VERSION ""

NS_ :

BS_:

BU_: ETH

BO_ 1009 RCM2_alertMatrix: 8 Vector__XXX
 SG_ RCM2_matrixIndex M : 0|4@1+ (1,0) [0|0] "" Vector__XXX
 SG_ RCM2_a000_crashDetected m0 : 4|1@1+ (1,0) [0|0] "" Vector__XXX
 SG_ RCM2_a089_pretenShldRightShort m1 : 4|1@1+ (1,0) [0|0] "" Vector__XXX
 SG_ RCM2_a149_curABLeftShort m2 : 4|1@1+ (1,0) [0|0] "" Vector__XXX
 SG_ RCM2_a209_sideAB2ndRowLShort m3 : 4|1@1+ (1,0) [0|0] "" Vector__XXX
 SG_ RCM2_a303_imuAccYHgMonChlTemp m4 : 4|1@1+ (1,0) [0|0] "" Vector__XXX
 SG_ RCM2_a393_sideAccelBPilLCLosCoup m5 : 4|1@1+ (1,0) [0|0] "" Vector__XXX
 SG_ RCM2_a457_presPedProLDefect m6 : 4|1@1+ (1,0) [0|0] "" Vector__XXX
 SG_ RCM2_a521_sideAccelDPilRCrssCoup m7 : 4|1@1+ (1,0) [0|0] "" Vector__XXX
 SG_ RCM2_a609_comDItorque1ChkSm m8 : 4|1@1+ (1,0) [0|0] "" Vector__XXX
 SG_ RCM2_a669_comEPBLstatusMIA m9 : 4|1@1+ (1,0) [0|0] "" Vector__XXX
 SG_ RCM2_a825_upFrntPedProMRSht2Bat m10 : 4|1@1+ (1,0) [0|0] "" Vector__XXX
 SG_ RCM2_a001_nearDeploy m0 : 5|1@1+ (1,0) [0|0] "" Vector__XXX
 SG_ RCM2_a090_pretenShldRightCrssCou m1 : 5|1@1+ (1,0) [0|0] "" Vector__XXX
 SG_ RCM2_a150_curABLeftCrssCoup m2 : 5|1@1+ (1,0) [0|0] "" Vector__XXX
 SG_ RCM2_a210_sideAB2ndRowLCrssCoup m3 : 5|1@1+ (1,0) [0|0] "" Vector__XXX
 SG_ RCM2_a304_imuYawR8SnsrPermBG m4 : 5|1@1+ (1,0) [0|0] "" Vector__XXX
 SG_ RCM2_a394_sideAccelBPilLCommErr m5 : 5|1@1+ (1,0) [0|0] "" Vector__XXX
 SG_ RCM2_a458_presPedProLSigMon m6 : 5|1@1+ (1,0) [0|0] "" Vector__XXX
 SG_ RCM2_a522_sideAccelDPilRCommErr m7 : 5|1@1+ (1,0) [0|0] "" Vector__XXX
 SG_ RCM2_a610_comDItorque1Cntr m8 : 5|1@1+ (1,0) [0|0] "" Vector__XXX
 SG_ RCM2_a670_comEPBLstatusChkSm m9 : 5|1@1+ (1,0) [0|0] "" Vector__XXX
 SG_ RCM2_a826_upFrntPedProMROpen m10 : 5|1@1+ (1,0) [0|0] "" Vector__XXX
 SG_ RCM2_a002_airbagsUnArmed m0 : 6|1@1+ (1,0) [0|0] "" Vector__XXX
 SG_ RCM2_a091_pretenShldRightConfig m1 : 6|1@1+ (1,0) [0|0] "" Vector__XXX
 SG_ RCM2_a151_curABLeftConfig m2 : 6|1@1+ (1,0) [0|0] "" Vector__XXX
 SG_ RCM2_a211_sideAB2ndRowLConfig m3 : 6|1@1+ (1,0) [0|0] "" Vector__XXX
 SG_ RCM2_a305_imuYawR8SnsrPermInit m4 : 6|1@1+ (1,0) [0|0] "" Vector__XXX
 SG_ RCM2_a395_sideAccelBPilLInitTyp m5 : 6|1@1+ (1,0) [0|0] "" Vector__XXX
 SG_ RCM2_a460_presPedProRSht2Gnd m6 : 6|1@1+ (1,0) [0|0] "" Vector__XXX
 SG_ RCM2_a523_sideAccelDPilRInitTyp m7 : 6|1@1+ (1,0) [0|0] "" Vector__XXX
 SG_ RCM2_a611_comDItorque2MIA m8 : 6|1@1+ (1,0) [0|0] "" Vector__XXX
 SG_ RCM2_a671_comEPBLstatusCntr m9 : 6|1@1+ (1,0) [0|0] "" Vector__XXX
 SG_ RCM2_a827_upFrntPedProMRCrssCoup m10 : 6|1@1+ (1,0) [0|0] "" Vector__XXX
 SG_ RCM2_a003_warningIndicator m0 : 7|1@1+ (1,0) [0|0] "" Vector__XXX
 SG_ RCM2_a092_pretenLapLeftSht2Gnd m1 : 7|1@1+ (1,0) [0|0] "" Vector__XXX
 SG_ RCM2_a152_curABRightSht2Gnd m2 : 7|1@1+ (1,0) [0|0] "" Vector__XXX
 SG_ RCM2_a212_sideAB2ndRowRSht2Gnd m3 : 7|1@1+ (1,0) [0|0] "" Vector__XXX
 SG_ RCM2_a306_imuYawR8SnsrPermLF m4 : 7|1@1+ (1,0) [0|0] "" Vector__XXX
 SG_ RCM2_a396_sideAccelBPilLConfig m5 : 7|1@1+ (1,0) [0|0] "" Vector__XXX
 SG_ RCM2_a461_presPedProRSht2Bat m6 : 7|1@1+ (1,0) [0|0] "" Vector__XXX
 SG_ RCM2_a524_sideAccelDPilRConfig m7 : 7|1@1+ (1,0) [0|0] "" Vector__XXX
 SG_ RCM2_a612_comDItorque2ChkSm m8 : 7|1@1+ (1,0) [0|0] "" Vector__XXX
 SG_ RCM2_a672_comEPBRstatusMIA m9 : 7|1@1+ (1,0) [0|0] "" Vector__XXX
 SG_ RCM2_a828_upFrntPedProMRCommErr m10 : 7|1@1+ (1,0) [0|0] "" Vector__XXX
 SG_ RCM2_a004_crashAlgoWakeup m0 : 8|1@1+ (1,0) [0|0] "" Vector__XXX
 SG_ RCM2_a093_pretenLapLeftSht2Bat m1 : 8|1@1+ (1,0) [0|0] "" Vector__XXX
 SG_ RCM2_a153_curABRightSht2Bat m2 : 8|1@1+ (1,0) [0|0] "" Vector__XXX
 SG_ RCM2_a213_sideAB2ndRowRSht2Bat m3 : 8|1@1+ (1,0) [0|0] "" Vector__XXX
 SG_ RCM2_a307_imuYawR8ChnlMonTmpLF m4 : 8|1@1+ (1,0) [0|0] "" Vector__XXX
 SG_ RCM2_a397_sideAccelBPilLDefect m5 : 8|1@1+ (1,0) [0|0] "" Vector__XXX
 SG_ RCM2_a462_presPedProROpen m6 : 8|1@1+ (1,0) [0|0] "" Vector__XXX
 SG_ RCM2_a525_sideAccelDPilRDefect m7 : 8|1@1+ (1,0) [0|0] "" Vector__XXX
 SG_ RCM2_a613_comDItorque2Cntr m8 : 8|1@1+ (1,0) [0|0] "" Vector__XXX
 SG_ RCM2_a673_comEPBRstatusChkSm m9 : 8|1@1+ (1,0) [0|0] "" Vector__XXX
 SG_ RCM2_a829_upFrntPedProMRIntTyp m10 : 8|1@1+ (1,0) [0|0] "" Vector__XXX
 SG_ RCM2_a005_abuseImmunityThrshold m0 : 9|1@1+ (1,0) [0|0] "" Vector__XXX
 SG_ RCM2_a094_pretenLapLeftOpen m1 : 9|1@1+ (1,0) [0|0] "" Vector__XXX
 SG_ RCM2_a154_curABRightOpen m2 : 9|1@1+ (1,0) [0|0] "" Vector__XXX
 SG_ RCM2_a214_sideAB2ndRowROpen m3 : 9|1@1+ (1,0) [0|0] "" Vector__XXX
 SG_ RCM2_a308_imuPitchR8SnsrPermBG m4 : 9|1@1+ (1,0) [0|0] "" Vector__XXX
 SG_ RCM2_a398_sideAccelBPilLSigMon m5 : 9|1@1+ (1,0) [0|0] "" Vector__XXX
 SG_ RCM2_a463_presPedProRCrssCoup m6 : 9|1@1+ (1,0) [0|0] "" Vector__XXX
 SG_ RCM2_a526_sideAccelDPilRSigMon m7 : 9|1@1+ (1,0) [0|0] "" Vector__XXX
 SG_ RCM2_a614_comESP135MIA m8 : 9|1@1+ (1,0) [0|0] "" Vector__XXX
 SG_ RCM2_a674_comEPBRstatusCntr m9 : 9|1@1+ (1,0) [0|0] "" Vector__XXX
 SG_ RCM2_a830_upFrntPedProMRConfig m10 : 9|1@1+ (1,0) [0|0] "" Vector__XXX
 SG_ RCM2_a006_supplierDiagEnabled m0 : 10|1@1+ (1,0) [0|0] "" Vector__XXX
 SG_ RCM2_a095_pretenLapLeftShort m1 : 10|1@1+ (1,0) [0|0] "" Vector__XXX
 SG_ RCM2_a155_curABRightShort m2 : 10|1@1+ (1,0) [0|0] "" Vector__XXX
 SG_ RCM2_a215_sideAB2ndRowRShort m3 : 10|1@1+ (1,0) [0|0] "" Vector__XXX
 SG_ RCM2_a309_imuPitchR8SnsrPermInit m4 : 10|1@1+ (1,0) [0|0] "" Vector__XXX
 SG_ RCM2_a400_sideAccelBPilRSht2Gnd m5 : 10|1@1+ (1,0) [0|0] "" Vector__XXX
 SG_ RCM2_a464_presPedProRCommErr m6 : 10|1@1+ (1,0) [0|0] "" Vector__XXX
 SG_ RCM2_a527_upFrntSnsrCSht2Gnd m7 : 10|1@1+ (1,0) [0|0] "" Vector__XXX
 SG_ RCM2_a615_comESP135ChkSm m8 : 10|1@1+ (1,0) [0|0] "" Vector__XXX
 SG_ RCM2_a675_comUIodoMIA m9 : 10|1@1+ (1,0) [0|0] "" Vector__XXX
 SG_ RCM2_a831_upFrntPedProMRDefect m10 : 10|1@1+ (1,0) [0|0] "" Vector__XXX
 SG_ RCM2_a007_pedProCrashDetected m0 : 11|1@1+ (1,0) [0|0] "" Vector__XXX
 SG_ RCM2_a096_pretenLapLeftCrssCoup m1 : 11|1@1+ (1,0) [0|0] "" Vector__XXX
 SG_ RCM2_a156_curABRightCrssCoup m2 : 11|1@1+ (1,0) [0|0] "" Vector__XXX
 SG_ RCM2_a216_sideAB2ndRowRCrssCoup m3 : 11|1@1+ (1,0) [0|0] "" Vector__XXX
 SG_ RCM2_a310_imuPitchR8SnsrPermLF m4 : 11|1@1+ (1,0) [0|0] "" Vector__XXX
 SG_ RCM2_a401_sideAccelBPilRSht2Bat m5 : 11|1@1+ (1,0) [0|0] "" Vector__XXX
 SG_ RCM2_a465_presPedProRInitTyp m6 : 11|1@1+ (1,0) [0|0] "" Vector__XXX
 SG_ RCM2_a528_upFrntSnsrCSht2Bat m7 : 11|1@1+ (1,0) [0|0] "" Vector__XXX
 SG_ RCM2_a616_comESP135Cntr m8 : 11|1@1+ (1,0) [0|0] "" Vector__XXX
 SG_ RCM2_a676_comEPAS3PsysMIA m9 : 11|1@1+ (1,0) [0|0] "" Vector__XXX
 SG_ RCM2_a832_upFrntPedProMRSigMon m10 : 11|1@1+ (1,0) [0|0] "" Vector__XXX
 SG_ RCM2_a008_factoryMode m0 : 12|1@1+ (1,0) [0|0] "" Vector__XXX
 SG_ RCM2_a097_pretenLapLeftConfig m1 : 12|1@1+ (1,0) [0|0] "" Vector__XXX
 SG_ RCM2_a157_curABRightConfig m2 : 12|1@1+ (1,0) [0|0] "" Vector__XXX
 SG_ RCM2_a217_sideAB2ndRowRConfig m3 : 12|1@1+ (1,0) [0|0] "" Vector__XXX
 SG_ RCM2_a311_imuPitchR8ChnlMonTmpLF m4 : 12|1@1+ (1,0) [0|0] "" Vector__XXX
 SG_ RCM2_a402_sideAccelBPilROpen m5 : 12|1@1+ (1,0) [0|0] "" Vector__XXX
 SG_ RCM2_a466_presPedProRConfig m6 : 12|1@1+ (1,0) [0|0] "" Vector__XXX
 SG_ RCM2_a529_upFrntSnsrCOpen m7 : 12|1@1+ (1,0) [0|0] "" Vector__XXX
 SG_ RCM2_a617_comESP145MIA m8 : 12|1@1+ (1,0) [0|0] "" Vector__XXX
 SG_ RCM2_a677_comEPAS3PsysChkSm m9 : 12|1@1+ (1,0) [0|0] "" Vector__XXX
 SG_ RCM2_a833_pretenShldCSht2Gnd m10 : 12|1@1+ (1,0) [0|0] "" Vector__XXX
 SG_ RCM2_a009_edrDataAreaLocked m0 : 13|1@1+ (1,0) [0|0] "" Vector__XXX
 SG_ RCM2_a098_pretenLapRightSht2Gnd m1 : 13|1@1+ (1,0) [0|0] "" Vector__XXX
 SG_ RCM2_a158_preten2ndRowLSht2Gnd m2 : 13|1@1+ (1,0) [0|0] "" Vector__XXX
 SG_ RCM2_a250_ens1Sht2Bat m3 : 13|1@1+ (1,0) [0|0] "" Vector__XXX
 SG_ RCM2_a312_imuRollR8SnsrPermBG m4 : 13|1@1+ (1,0) [0|0] "" Vector__XXX
 SG_ RCM2_a403_sideAccelBPilRCrssCoup m5 : 13|1@1+ (1,0) [0|0] "" Vector__XXX
 SG_ RCM2_a467_presPedProRDefect m6 : 13|1@1+ (1,0) [0|0] "" Vector__XXX
 SG_ RCM2_a530_upFrntSnsrCCrssCoup m7 : 13|1@1+ (1,0) [0|0] "" Vector__XXX
 SG_ RCM2_a618_comESP145ChkSm m8 : 13|1@1+ (1,0) [0|0] "" Vector__XXX
 SG_ RCM2_a678_comEPAS3PsysCntr m9 : 13|1@1+ (1,0) [0|0] "" Vector__XXX
 SG_ RCM2_a834_pretenShldCSht2Bat m10 : 13|1@1+ (1,0) [0|0] "" Vector__XXX
 SG_ RCM2_a010_pedProEDRDataLocked m0 : 14|1@1+ (1,0) [0|0] "" Vector__XXX
 SG_ RCM2_a099_pretenLapRightSht2Bat m1 : 14|1@1+ (1,0) [0|0] "" Vector__XXX
 SG_ RCM2_a159_preten2ndRowLSht2Bat m2 : 14|1@1+ (1,0) [0|0] "" Vector__XXX
 SG_ RCM2_a251_ens1Sht2Gnd m3 : 14|1@1+ (1,0) [0|0] "" Vector__XXX
 SG_ RCM2_a313_imuRollR8SnsrPermInit m4 : 14|1@1+ (1,0) [0|0] "" Vector__XXX
 SG_ RCM2_a404_sideAccelBPilRCommErr m5 : 14|1@1+ (1,0) [0|0] "" Vector__XXX
 SG_ RCM2_a468_presPedProRSigMon m6 : 14|1@1+ (1,0) [0|0] "" Vector__XXX
 SG_ RCM2_a531_upFrntSnsrCCommErr m7 : 14|1@1+ (1,0) [0|0] "" Vector__XXX
 SG_ RCM2_a619_comESP145Cntr m8 : 14|1@1+ (1,0) [0|0] "" Vector__XXX
 SG_ RCM2_a679_comESPwheelSpeedsMIA m9 : 14|1@1+ (1,0) [0|0] "" Vector__XXX
 SG_ RCM2_a835_pretenShldCOpen m10 : 14|1@1+ (1,0) [0|0] "" Vector__XXX
 SG_ RCM2_a011_placeholder0 m0 : 15|1@1+ (1,0) [0|0] "" Vector__XXX
 SG_ RCM2_a100_pretenLapRightOpen m1 : 15|1@1+ (1,0) [0|0] "" Vector__XXX
 SG_ RCM2_a160_preten2ndRowLOpen m2 : 15|1@1+ (1,0) [0|0] "" Vector__XXX
 SG_ RCM2_a252_ens1Config m3 : 15|1@1+ (1,0) [0|0] "" Vector__XXX
 SG_ RCM2_a314_imuRollR8SnsrPermLF m4 : 15|1@1+ (1,0) [0|0] "" Vector__XXX
 SG_ RCM2_a405_sideAccelBPilRInitTyp m5 : 15|1@1+ (1,0) [0|0] "" Vector__XXX
 SG_ RCM2_a469_presPedProAbsolute m6 : 15|1@1+ (1,0) [0|0] "" Vector__XXX
 SG_ RCM2_a532_upFrntSnsrCInitTyp m7 : 15|1@1+ (1,0) [0|0] "" Vector__XXX
 SG_ RCM2_a620_comInvalidVehicleSpeed m8 : 15|1@1+ (1,0) [0|0] "" Vector__XXX
 SG_ RCM2_a680_comESPwheelSpeedsChkSm m9 : 15|1@1+ (1,0) [0|0] "" Vector__XXX
 SG_ RCM2_a836_pretenShldCShort m10 : 15|1@1+ (1,0) [0|0] "" Vector__XXX
 SG_ RCM2_a012_placeholder1 m0 : 16|1@1+ (1,0) [0|0] "" Vector__XXX
 SG_ RCM2_a101_pretenLapRightShort m1 : 16|1@1+ (1,0) [0|0] "" Vector__XXX
 SG_ RCM2_a161_preten2ndRowLShort m2 : 16|1@1+ (1,0) [0|0] "" Vector__XXX
 SG_ RCM2_a253_ens2Sht2Bat m3 : 16|1@1+ (1,0) [0|0] "" Vector__XXX
 SG_ RCM2_a315_imuRollR8ChnlMonTmpLF m4 : 16|1@1+ (1,0) [0|0] "" Vector__XXX
 SG_ RCM2_a406_sideAccelBPilRConfig m5 : 16|1@1+ (1,0) [0|0] "" Vector__XXX
 SG_ RCM2_a470_upFrntPedProLSht2Gnd m6 : 16|1@1+ (1,0) [0|0] "" Vector__XXX
 SG_ RCM2_a533_upFrntSnsrCConfig m7 : 16|1@1+ (1,0) [0|0] "" Vector__XXX
 SG_ RCM2_a621_comESPBMIA m8 : 16|1@1+ (1,0) [0|0] "" Vector__XXX
 SG_ RCM2_a681_comESPwheelSpeedsCntr m9 : 16|1@1+ (1,0) [0|0] "" Vector__XXX
 SG_ RCM2_a837_pretenShldCCrossC m10 : 16|1@1+ (1,0) [0|0] "" Vector__XXX
 SG_ RCM2_a013_placeholder2 m0 : 17|1@1+ (1,0) [0|0] "" Vector__XXX
 SG_ RCM2_a102_pretenLapRightCrssCoup m1 : 17|1@1+ (1,0) [0|0] "" Vector__XXX
 SG_ RCM2_a162_preten2ndRowLCrssCoup m2 : 17|1@1+ (1,0) [0|0] "" Vector__XXX
 SG_ RCM2_a254_ens2Sht2Gnd m3 : 17|1@1+ (1,0) [0|0] "" Vector__XXX
 SG_ RCM2_a316_imuAccXLgMonChlPerm m4 : 17|1@1+ (1,0) [0|0] "" Vector__XXX
 SG_ RCM2_a407_sideAccelBPilRDefect m5 : 17|1@1+ (1,0) [0|0] "" Vector__XXX
 SG_ RCM2_a471_upFrntPedProLSht2Bat m6 : 17|1@1+ (1,0) [0|0] "" Vector__XXX
 SG_ RCM2_a534_upFrntSnsrCDefect m7 : 17|1@1+ (1,0) [0|0] "" Vector__XXX
 SG_ RCM2_a622_comESPBChkSm m8 : 17|1@1+ (1,0) [0|0] "" Vector__XXX
 SG_ RCM2_a682_comDIspeedMIA m9 : 17|1@1+ (1,0) [0|0] "" Vector__XXX
 SG_ RCM2_a838_pretenShldCConfig m10 : 17|1@1+ (1,0) [0|0] "" Vector__XXX
 SG_ RCM2_a014_pedProNearDeploy m0 : 18|1@1+ (1,0) [0|0] "" Vector__XXX
 SG_ RCM2_a103_pretenLapRightConfig m1 : 18|1@1+ (1,0) [0|0] "" Vector__XXX
 SG_ RCM2_a163_preten2ndRowLCgf m2 : 18|1@1+ (1,0) [0|0] "" Vector__XXX
 SG_ RCM2_a255_ens2Config m3 : 18|1@1+ (1,0) [0|0] "" Vector__XXX
 SG_ RCM2_a317_imuAccXLgMonChlTemp m4 : 18|1@1+ (1,0) [0|0] "" Vector__XXX
 SG_ RCM2_a408_sideAccelBPilRSigMon m5 : 18|1@1+ (1,0) [0|0] "" Vector__XXX
 SG_ RCM2_a472_upFrntPedProLOpen m6 : 18|1@1+ (1,0) [0|0] "" Vector__XXX
 SG_ RCM2_a535_upFrntSnsrCSigMon m7 : 18|1@1+ (1,0) [0|0] "" Vector__XXX
 SG_ RCM2_a623_comESPBCntr m8 : 18|1@1+ (1,0) [0|0] "" Vector__XXX
 SG_ RCM2_a683_comDIspeedChkSm m9 : 18|1@1+ (1,0) [0|0] "" Vector__XXX
 SG_ RCM2_a839_preten2ndRowCSht2Gnd m10 : 18|1@1+ (1,0) [0|0] "" Vector__XXX
 SG_ RCM2_a015_noDeployCrashCal m0 : 19|1@1+ (1,0) [0|0] "" Vector__XXX
 SG_ RCM2_a104_loadLimLeftSht2Gnd m1 : 19|1@1+ (1,0) [0|0] "" Vector__XXX
 SG_ RCM2_a164_preten2ndRowRSht2Gnd m2 : 19|1@1+ (1,0) [0|0] "" Vector__XXX
 SG_ RCM2_a256_ens3Sht2Bat m3 : 19|1@1+ (1,0) [0|0] "" Vector__XXX
 SG_ RCM2_a318_imuAccYLgMonChlPerm m4 : 19|1@1+ (1,0) [0|0] "" Vector__XXX
 SG_ RCM2_a410_sideAccelCPilLSht2Gnd m5 : 19|1@1+ (1,0) [0|0] "" Vector__XXX
 SG_ RCM2_a473_upFrntPedProLCrssCoup m6 : 19|1@1+ (1,0) [0|0] "" Vector__XXX
 SG_ RCM2_a550_bucklHallLeftSht2Gnd m7 : 19|1@1+ (1,0) [0|0] "" Vector__XXX
 SG_ RCM2_a624_comESPCMIA m8 : 19|1@1+ (1,0) [0|0] "" Vector__XXX
 SG_ RCM2_a684_comDIspeedCntr m9 : 19|1@1+ (1,0) [0|0] "" Vector__XXX
 SG_ RCM2_a840_preten2ndRowCSht2Bat m10 : 19|1@1+ (1,0) [0|0] "" Vector__XXX
 SG_ RCM2_a016_noDeployPedProCal m0 : 20|1@1+ (1,0) [0|0] "" Vector__XXX
 SG_ RCM2_a105_loadLimLeftSht2Bat m1 : 20|1@1+ (1,0) [0|0] "" Vector__XXX
 SG_ RCM2_a165_preten2ndRowRSht2Bat m2 : 20|1@1+ (1,0) [0|0] "" Vector__XXX
 SG_ RCM2_a257_ens3Sht2Gnd m3 : 20|1@1+ (1,0) [0|0] "" Vector__XXX
 SG_ RCM2_a319_imuAccYLgMonChlTemp m4 : 20|1@1+ (1,0) [0|0] "" Vector__XXX
 SG_ RCM2_a411_sideAccelCPilLSht2Bat m5 : 20|1@1+ (1,0) [0|0] "" Vector__XXX
 SG_ RCM2_a474_upFrntPedProLCommErr m6 : 20|1@1+ (1,0) [0|0] "" Vector__XXX
 SG_ RCM2_a551_bucklHallLeftSht2Bat m7 : 20|1@1+ (1,0) [0|0] "" Vector__XXX
 SG_ RCM2_a625_comESPCChkSm m8 : 20|1@1+ (1,0) [0|0] "" Vector__XXX
 SG_ RCM2_a685_comDIchassControlMIA m9 : 20|1@1+ (1,0) [0|0] "" Vector__XXX
 SG_ RCM2_a841_preten2ndRowCOpen m10 : 20|1@1+ (1,0) [0|0] "" Vector__XXX
 SG_ RCM2_a017_ecuLogAvailable m0 : 21|1@1+ (1,0) [0|0] "" Vector__XXX
 SG_ RCM2_a106_loadLimLeftOpen m1 : 21|1@1+ (1,0) [0|0] "" Vector__XXX
 SG_ RCM2_a166_preten2ndRowROpen m2 : 21|1@1+ (1,0) [0|0] "" Vector__XXX
 SG_ RCM2_a258_ens3Config m3 : 21|1@1+ (1,0) [0|0] "" Vector__XXX
 SG_ RCM2_a320_imuAccZLgMonChlPerm m4 : 21|1@1+ (1,0) [0|0] "" Vector__XXX
 SG_ RCM2_a412_sideAccelCPilLOpen m5 : 21|1@1+ (1,0) [0|0] "" Vector__XXX
 SG_ RCM2_a475_upFrntPedProLIntTyp m6 : 21|1@1+ (1,0) [0|0] "" Vector__XXX
 SG_ RCM2_a552_bucklHallLeftOpen m7 : 21|1@1+ (1,0) [0|0] "" Vector__XXX
 SG_ RCM2_a626_comESPCCntr m8 : 21|1@1+ (1,0) [0|0] "" Vector__XXX
 SG_ RCM2_a686_comDIchassControlChkSm m9 : 21|1@1+ (1,0) [0|0] "" Vector__XXX
 SG_ RCM2_a842_preten2ndRowCShort m10 : 21|1@1+ (1,0) [0|0] "" Vector__XXX
 SG_ RCM2_a047_batteryESRhigh m0 : 22|1@1+ (1,0) [0|0] "" Vector__XXX
 SG_ RCM2_a107_loadLimLeftShort m1 : 22|1@1+ (1,0) [0|0] "" Vector__XXX
 SG_ RCM2_a167_preten2ndRowRShort m2 : 22|1@1+ (1,0) [0|0] "" Vector__XXX
 SG_ RCM2_a259_ens4Sht2Bat m3 : 22|1@1+ (1,0) [0|0] "" Vector__XXX
 SG_ RCM2_a321_imuAccZLgMonChlTemp m4 : 22|1@1+ (1,0) [0|0] "" Vector__XXX
 SG_ RCM2_a413_sideAccelCPilLCrssCoup m5 : 22|1@1+ (1,0) [0|0] "" Vector__XXX
 SG_ RCM2_a476_upFrntPedProLConfig m6 : 22|1@1+ (1,0) [0|0] "" Vector__XXX
 SG_ RCM2_a553_bucklHallLeftUndef m7 : 22|1@1+ (1,0) [0|0] "" Vector__XXX
 SG_ RCM2_a627_comEPBStatusMIA m8 : 22|1@1+ (1,0) [0|0] "" Vector__XXX
 SG_ RCM2_a687_comDIchassControlCntr m9 : 22|1@1+ (1,0) [0|0] "" Vector__XXX
 SG_ RCM2_a843_preten2ndRowCCrssCoup m10 : 22|1@1+ (1,0) [0|0] "" Vector__XXX
 SG_ RCM2_a048_batteryVoltageTooHigh m0 : 23|1@1+ (1,0) [0|0] "" Vector__XXX
 SG_ RCM2_a108_loadLimLeftCrssCoup m1 : 23|1@1+ (1,0) [0|0] "" Vector__XXX
 SG_ RCM2_a168_preten2ndRowRCrssCoup m2 : 23|1@1+ (1,0) [0|0] "" Vector__XXX
 SG_ RCM2_a260_ens4Sht2Gnd m3 : 23|1@1+ (1,0) [0|0] "" Vector__XXX
 SG_ RCM2_a322_imuCalibrationFailed m4 : 23|1@1+ (1,0) [0|0] "" Vector__XXX
 SG_ RCM2_a414_sideAccelCPilLCommErr m5 : 23|1@1+ (1,0) [0|0] "" Vector__XXX
 SG_ RCM2_a477_upFrntPedProLDefect m6 : 23|1@1+ (1,0) [0|0] "" Vector__XXX
 SG_ RCM2_a554_bucklHallLeftCrssCoup m7 : 23|1@1+ (1,0) [0|0] "" Vector__XXX
 SG_ RCM2_a628_comEPBStatusChkSm m8 : 23|1@1+ (1,0) [0|0] "" Vector__XXX
 SG_ RCM2_a688_comVCLEFTrestMIA m9 : 23|1@1+ (1,0) [0|0] "" Vector__XXX
 SG_ RCM2_a844_preten2ndRowCConfig m10 : 23|1@1+ (1,0) [0|0] "" Vector__XXX
 SG_ RCM2_a049_batteryVoltageTooLow m0 : 24|1@1+ (1,0) [0|0] "" Vector__XXX
 SG_ RCM2_a109_loadLimLeftConfig m1 : 24|1@1+ (1,0) [0|0] "" Vector__XXX
 SG_ RCM2_a169_preten2ndRowRCgf m2 : 24|1@1+ (1,0) [0|0] "" Vector__XXX
 SG_ RCM2_a261_ens4Config m3 : 24|1@1+ (1,0) [0|0] "" Vector__XXX
 SG_ RCM2_a323_imuCalibrationNotDone m4 : 24|1@1+ (1,0) [0|0] "" Vector__XXX
 SG_ RCM2_a415_sideAccelCPilLInitTyp m5 : 24|1@1+ (1,0) [0|0] "" Vector__XXX
 SG_ RCM2_a478_upFrntPedProLSigMon m6 : 24|1@1+ (1,0) [0|0] "" Vector__XXX
 SG_ RCM2_a555_bucklHallLeftConfig m7 : 24|1@1+ (1,0) [0|0] "" Vector__XXX
 SG_ RCM2_a629_comEPBStatusCntr m8 : 24|1@1+ (1,0) [0|0] "" Vector__XXX
 SG_ RCM2_a689_comVCLEFTrestChkSm m9 : 24|1@1+ (1,0) [0|0] "" Vector__XXX
 SG_ RCM2_a845_comUIchassisControlMIA m10 : 24|1@1+ (1,0) [0|0] "" Vector__XXX
 SG_ RCM2_a050_driverABStg1Sht2Gnd m0 : 25|1@1+ (1,0) [0|0] "" Vector__XXX
 SG_ RCM2_a110_loadLimRightSht2Gnd m1 : 25|1@1+ (1,0) [0|0] "" Vector__XXX
 SG_ RCM2_a170_curAB2ndRowLSht2Gnd m2 : 25|1@1+ (1,0) [0|0] "" Vector__XXX
 SG_ RCM2_a264_imuYawR8OffCompPosLife m3 : 25|1@1+ (1,0) [0|0] "" Vector__XXX
 SG_ RCM2_a350_upFrntSnsrLSht2Gnd m4 : 25|1@1+ (1,0) [0|0] "" Vector__XXX
 SG_ RCM2_a416_sideAccelCPilLConfig m5 : 25|1@1+ (1,0) [0|0] "" Vector__XXX
 SG_ RCM2_a480_upFrntPedProRSht2Gnd m6 : 25|1@1+ (1,0) [0|0] "" Vector__XXX
 SG_ RCM2_a556_bucklHallRightSht2Gnd m7 : 25|1@1+ (1,0) [0|0] "" Vector__XXX
 SG_ RCM2_a630_comGTWACSMIA m8 : 25|1@1+ (1,0) [0|0] "" Vector__XXX
 SG_ RCM2_a690_comVCLEFTrestCntr m9 : 25|1@1+ (1,0) [0|0] "" Vector__XXX
 SG_ RCM2_a846_comSCCMstrAnglSnsMIA m10 : 25|1@1+ (1,0) [0|0] "" Vector__XXX
 SG_ RCM2_a051_driverABStg1Sht2Bat m0 : 26|1@1+ (1,0) [0|0] "" Vector__XXX
 SG_ RCM2_a111_loadLimRightSht2Bat m1 : 26|1@1+ (1,0) [0|0] "" Vector__XXX
 SG_ RCM2_a171_curAB2ndRowLSht2Bat m2 : 26|1@1+ (1,0) [0|0] "" Vector__XXX
 SG_ RCM2_a265_imuYawR8OffCompNegLife m3 : 26|1@1+ (1,0) [0|0] "" Vector__XXX
 SG_ RCM2_a351_upFrntSnsrLSht2Bat m4 : 26|1@1+ (1,0) [0|0] "" Vector__XXX
 SG_ RCM2_a417_sideAccelCPilLDefect m5 : 26|1@1+ (1,0) [0|0] "" Vector__XXX
 SG_ RCM2_a481_upFrntPedProRSht2Bat m6 : 26|1@1+ (1,0) [0|0] "" Vector__XXX
 SG_ RCM2_a557_bucklHallRightSht2Bat m7 : 26|1@1+ (1,0) [0|0] "" Vector__XXX
 SG_ RCM2_a631_comGTWACSChkSm m8 : 26|1@1+ (1,0) [0|0] "" Vector__XXX
 SG_ RCM2_a691_comVCLEFT1rLBuckle m9 : 26|1@1+ (1,0) [0|0] "" Vector__XXX
 SG_ RCM2_a847_comDASctrlMIA m10 : 26|1@1+ (1,0) [0|0] "" Vector__XXX
 SG_ RCM2_a052_driverABStg1Open m0 : 27|1@1+ (1,0) [0|0] "" Vector__XXX
 SG_ RCM2_a112_loadLimRightOpen m1 : 27|1@1+ (1,0) [0|0] "" Vector__XXX
 SG_ RCM2_a172_curAB2ndRowLOpen m2 : 27|1@1+ (1,0) [0|0] "" Vector__XXX
 SG_ RCM2_a266_imuYawR8OffCompPosFLDC m3 : 27|1@1+ (1,0) [0|0] "" Vector__XXX
 SG_ RCM2_a352_upFrntSnsrLOpen m4 : 27|1@1+ (1,0) [0|0] "" Vector__XXX
 SG_ RCM2_a418_sideAccelCPilLSigMon m5 : 27|1@1+ (1,0) [0|0] "" Vector__XXX
 SG_ RCM2_a482_upFrntPedProROpen m6 : 27|1@1+ (1,0) [0|0] "" Vector__XXX
 SG_ RCM2_a558_bucklHallRightOpen m7 : 27|1@1+ (1,0) [0|0] "" Vector__XXX
 SG_ RCM2_a632_comGTWACSCntr m8 : 27|1@1+ (1,0) [0|0] "" Vector__XXX
 SG_ RCM2_a692_comVCLEFT2rLBuckle m9 : 27|1@1+ (1,0) [0|0] "" Vector__XXX
 SG_ RCM2_a848_comDIlocStatMIA m10 : 27|1@1+ (1,0) [0|0] "" Vector__XXX
 SG_ RCM2_a053_driverABStg1Short m0 : 28|1@1+ (1,0) [0|0] "" Vector__XXX
 SG_ RCM2_a113_loadLimRightShort m1 : 28|1@1+ (1,0) [0|0] "" Vector__XXX
 SG_ RCM2_a173_curAB2ndRowLShort m2 : 28|1@1+ (1,0) [0|0] "" Vector__XXX
 SG_ RCM2_a267_imuYawR8OffCompNegFLDC m3 : 28|1@1+ (1,0) [0|0] "" Vector__XXX
 SG_ RCM2_a353_upFrntSnsrLCrssCoup m4 : 28|1@1+ (1,0) [0|0] "" Vector__XXX
 SG_ RCM2_a420_sideAccelCPilRSht2Gnd m5 : 28|1@1+ (1,0) [0|0] "" Vector__XXX
 SG_ RCM2_a483_upFrntPedProRCrssCoup m6 : 28|1@1+ (1,0) [0|0] "" Vector__XXX
 SG_ RCM2_a559_bucklHallRightUndef m7 : 28|1@1+ (1,0) [0|0] "" Vector__XXX
 SG_ RCM2_a633_comOCS1PMIA m8 : 28|1@1+ (1,0) [0|0] "" Vector__XXX
 SG_ RCM2_a693_comVCLEFT1rLSTPS m9 : 28|1@1+ (1,0) [0|0] "" Vector__XXX
 SG_ RCM2_a849_comIBSTparty1MIA m10 : 28|1@1+ (1,0) [0|0] "" Vector__XXX
 SG_ RCM2_a054_driverABStg1CrssCoup m0 : 29|1@1+ (1,0) [0|0] "" Vector__XXX
 SG_ RCM2_a114_loadLimRightCrssCoup m1 : 29|1@1+ (1,0) [0|0] "" Vector__XXX
 SG_ RCM2_a174_curAB2ndRowLCrssCoup m2 : 29|1@1+ (1,0) [0|0] "" Vector__XXX
 SG_ RCM2_a268_imuYawR8OffCompPosSLDC m3 : 29|1@1+ (1,0) [0|0] "" Vector__XXX
 SG_ RCM2_a354_upFrntSnsrLCommErr m4 : 29|1@1+ (1,0) [0|0] "" Vector__XXX
 SG_ RCM2_a421_sideAccelCPilRSht2Bat m5 : 29|1@1+ (1,0) [0|0] "" Vector__XXX
 SG_ RCM2_a484_upFrntPedProRCommErr m6 : 29|1@1+ (1,0) [0|0] "" Vector__XXX
 SG_ RCM2_a560_bucklHallRightCrssCoup m7 : 29|1@1+ (1,0) [0|0] "" Vector__XXX
 SG_ RCM2_a634_comOCS1PChkSm m8 : 29|1@1+ (1,0) [0|0] "" Vector__XXX
 SG_ RCM2_a694_comVCRIGHTrestMIA m9 : 29|1@1+ (1,0) [0|0] "" Vector__XXX
 SG_ RCM2_a850_comVCFRONTlightingMIA m10 : 29|1@1+ (1,0) [0|0] "" Vector__XXX
 SG_ RCM2_a055_driverABStg1Config m0 : 30|1@1+ (1,0) [0|0] "" Vector__XXX
 SG_ RCM2_a115_loadLimRightConfig m1 : 30|1@1+ (1,0) [0|0] "" Vector__XXX
 SG_ RCM2_a175_curAB2ndRowLConfig m2 : 30|1@1+ (1,0) [0|0] "" Vector__XXX
 SG_ RCM2_a269_imuYawR8OffCompNegSLDC m3 : 30|1@1+ (1,0) [0|0] "" Vector__XXX
 SG_ RCM2_a355_upFrntSnsrLInitTyp m4 : 30|1@1+ (1,0) [0|0] "" Vector__XXX
 SG_ RCM2_a422_sideAccelCPilROpen m5 : 30|1@1+ (1,0) [0|0] "" Vector__XXX
 SG_ RCM2_a485_upFrntPedProRIntTyp m6 : 30|1@1+ (1,0) [0|0] "" Vector__XXX
 SG_ RCM2_a561_bucklHallRightConfig m7 : 30|1@1+ (1,0) [0|0] "" Vector__XXX
 SG_ RCM2_a635_comOCS1PCntr m8 : 30|1@1+ (1,0) [0|0] "" Vector__XXX
 SG_ RCM2_a695_comVCRIGHTrestChkSm m9 : 30|1@1+ (1,0) [0|0] "" Vector__XXX
 SG_ RCM2_a851_internalFaultTemp m10 : 30|1@1+ (1,0) [0|0] "" Vector__XXX
 SG_ RCM2_a056_driverABStg2Sht2Gnd m0 : 31|1@1+ (1,0) [0|0] "" Vector__XXX
 SG_ RCM2_a116_kneeABDrvrSht2Gnd m1 : 31|1@1+ (1,0) [0|0] "" Vector__XXX
 SG_ RCM2_a176_curAB2ndRowRSht2Gnd m2 : 31|1@1+ (1,0) [0|0] "" Vector__XXX
 SG_ RCM2_a270_imuPtchR8OffCompPosLife m3 : 31|1@1+ (1,0) [0|0] "" Vector__XXX
 SG_ RCM2_a356_upFrntSnsrLConfig m4 : 31|1@1+ (1,0) [0|0] "" Vector__XXX
 SG_ RCM2_a423_sideAccelCPilRCrssCoup m5 : 31|1@1+ (1,0) [0|0] "" Vector__XXX
 SG_ RCM2_a486_upFrntPedProRConfig m6 : 31|1@1+ (1,0) [0|0] "" Vector__XXX
 SG_ RCM2_a562_seaTrkPosLeftSht2Gnd m7 : 31|1@1+ (1,0) [0|0] "" Vector__XXX
 SG_ RCM2_a636_ocsFaulted m8 : 31|1@1+ (1,0) [0|0] "" Vector__XXX
 SG_ RCM2_a696_comVCRIGHTrestCntr m9 : 31|1@1+ (1,0) [0|0] "" Vector__XXX
 SG_ RCM2_a852_autarkyEvent m10 : 31|1@1+ (1,0) [0|0] "" Vector__XXX
 SG_ RCM2_a057_driverABStg2Sht2Bat m0 : 32|1@1+ (1,0) [0|0] "" Vector__XXX
 SG_ RCM2_a117_kneeABDrvrSht2Bat m1 : 32|1@1+ (1,0) [0|0] "" Vector__XXX
 SG_ RCM2_a177_curAB2ndRowRSht2Bat m2 : 32|1@1+ (1,0) [0|0] "" Vector__XXX
 SG_ RCM2_a271_imuPtchR8OffCompNegLife m3 : 32|1@1+ (1,0) [0|0] "" Vector__XXX
 SG_ RCM2_a357_upFrntSnsrLDefect m4 : 32|1@1+ (1,0) [0|0] "" Vector__XXX
 SG_ RCM2_a424_sideAccelCPilRCommErr m5 : 32|1@1+ (1,0) [0|0] "" Vector__XXX
 SG_ RCM2_a487_upFrntPedProRDefect m6 : 32|1@1+ (1,0) [0|0] "" Vector__XXX
 SG_ RCM2_a563_seaTrkPosLeftShtBat m7 : 32|1@1+ (1,0) [0|0] "" Vector__XXX
 SG_ RCM2_a637_ocsUnknown m8 : 32|1@1+ (1,0) [0|0] "" Vector__XXX
 SG_ RCM2_a697_comVCRIGHT1rRBuckle m9 : 32|1@1+ (1,0) [0|0] "" Vector__XXX
 SG_ RCM2_a853_ConfigParametersInconsistent m10 : 32|1@1+ (1,0) [0|0] "" Vector__XXX
 SG_ RCM2_a058_driverABStg2Open m0 : 33|1@1+ (1,0) [0|0] "" Vector__XXX
 SG_ RCM2_a118_kneeABDrvrOpen m1 : 33|1@1+ (1,0) [0|0] "" Vector__XXX
 SG_ RCM2_a178_curAB2ndRowROpen m2 : 33|1@1+ (1,0) [0|0] "" Vector__XXX
 SG_ RCM2_a272_imuPtchR8OffCompPosFLDC m3 : 33|1@1+ (1,0) [0|0] "" Vector__XXX
 SG_ RCM2_a358_upFrntSnsrLSigMon m4 : 33|1@1+ (1,0) [0|0] "" Vector__XXX
 SG_ RCM2_a425_sideAccelCPilRInitTyp m5 : 33|1@1+ (1,0) [0|0] "" Vector__XXX
 SG_ RCM2_a488_upFrntPedProRSigMon m6 : 33|1@1+ (1,0) [0|0] "" Vector__XXX
 SG_ RCM2_a564_seaTrkPosLeftOpen m7 : 33|1@1+ (1,0) [0|0] "" Vector__XXX
 SG_ RCM2_a638_comGTWodoMIA m8 : 33|1@1+ (1,0) [0|0] "" Vector__XXX
 SG_ RCM2_a698_comVCRIGHT2rRBuckle m9 : 33|1@1+ (1,0) [0|0] "" Vector__XXX
 SG_ RCM2_a854_ConfigParametersNotLearned m10 : 33|1@1+ (1,0) [0|0] "" Vector__XXX
 SG_ RCM2_a059_driverABStg2Short m0 : 34|1@1+ (1,0) [0|0] "" Vector__XXX
 SG_ RCM2_a119_kneeABDrvrShort m1 : 34|1@1+ (1,0) [0|0] "" Vector__XXX
 SG_ RCM2_a179_curAB2ndRowRShort m2 : 34|1@1+ (1,0) [0|0] "" Vector__XXX
 SG_ RCM2_a273_imuPtchR8OffCompNegFLDC m3 : 34|1@1+ (1,0) [0|0] "" Vector__XXX
 SG_ RCM2_a360_upFrntSnsrRSht2Gnd m4 : 34|1@1+ (1,0) [0|0] "" Vector__XXX
 SG_ RCM2_a426_sideAccelCPilRConfig m5 : 34|1@1+ (1,0) [0|0] "" Vector__XXX
 SG_ RCM2_a490_presRearLDoorSht2Gnd m6 : 34|1@1+ (1,0) [0|0] "" Vector__XXX
 SG_ RCM2_a565_seaTrkPosLeftUndefined m7 : 34|1@1+ (1,0) [0|0] "" Vector__XXX
 SG_ RCM2_a639_comGTWCarStateMIA m8 : 34|1@1+ (1,0) [0|0] "" Vector__XXX
 SG_ RCM2_a699_comVCRIGHTocs m9 : 34|1@1+ (1,0) [0|0] "" Vector__XXX
 SG_ RCM2_a857_comVCLEFT2rCBuckle m10 : 34|1@1+ (1,0) [0|0] "" Vector__XXX
 SG_ RCM2_a060_driverABStg2CrssCoup m0 : 35|1@1+ (1,0) [0|0] "" Vector__XXX
 SG_ RCM2_a120_kneeABDrvrCrssCoup m1 : 35|1@1+ (1,0) [0|0] "" Vector__XXX
 SG_ RCM2_a180_curAB2ndRowRCrssCoup m2 : 35|1@1+ (1,0) [0|0] "" Vector__XXX
 SG_ RCM2_a274_imuPtchR8OffCompPosSLDC m3 : 35|1@1+ (1,0) [0|0] "" Vector__XXX
 SG_ RCM2_a361_upFrntSnsrRSht2Bat m4 : 35|1@1+ (1,0) [0|0] "" Vector__XXX
 SG_ RCM2_a427_sideAccelCPilRDefect m5 : 35|1@1+ (1,0) [0|0] "" Vector__XXX
 SG_ RCM2_a491_presRearLDoorSht2Bat m6 : 35|1@1+ (1,0) [0|0] "" Vector__XXX
 SG_ RCM2_a566_seaTrkPosLeftCrssCoup m7 : 35|1@1+ (1,0) [0|0] "" Vector__XXX
 SG_ RCM2_a640_comTPMSStatusCMIA m8 : 35|1@1+ (1,0) [0|0] "" Vector__XXX
 SG_ RCM2_a700_comVCRIGHT1rRSTPS m9 : 35|1@1+ (1,0) [0|0] "" Vector__XXX
 SG_ RCM2_a858_comVCxLVPowerStateMIA m10 : 35|1@1+ (1,0) [0|0] "" Vector__XXX
 SG_ RCM2_a061_driverABStg2Config m0 : 36|1@1+ (1,0) [0|0] "" Vector__XXX
 SG_ RCM2_a121_kneeABDrvrConfig m1 : 36|1@1+ (1,0) [0|0] "" Vector__XXX
 SG_ RCM2_a181_curAB2ndRowRConfig m2 : 36|1@1+ (1,0) [0|0] "" Vector__XXX
 SG_ RCM2_a275_imuPtchR8OffCompNegSLDC m3 : 36|1@1+ (1,0) [0|0] "" Vector__XXX
 SG_ RCM2_a362_upFrntSnsrROpen m4 : 36|1@1+ (1,0) [0|0] "" Vector__XXX
 SG_ RCM2_a428_sideAccelCPilRSigMon m5 : 36|1@1+ (1,0) [0|0] "" Vector__XXX
 SG_ RCM2_a492_presRearLDoorOpen m6 : 36|1@1+ (1,0) [0|0] "" Vector__XXX
 SG_ RCM2_a567_seaTrkPosLeftConfig m7 : 36|1@1+ (1,0) [0|0] "" Vector__XXX
 SG_ RCM2_a641_comGTWCarConfigMIA m8 : 36|1@1+ (1,0) [0|0] "" Vector__XXX
 SG_ RCM2_a701_comVCSECtpmsStatusMIA m9 : 36|1@1+ (1,0) [0|0] "" Vector__XXX
 SG_ RCM2_a859_comVCxLVPowerStateChkSm m10 : 36|1@1+ (1,0) [0|0] "" Vector__XXX
 SG_ RCM2_a062_passABStg1Sht2Gnd m0 : 37|1@1+ (1,0) [0|0] "" Vector__XXX
 SG_ RCM2_a122_kneeABPassSht2Gnd m1 : 37|1@1+ (1,0) [0|0] "" Vector__XXX
 SG_ RCM2_a182_hoodActuatorRSht2Gnd m2 : 37|1@1+ (1,0) [0|0] "" Vector__XXX
 SG_ RCM2_a276_imuRollR8OffCompPosLife m3 : 37|1@1+ (1,0) [0|0] "" Vector__XXX
 SG_ RCM2_a363_upFrntSnsrRCrssCoup m4 : 37|1@1+ (1,0) [0|0] "" Vector__XXX
 SG_ RCM2_a430_presFrntLDoorSht2Gnd m5 : 37|1@1+ (1,0) [0|0] "" Vector__XXX
 SG_ RCM2_a493_presRearLDoorCrssCoup m6 : 37|1@1+ (1,0) [0|0] "" Vector__XXX
 SG_ RCM2_a568_occPROSSht2Gnd m7 : 37|1@1+ (1,0) [0|0] "" Vector__XXX
 SG_ RCM2_a642_comVINmessageMIA m8 : 37|1@1+ (1,0) [0|0] "" Vector__XXX
 SG_ RCM2_a750_linInternalTimeout m9 : 37|1@1+ (1,0) [0|0] "" Vector__XXX
 SG_ RCM2_a860_comVCxLVPowerStateCntr m10 : 37|1@1+ (1,0) [0|0] "" Vector__XXX
 SG_ RCM2_a063_passABStg1Sht2Bat m0 : 38|1@1+ (1,0) [0|0] "" Vector__XXX
 SG_ RCM2_a123_kneeABPassSht2Bat m1 : 38|1@1+ (1,0) [0|0] "" Vector__XXX
 SG_ RCM2_a183_hoodActuatorRSht2Bat m2 : 38|1@1+ (1,0) [0|0] "" Vector__XXX
 SG_ RCM2_a277_imuRollR8OffCompNegLife m3 : 38|1@1+ (1,0) [0|0] "" Vector__XXX
 SG_ RCM2_a364_upFrntSnsrRCommErr m4 : 38|1@1+ (1,0) [0|0] "" Vector__XXX
 SG_ RCM2_a431_presFrntLDoorSht2Bat m5 : 38|1@1+ (1,0) [0|0] "" Vector__XXX
 SG_ RCM2_a494_presRearLDoorCommErr m6 : 38|1@1+ (1,0) [0|0] "" Vector__XXX
 SG_ RCM2_a569_occPROSSht2Bat m7 : 38|1@1+ (1,0) [0|0] "" Vector__XXX
 SG_ RCM2_a643_comDASSafetyFrntMIA m8 : 38|1@1+ (1,0) [0|0] "" Vector__XXX
 SG_ RCM2_a799_internalFault m9 : 38|1@1+ (1,0) [0|0] "" Vector__XXX
 SG_ RCM2_a861_typeApprovalStringNotLearned m10 : 38|1@1+ (1,0) [0|0] "" Vector__XXX
 SG_ RCM2_a064_passABStg1Open m0 : 39|1@1+ (1,0) [0|0] "" Vector__XXX
 SG_ RCM2_a124_kneeABPassOpen m1 : 39|1@1+ (1,0) [0|0] "" Vector__XXX
 SG_ RCM2_a184_hoodActuatorROpen m2 : 39|1@1+ (1,0) [0|0] "" Vector__XXX
 SG_ RCM2_a278_imuRollR8OffCompPosFLDC m3 : 39|1@1+ (1,0) [0|0] "" Vector__XXX
 SG_ RCM2_a365_upFrntSnsrRInitTyp m4 : 39|1@1+ (1,0) [0|0] "" Vector__XXX
 SG_ RCM2_a432_presFrntLDoorOpen m5 : 39|1@1+ (1,0) [0|0] "" Vector__XXX
 SG_ RCM2_a495_presRearLDoorInitTyp m6 : 39|1@1+ (1,0) [0|0] "" Vector__XXX
 SG_ RCM2_a570_occPROSOpen m7 : 39|1@1+ (1,0) [0|0] "" Vector__XXX
 SG_ RCM2_a644_comDASSafetyFrntChkSm m8 : 39|1@1+ (1,0) [0|0] "" Vector__XXX
 SG_ RCM2_a800_crcFault m9 : 39|1@1+ (1,0) [0|0] "" Vector__XXX
 SG_ RCM2_a862_comPCSalertMatrixMIA m10 : 39|1@1+ (1,0) [0|0] "" Vector__XXX
 SG_ RCM2_a065_passABStg1Short m0 : 40|1@1+ (1,0) [0|0] "" Vector__XXX
 SG_ RCM2_a125_kneeABPassShort m1 : 40|1@1+ (1,0) [0|0] "" Vector__XXX
 SG_ RCM2_a185_hoodActuatorRShort m2 : 40|1@1+ (1,0) [0|0] "" Vector__XXX
 SG_ RCM2_a279_imuRollR8OffCompNegFLDC m3 : 40|1@1+ (1,0) [0|0] "" Vector__XXX
 SG_ RCM2_a366_upFrntSnsrRConfig m4 : 40|1@1+ (1,0) [0|0] "" Vector__XXX
 SG_ RCM2_a433_presFrntLDoorCrssCoup m5 : 40|1@1+ (1,0) [0|0] "" Vector__XXX
 SG_ RCM2_a496_presRearLDoorConfig m6 : 40|1@1+ (1,0) [0|0] "" Vector__XXX
 SG_ RCM2_a571_occPROSUndef m7 : 40|1@1+ (1,0) [0|0] "" Vector__XXX
 SG_ RCM2_a645_comDASSafetyFrntCntr m8 : 40|1@1+ (1,0) [0|0] "" Vector__XXX
 SG_ RCM2_a801_parameterLayoutID m9 : 40|1@1+ (1,0) [0|0] "" Vector__XXX
 SG_ RCM2_a863_comVCFRONTalertMatrixMIA m10 : 40|1@1+ (1,0) [0|0] "" Vector__XXX
 SG_ RCM2_a066_passABStg1CrssCoup m0 : 41|1@1+ (1,0) [0|0] "" Vector__XXX
 SG_ RCM2_a126_kneeABPassCrssCoup m1 : 41|1@1+ (1,0) [0|0] "" Vector__XXX
 SG_ RCM2_a186_hoodActuatorRCrssCoup m2 : 41|1@1+ (1,0) [0|0] "" Vector__XXX
 SG_ RCM2_a280_imuRollR8OffCompPosSLDC m3 : 41|1@1+ (1,0) [0|0] "" Vector__XXX
 SG_ RCM2_a367_upFrntSnsrRDefect m4 : 41|1@1+ (1,0) [0|0] "" Vector__XXX
 SG_ RCM2_a434_presFrntLDoorCommErr m5 : 41|1@1+ (1,0) [0|0] "" Vector__XXX
 SG_ RCM2_a497_presRearLDoorDefect m6 : 41|1@1+ (1,0) [0|0] "" Vector__XXX
 SG_ RCM2_a572_occPROSCrssCoup m7 : 41|1@1+ (1,0) [0|0] "" Vector__XXX
 SG_ RCM2_a646_comDIstateMIA m8 : 41|1@1+ (1,0) [0|0] "" Vector__XXX
 SG_ RCM2_a802_parameterTransferID m9 : 41|1@1+ (1,0) [0|0] "" Vector__XXX
 SG_ RCM2_a864_comGTWepochTimeMIA m10 : 41|1@1+ (1,0) [0|0] "" Vector__XXX
 SG_ RCM2_a067_passABStg1Config m0 : 42|1@1+ (1,0) [0|0] "" Vector__XXX
 SG_ RCM2_a127_kneeABPassConfig m1 : 42|1@1+ (1,0) [0|0] "" Vector__XXX
 SG_ RCM2_a187_hoodActuatorRConfig m2 : 42|1@1+ (1,0) [0|0] "" Vector__XXX
 SG_ RCM2_a281_imuRollR8OffCompNegSLDC m3 : 42|1@1+ (1,0) [0|0] "" Vector__XXX
 SG_ RCM2_a368_upFrntSnsrRSigMon m4 : 42|1@1+ (1,0) [0|0] "" Vector__XXX
 SG_ RCM2_a435_presFrntLDoorInitTyp m5 : 42|1@1+ (1,0) [0|0] "" Vector__XXX
 SG_ RCM2_a498_presRearLDoorSigMon m6 : 42|1@1+ (1,0) [0|0] "" Vector__XXX
 SG_ RCM2_a573_occPROSConfig m7 : 42|1@1+ (1,0) [0|0] "" Vector__XXX
 SG_ RCM2_a647_comDIstateChkSm m8 : 42|1@1+ (1,0) [0|0] "" Vector__XXX
 SG_ RCM2_a803_algoVerifySensorID m9 : 42|1@1+ (1,0) [0|0] "" Vector__XXX
 SG_ RCM2_a865_comVCLVBMSstatusHighMIA m10 : 42|1@1+ (1,0) [0|0] "" Vector__XXX
 SG_ RCM2_a068_passABStg2Sht2Gnd m0 : 43|1@1+ (1,0) [0|0] "" Vector__XXX
 SG_ RCM2_a128_sideAB1stRowLSht2Gnd m1 : 43|1@1+ (1,0) [0|0] "" Vector__XXX
 SG_ RCM2_a188_hoodActuatorLSht2Gnd m2 : 43|1@1+ (1,0) [0|0] "" Vector__XXX
 SG_ RCM2_a282_imuLongAOffCompPosLife m3 : 43|1@1+ (1,0) [0|0] "" Vector__XXX
 SG_ RCM2_a370_upFrntSnsrMidLSht2Gnd m4 : 43|1@1+ (1,0) [0|0] "" Vector__XXX
 SG_ RCM2_a436_presFrntLDoorConfig m5 : 43|1@1+ (1,0) [0|0] "" Vector__XXX
 SG_ RCM2_a500_presRearRDoorSht2Gnd m6 : 43|1@1+ (1,0) [0|0] "" Vector__XXX
 SG_ RCM2_a587_sbrRearNetworkSht2Gnd m7 : 43|1@1+ (1,0) [0|0] "" Vector__XXX
 SG_ RCM2_a648_comDIstateCntr m8 : 43|1@1+ (1,0) [0|0] "" Vector__XXX
 SG_ RCM2_a804_configDataInconsistent m9 : 43|1@1+ (1,0) [0|0] "" Vector__XXX
 SG_ RCM2_a866_comDASstatusMIA m10 : 43|1@1+ (1,0) [0|0] "" Vector__XXX
 SG_ RCM2_a069_passABStg2Sht2Bat m0 : 44|1@1+ (1,0) [0|0] "" Vector__XXX
 SG_ RCM2_a129_sideAB1stRowLSht2Bat m1 : 44|1@1+ (1,0) [0|0] "" Vector__XXX
 SG_ RCM2_a189_hoodActuatorLSht2Bat m2 : 44|1@1+ (1,0) [0|0] "" Vector__XXX
 SG_ RCM2_a283_imuLongAOffCompNegLife m3 : 44|1@1+ (1,0) [0|0] "" Vector__XXX
 SG_ RCM2_a371_upFrntSnsrMidLSht2Bat m4 : 44|1@1+ (1,0) [0|0] "" Vector__XXX
 SG_ RCM2_a437_presFrntLDoorDefect m5 : 44|1@1+ (1,0) [0|0] "" Vector__XXX
 SG_ RCM2_a501_presRearRDoorSht2Bat m6 : 44|1@1+ (1,0) [0|0] "" Vector__XXX
 SG_ RCM2_a588_sbrRearNetworkSht2Bat m7 : 44|1@1+ (1,0) [0|0] "" Vector__XXX
 SG_ RCM2_a649_comDIstate2MIA m8 : 44|1@1+ (1,0) [0|0] "" Vector__XXX
 SG_ RCM2_a805_swVersionWrong m9 : 44|1@1+ (1,0) [0|0] "" Vector__XXX
 SG_ RCM2_a868_headAB3rdRowRSht2Gnd m10 : 44|1@1+ (1,0) [0|0] "" Vector__XXX
 SG_ RCM2_a070_passABStg2Open m0 : 45|1@1+ (1,0) [0|0] "" Vector__XXX
 SG_ RCM2_a130_sideAB1stRowLOpen m1 : 45|1@1+ (1,0) [0|0] "" Vector__XXX
 SG_ RCM2_a190_hoodActuatorLOpen m2 : 45|1@1+ (1,0) [0|0] "" Vector__XXX
 SG_ RCM2_a284_imuLongAOffCompPosFLDC m3 : 45|1@1+ (1,0) [0|0] "" Vector__XXX
 SG_ RCM2_a372_upFrntSnsrMidLOpen m4 : 45|1@1+ (1,0) [0|0] "" Vector__XXX
 SG_ RCM2_a438_presFrntLDoorSigMon m5 : 45|1@1+ (1,0) [0|0] "" Vector__XXX
 SG_ RCM2_a502_presRearRDoorOpen m6 : 45|1@1+ (1,0) [0|0] "" Vector__XXX
 SG_ RCM2_a589_sbrRearNetworkOpen m7 : 45|1@1+ (1,0) [0|0] "" Vector__XXX
 SG_ RCM2_a650_comDIstate2ChkSm m8 : 45|1@1+ (1,0) [0|0] "" Vector__XXX
 SG_ RCM2_a806_configVINnotLearned m9 : 45|1@1+ (1,0) [0|0] "" Vector__XXX
 SG_ RCM2_a869_headAB3rdRowRSht2Bat m10 : 45|1@1+ (1,0) [0|0] "" Vector__XXX
 SG_ RCM2_a071_passABStg2Short m0 : 46|1@1+ (1,0) [0|0] "" Vector__XXX
 SG_ RCM2_a131_sideAB1stRowLShort m1 : 46|1@1+ (1,0) [0|0] "" Vector__XXX
 SG_ RCM2_a191_hoodActuatorLShort m2 : 46|1@1+ (1,0) [0|0] "" Vector__XXX
 SG_ RCM2_a285_imuLongAOffCompNegFLDC m3 : 46|1@1+ (1,0) [0|0] "" Vector__XXX
 SG_ RCM2_a373_upFrntSnsrMidLCrssCoup m4 : 46|1@1+ (1,0) [0|0] "" Vector__XXX
 SG_ RCM2_a439_presDoorAbsolute1 m5 : 46|1@1+ (1,0) [0|0] "" Vector__XXX
 SG_ RCM2_a503_presRearRDoorCrssCoup m6 : 46|1@1+ (1,0) [0|0] "" Vector__XXX
 SG_ RCM2_a590_sbrRearNetworkUndefined m7 : 46|1@1+ (1,0) [0|0] "" Vector__XXX
 SG_ RCM2_a651_comDIstate2Cntr m8 : 46|1@1+ (1,0) [0|0] "" Vector__XXX
 SG_ RCM2_a807_configVINmismatch m9 : 46|1@1+ (1,0) [0|0] "" Vector__XXX
 SG_ RCM2_a870_headAB3rdRowROpen m10 : 46|1@1+ (1,0) [0|0] "" Vector__XXX
 SG_ RCM2_a072_passABStg2CrssCoup m0 : 47|1@1+ (1,0) [0|0] "" Vector__XXX
 SG_ RCM2_a132_sideAB1stRowLCrssCoup m1 : 47|1@1+ (1,0) [0|0] "" Vector__XXX
 SG_ RCM2_a192_hoodActuatorLCrssCoup m2 : 47|1@1+ (1,0) [0|0] "" Vector__XXX
 SG_ RCM2_a286_imuLongAOffCompPosSLDC m3 : 47|1@1+ (1,0) [0|0] "" Vector__XXX
 SG_ RCM2_a374_upFrntSnsrMidLCommErr m4 : 47|1@1+ (1,0) [0|0] "" Vector__XXX
 SG_ RCM2_a440_presFrntRDoorSht2Gnd m5 : 47|1@1+ (1,0) [0|0] "" Vector__XXX
 SG_ RCM2_a504_presRearRDoorCommErr m6 : 47|1@1+ (1,0) [0|0] "" Vector__XXX
 SG_ RCM2_a591_sbrRearNetworkCrssCoup m7 : 47|1@1+ (1,0) [0|0] "" Vector__XXX
 SG_ RCM2_a652_ambientTempFaulted m8 : 47|1@1+ (1,0) [0|0] "" Vector__XXX
 SG_ RCM2_a808_configDriveNotLearned m9 : 47|1@1+ (1,0) [0|0] "" Vector__XXX
 SG_ RCM2_a871_headAB3rdRowRShort m10 : 47|1@1+ (1,0) [0|0] "" Vector__XXX
 SG_ RCM2_a073_passABStg2Config m0 : 48|1@1+ (1,0) [0|0] "" Vector__XXX
 SG_ RCM2_a133_sideAB1stRowLConfig m1 : 48|1@1+ (1,0) [0|0] "" Vector__XXX
 SG_ RCM2_a193_hoodActuatorLConfig m2 : 48|1@1+ (1,0) [0|0] "" Vector__XXX
 SG_ RCM2_a287_imuLongAOffCompNegSLDC m3 : 48|1@1+ (1,0) [0|0] "" Vector__XXX
 SG_ RCM2_a375_upFrntSnsrMidLInitTyp m4 : 48|1@1+ (1,0) [0|0] "" Vector__XXX
 SG_ RCM2_a441_presFrntRDoorSht2Bat m5 : 48|1@1+ (1,0) [0|0] "" Vector__XXX
 SG_ RCM2_a505_presRearRDoorInitTyp m6 : 48|1@1+ (1,0) [0|0] "" Vector__XXX
 SG_ RCM2_a592_sbrRearNetworkConfig m7 : 48|1@1+ (1,0) [0|0] "" Vector__XXX
 SG_ RCM2_a653_comGTWESP1MIA m8 : 48|1@1+ (1,0) [0|0] "" Vector__XXX
 SG_ RCM2_a809_configDriveMismatch m9 : 48|1@1+ (1,0) [0|0] "" Vector__XXX
 SG_ RCM2_a872_headAB3rdRowRCrossC m10 : 48|1@1+ (1,0) [0|0] "" Vector__XXX
 SG_ RCM2_a074_passActiveVentSht2Gnd m0 : 49|1@1+ (1,0) [0|0] "" Vector__XXX
 SG_ RCM2_a134_sideAB1stRowRSht2Gnd m1 : 49|1@1+ (1,0) [0|0] "" Vector__XXX
 SG_ RCM2_a194_driverABAVSht2Gnd m2 : 49|1@1+ (1,0) [0|0] "" Vector__XXX
 SG_ RCM2_a288_imuLatAcOffCompPosLife m3 : 49|1@1+ (1,0) [0|0] "" Vector__XXX
 SG_ RCM2_a376_upFrntSnsrMidLConfig m4 : 49|1@1+ (1,0) [0|0] "" Vector__XXX
 SG_ RCM2_a442_presFrntRDoorOpen m5 : 49|1@1+ (1,0) [0|0] "" Vector__XXX
 SG_ RCM2_a506_presRearRDoorConfig m6 : 49|1@1+ (1,0) [0|0] "" Vector__XXX
 SG_ RCM2_a593_driveOrientationSht2Gnd m7 : 49|1@1+ (1,0) [0|0] "" Vector__XXX
 SG_ RCM2_a654_comGTWESP1ChkSm m8 : 49|1@1+ (1,0) [0|0] "" Vector__XXX
 SG_ RCM2_a810_bootUpActionFailure m9 : 49|1@1+ (1,0) [0|0] "" Vector__XXX
 SG_ RCM2_a873_headAB3rdRowRConfig m10 : 49|1@1+ (1,0) [0|0] "" Vector__XXX
 SG_ RCM2_a075_passActiveVentSht2Bat m0 : 50|1@1+ (1,0) [0|0] "" Vector__XXX
 SG_ RCM2_a135_sideAB1stRowRSht2Bat m1 : 50|1@1+ (1,0) [0|0] "" Vector__XXX
 SG_ RCM2_a195_driverABAVSht2Bat m2 : 50|1@1+ (1,0) [0|0] "" Vector__XXX
 SG_ RCM2_a289_imuLatAcOffCompNegLife m3 : 50|1@1+ (1,0) [0|0] "" Vector__XXX
 SG_ RCM2_a377_upFrntSnsrMidLDefect m4 : 50|1@1+ (1,0) [0|0] "" Vector__XXX
 SG_ RCM2_a443_presFrntRDoorCrssCoup m5 : 50|1@1+ (1,0) [0|0] "" Vector__XXX
 SG_ RCM2_a507_presRearRDoorDefect m6 : 50|1@1+ (1,0) [0|0] "" Vector__XXX
 SG_ RCM2_a594_driveOrientationSht2Bat m7 : 50|1@1+ (1,0) [0|0] "" Vector__XXX
 SG_ RCM2_a655_comGTWESP1Cntr m8 : 50|1@1+ (1,0) [0|0] "" Vector__XXX
 SG_ RCM2_a811_comAxleSpeed m9 : 50|1@1+ (1,0) [0|0] "" Vector__XXX
 SG_ RCM2_a874_headAB3rdRowLSht2Gnd m10 : 50|1@1+ (1,0) [0|0] "" Vector__XXX
 SG_ RCM2_a076_passActiveVentOpen m0 : 51|1@1+ (1,0) [0|0] "" Vector__XXX
 SG_ RCM2_a136_sideAB1stRowROpen m1 : 51|1@1+ (1,0) [0|0] "" Vector__XXX
 SG_ RCM2_a196_driverABAVOpen m2 : 51|1@1+ (1,0) [0|0] "" Vector__XXX
 SG_ RCM2_a290_imuLatAcOffCompPosFLDC m3 : 51|1@1+ (1,0) [0|0] "" Vector__XXX
 SG_ RCM2_a378_upFrntSnsrMidLSigMon m4 : 51|1@1+ (1,0) [0|0] "" Vector__XXX
 SG_ RCM2_a444_presFrntRDoorCommErr m5 : 51|1@1+ (1,0) [0|0] "" Vector__XXX
 SG_ RCM2_a508_presRearRDoorSigMon m6 : 51|1@1+ (1,0) [0|0] "" Vector__XXX
 SG_ RCM2_a595_driveOrientationOpen m7 : 51|1@1+ (1,0) [0|0] "" Vector__XXX
 SG_ RCM2_a656_comVCSEATPrestMIA m8 : 51|1@1+ (1,0) [0|0] "" Vector__XXX
 SG_ RCM2_a812_idfMisuseMonitoringErr m9 : 51|1@1+ (1,0) [0|0] "" Vector__XXX
 SG_ RCM2_a875_headAB3rdRowLSht2Bat m10 : 51|1@1+ (1,0) [0|0] "" Vector__XXX
 SG_ RCM2_a077_passActiveVentShort m0 : 52|1@1+ (1,0) [0|0] "" Vector__XXX
 SG_ RCM2_a137_sideAB1stRowRShort m1 : 52|1@1+ (1,0) [0|0] "" Vector__XXX
 SG_ RCM2_a197_driverABAVShort m2 : 52|1@1+ (1,0) [0|0] "" Vector__XXX
 SG_ RCM2_a291_imuLatAcOffCompNegFLDC m3 : 52|1@1+ (1,0) [0|0] "" Vector__XXX
 SG_ RCM2_a380_upFrntSnsrMidRSht2Gnd m4 : 52|1@1+ (1,0) [0|0] "" Vector__XXX
 SG_ RCM2_a445_presFrntRDoorInitTyp m5 : 52|1@1+ (1,0) [0|0] "" Vector__XXX
 SG_ RCM2_a509_sideAccelDPilLSht2Gnd m6 : 52|1@1+ (1,0) [0|0] "" Vector__XXX
 SG_ RCM2_a596_driveOrientationUndefined m7 : 52|1@1+ (1,0) [0|0] "" Vector__XXX
 SG_ RCM2_a657_comVCSEATPrestChkSm m8 : 52|1@1+ (1,0) [0|0] "" Vector__XXX
 SG_ RCM2_a813_idfEnviMonitoringError m9 : 52|1@1+ (1,0) [0|0] "" Vector__XXX
 SG_ RCM2_a876_headAB3rdRowLOpen m10 : 52|1@1+ (1,0) [0|0] "" Vector__XXX
 SG_ RCM2_a078_passActiveVentCrssCoup m0 : 53|1@1+ (1,0) [0|0] "" Vector__XXX
 SG_ RCM2_a138_sideAB1stRowRCrssCoup m1 : 53|1@1+ (1,0) [0|0] "" Vector__XXX
 SG_ RCM2_a198_driverABAVCrossCoup m2 : 53|1@1+ (1,0) [0|0] "" Vector__XXX
 SG_ RCM2_a292_imuLatAcOffCompPosSLDC m3 : 53|1@1+ (1,0) [0|0] "" Vector__XXX
 SG_ RCM2_a381_upFrntSnsrMidRSht2Bat m4 : 53|1@1+ (1,0) [0|0] "" Vector__XXX
 SG_ RCM2_a446_presFrntRDoorConfig m5 : 53|1@1+ (1,0) [0|0] "" Vector__XXX
 SG_ RCM2_a510_sideAccelDPilLSht2Bat m6 : 53|1@1+ (1,0) [0|0] "" Vector__XXX
 SG_ RCM2_a597_driveOrientationCrssCoup m7 : 53|1@1+ (1,0) [0|0] "" Vector__XXX
 SG_ RCM2_a658_comVCSEATPrestCntr m8 : 53|1@1+ (1,0) [0|0] "" Vector__XXX
 SG_ RCM2_a814_idfEnviMonitoringEvent m9 : 53|1@1+ (1,0) [0|0] "" Vector__XXX
 SG_ RCM2_a877_headAB3rdRowLShort m10 : 53|1@1+ (1,0) [0|0] "" Vector__XXX
 SG_ RCM2_a079_passActiveVentConfig m0 : 54|1@1+ (1,0) [0|0] "" Vector__XXX
 SG_ RCM2_a139_sideAB1stRowRConfig m1 : 54|1@1+ (1,0) [0|0] "" Vector__XXX
 SG_ RCM2_a199_driverABAVConfig m2 : 54|1@1+ (1,0) [0|0] "" Vector__XXX
 SG_ RCM2_a293_imuLatAcOffCompNegSLDC m3 : 54|1@1+ (1,0) [0|0] "" Vector__XXX
 SG_ RCM2_a382_upFrntSnsrMidROpen m4 : 54|1@1+ (1,0) [0|0] "" Vector__XXX
 SG_ RCM2_a447_presFrntRDoorDefect m5 : 54|1@1+ (1,0) [0|0] "" Vector__XXX
 SG_ RCM2_a511_sideAccelDPilLOpen m6 : 54|1@1+ (1,0) [0|0] "" Vector__XXX
 SG_ RCM2_a598_driveOrientationConfig m7 : 54|1@1+ (1,0) [0|0] "" Vector__XXX
 SG_ RCM2_a659_comVCSEATPbuckle m8 : 54|1@1+ (1,0) [0|0] "" Vector__XXX
 SG_ RCM2_a815_upFrntPedProMLSht2Gnd m9 : 54|1@1+ (1,0) [0|0] "" Vector__XXX
 SG_ RCM2_a878_headAB3rdRowLCrossC m10 : 54|1@1+ (1,0) [0|0] "" Vector__XXX
 SG_ RCM2_a080_pretenShldLeftSht2Gnd m0 : 55|1@1+ (1,0) [0|0] "" Vector__XXX
 SG_ RCM2_a140_hvdPyroSht2Gnd m1 : 55|1@1+ (1,0) [0|0] "" Vector__XXX
 SG_ RCM2_a200_driverFSABSht2Gnd m2 : 55|1@1+ (1,0) [0|0] "" Vector__XXX
 SG_ RCM2_a294_imuVertAOffCompPosLife m3 : 55|1@1+ (1,0) [0|0] "" Vector__XXX
 SG_ RCM2_a383_upFrntSnsrMidRCrssCoup m4 : 55|1@1+ (1,0) [0|0] "" Vector__XXX
 SG_ RCM2_a448_presFrntRDoorSigMon m5 : 55|1@1+ (1,0) [0|0] "" Vector__XXX
 SG_ RCM2_a512_sideAccelDPilLCrssCoup m6 : 55|1@1+ (1,0) [0|0] "" Vector__XXX
 SG_ RCM2_a600_comCANinternalTimeout m7 : 55|1@1+ (1,0) [0|0] "" Vector__XXX
 SG_ RCM2_a660_comVCSEATPOccpy m8 : 55|1@1+ (1,0) [0|0] "" Vector__XXX
 SG_ RCM2_a816_upFrntPedProMLSht2Bat m9 : 55|1@1+ (1,0) [0|0] "" Vector__XXX
 SG_ RCM2_a879_headAB3rdRowLConfig m10 : 55|1@1+ (1,0) [0|0] "" Vector__XXX
 SG_ RCM2_a081_pretenShldLeftSht2Bat m0 : 56|1@1+ (1,0) [0|0] "" Vector__XXX
 SG_ RCM2_a141_hvdPyroSht2Bat m1 : 56|1@1+ (1,0) [0|0] "" Vector__XXX
 SG_ RCM2_a201_driverFSABSht2Bat m2 : 56|1@1+ (1,0) [0|0] "" Vector__XXX
 SG_ RCM2_a295_imuVertAOffCompNegLife m3 : 56|1@1+ (1,0) [0|0] "" Vector__XXX
 SG_ RCM2_a384_upFrntSnsrMidRCommErr m4 : 56|1@1+ (1,0) [0|0] "" Vector__XXX
 SG_ RCM2_a449_presDoorAbsolute2 m5 : 56|1@1+ (1,0) [0|0] "" Vector__XXX
 SG_ RCM2_a513_sideAccelDPilLCommErr m6 : 56|1@1+ (1,0) [0|0] "" Vector__XXX
 SG_ RCM2_a601_comChassisCANSilent m7 : 56|1@1+ (1,0) [0|0] "" Vector__XXX
 SG_ RCM2_a661_comVCSEATPocs m8 : 56|1@1+ (1,0) [0|0] "" Vector__XXX
 SG_ RCM2_a817_upFrntPedProMLOpen m9 : 56|1@1+ (1,0) [0|0] "" Vector__XXX
 SG_ RCM2_a880_comVCLEFT3rLBuckle m10 : 56|1@1+ (1,0) [0|0] "" Vector__XXX
 SG_ RCM2_a082_pretenShldLeftOpen m0 : 57|1@1+ (1,0) [0|0] "" Vector__XXX
 SG_ RCM2_a142_hvdPyroOpen m1 : 57|1@1+ (1,0) [0|0] "" Vector__XXX
 SG_ RCM2_a202_driverFSABOpen m2 : 57|1@1+ (1,0) [0|0] "" Vector__XXX
 SG_ RCM2_a296_imuVertAOffCompPosFLDC m3 : 57|1@1+ (1,0) [0|0] "" Vector__XXX
 SG_ RCM2_a385_upFrntSnsrMidRInitTyp m4 : 57|1@1+ (1,0) [0|0] "" Vector__XXX
 SG_ RCM2_a450_presPedProLSht2Gnd m5 : 57|1@1+ (1,0) [0|0] "" Vector__XXX
 SG_ RCM2_a514_sideAccelDPilLInitTyp m6 : 57|1@1+ (1,0) [0|0] "" Vector__XXX
 SG_ RCM2_a602_comChassisCANBusOff m7 : 57|1@1+ (1,0) [0|0] "" Vector__XXX
 SG_ RCM2_a662_comVCSEATPstps m8 : 57|1@1+ (1,0) [0|0] "" Vector__XXX
 SG_ RCM2_a818_upFrntPedProMLCrssCoup m9 : 57|1@1+ (1,0) [0|0] "" Vector__XXX
 SG_ RCM2_a881_comVCRIGHT3rRBuckle m10 : 57|1@1+ (1,0) [0|0] "" Vector__XXX
 SG_ RCM2_a083_pretenShldLeftShort m0 : 58|1@1+ (1,0) [0|0] "" Vector__XXX
 SG_ RCM2_a143_hvdPyroShort m1 : 58|1@1+ (1,0) [0|0] "" Vector__XXX
 SG_ RCM2_a203_driverFSABShort m2 : 58|1@1+ (1,0) [0|0] "" Vector__XXX
 SG_ RCM2_a297_imuVertAOffCompNegFLDC m3 : 58|1@1+ (1,0) [0|0] "" Vector__XXX
 SG_ RCM2_a386_upFrntSnsrMidRConfig m4 : 58|1@1+ (1,0) [0|0] "" Vector__XXX
 SG_ RCM2_a451_presPedProLSht2Bat m5 : 58|1@1+ (1,0) [0|0] "" Vector__XXX
 SG_ RCM2_a515_sideAccelDPilLConfig m6 : 58|1@1+ (1,0) [0|0] "" Vector__XXX
 SG_ RCM2_a603_comPARTYCANSilent m7 : 58|1@1+ (1,0) [0|0] "" Vector__XXX
 SG_ RCM2_a663_comVCSEATDrestMIA m8 : 58|1@1+ (1,0) [0|0] "" Vector__XXX
 SG_ RCM2_a819_upFrntPedProMLCommErr m9 : 58|1@1+ (1,0) [0|0] "" Vector__XXX
 SG_ RCM2_a084_pretenShldLeftCrossC m0 : 59|1@1+ (1,0) [0|0] "" Vector__XXX
 SG_ RCM2_a144_hvdPyroCrssCoup m1 : 59|1@1+ (1,0) [0|0] "" Vector__XXX
 SG_ RCM2_a204_driverFSABCrossCoup m2 : 59|1@1+ (1,0) [0|0] "" Vector__XXX
 SG_ RCM2_a298_imuVertAOffCompPosSLDC m3 : 59|1@1+ (1,0) [0|0] "" Vector__XXX
 SG_ RCM2_a387_upFrntSnsrMidRDefect m4 : 59|1@1+ (1,0) [0|0] "" Vector__XXX
 SG_ RCM2_a452_presPedProLOpen m5 : 59|1@1+ (1,0) [0|0] "" Vector__XXX
 SG_ RCM2_a516_sideAccelDPilLDefect m6 : 59|1@1+ (1,0) [0|0] "" Vector__XXX
 SG_ RCM2_a604_comPARTYCANBusOff m7 : 59|1@1+ (1,0) [0|0] "" Vector__XXX
 SG_ RCM2_a664_comVCSEATDrestChkSm m8 : 59|1@1+ (1,0) [0|0] "" Vector__XXX
 SG_ RCM2_a820_upFrntPedProMLIntTyp m9 : 59|1@1+ (1,0) [0|0] "" Vector__XXX
 SG_ RCM2_a085_pretenShldLeftConfig m0 : 60|1@1+ (1,0) [0|0] "" Vector__XXX
 SG_ RCM2_a145_hvdPyroConfig m1 : 60|1@1+ (1,0) [0|0] "" Vector__XXX
 SG_ RCM2_a205_driverFSABConfig m2 : 60|1@1+ (1,0) [0|0] "" Vector__XXX
 SG_ RCM2_a299_imuVertAOffCompNegSLDC m3 : 60|1@1+ (1,0) [0|0] "" Vector__XXX
 SG_ RCM2_a388_upFrntSnsrMidRSigMon m4 : 60|1@1+ (1,0) [0|0] "" Vector__XXX
 SG_ RCM2_a453_presPedProLCrssCoup m5 : 60|1@1+ (1,0) [0|0] "" Vector__XXX
 SG_ RCM2_a517_sideAccelDPilLSigMon m6 : 60|1@1+ (1,0) [0|0] "" Vector__XXX
 SG_ RCM2_a605_comStwAngStatMIA m7 : 60|1@1+ (1,0) [0|0] "" Vector__XXX
 SG_ RCM2_a665_comVCSEATDrestCntr m8 : 60|1@1+ (1,0) [0|0] "" Vector__XXX
 SG_ RCM2_a821_upFrntPedProMLConfig m9 : 60|1@1+ (1,0) [0|0] "" Vector__XXX
 SG_ RCM2_a086_pretenShldRightSht2Gnd m0 : 61|1@1+ (1,0) [0|0] "" Vector__XXX
 SG_ RCM2_a146_curABLeftSht2Gnd m1 : 61|1@1+ (1,0) [0|0] "" Vector__XXX
 SG_ RCM2_a206_sideAB2ndRowLSht2Gnd m2 : 61|1@1+ (1,0) [0|0] "" Vector__XXX
 SG_ RCM2_a300_imuAccXHgMonChlPerm m3 : 61|1@1+ (1,0) [0|0] "" Vector__XXX
 SG_ RCM2_a390_sideAccelBPilLSht2Gnd m4 : 61|1@1+ (1,0) [0|0] "" Vector__XXX
 SG_ RCM2_a454_presPedProLCommErr m5 : 61|1@1+ (1,0) [0|0] "" Vector__XXX
 SG_ RCM2_a518_sideAccelDPilRSht2Gnd m6 : 61|1@1+ (1,0) [0|0] "" Vector__XXX
 SG_ RCM2_a606_comStwAngStatChkSm m7 : 61|1@1+ (1,0) [0|0] "" Vector__XXX
 SG_ RCM2_a666_comVCSEATDbuckle m8 : 61|1@1+ (1,0) [0|0] "" Vector__XXX
 SG_ RCM2_a822_upFrntPedProMLDefect m9 : 61|1@1+ (1,0) [0|0] "" Vector__XXX
 SG_ RCM2_a087_pretenShldRightSht2Bat m0 : 62|1@1+ (1,0) [0|0] "" Vector__XXX
 SG_ RCM2_a147_curABLeftSht2Bat m1 : 62|1@1+ (1,0) [0|0] "" Vector__XXX
 SG_ RCM2_a207_sideAB2ndRowLSht2Bat m2 : 62|1@1+ (1,0) [0|0] "" Vector__XXX
 SG_ RCM2_a301_imuAccXHgMonChlTemp m3 : 62|1@1+ (1,0) [0|0] "" Vector__XXX
 SG_ RCM2_a391_sideAccelBPilLSht2Bat m4 : 62|1@1+ (1,0) [0|0] "" Vector__XXX
 SG_ RCM2_a455_presPedProLInitTyp m5 : 62|1@1+ (1,0) [0|0] "" Vector__XXX
 SG_ RCM2_a519_sideAccelDPilRSht2Bat m6 : 62|1@1+ (1,0) [0|0] "" Vector__XXX
 SG_ RCM2_a607_comStwAngStatCntr m7 : 62|1@1+ (1,0) [0|0] "" Vector__XXX
 SG_ RCM2_a667_comVCSEATDOccpy m8 : 62|1@1+ (1,0) [0|0] "" Vector__XXX
 SG_ RCM2_a823_upFrntPedProMLSigMon m9 : 62|1@1+ (1,0) [0|0] "" Vector__XXX
 SG_ RCM2_a088_pretenShldRightOpen m0 : 63|1@1+ (1,0) [0|0] "" Vector__XXX
 SG_ RCM2_a148_curABLeftOpen m1 : 63|1@1+ (1,0) [0|0] "" Vector__XXX
 SG_ RCM2_a208_sideAB2ndRowLOpen m2 : 63|1@1+ (1,0) [0|0] "" Vector__XXX
 SG_ RCM2_a302_imuAccYHgMonChlPerm m3 : 63|1@1+ (1,0) [0|0] "" Vector__XXX
 SG_ RCM2_a392_sideAccelBPilLOpen m4 : 63|1@1+ (1,0) [0|0] "" Vector__XXX
 SG_ RCM2_a456_presPedProLConfig m5 : 63|1@1+ (1,0) [0|0] "" Vector__XXX
 SG_ RCM2_a520_sideAccelDPilROpen m6 : 63|1@1+ (1,0) [0|0] "" Vector__XXX
 SG_ RCM2_a608_comDItorque1MIA m7 : 63|1@1+ (1,0) [0|0] "" Vector__XXX
 SG_ RCM2_a668_comVCSEATDstps m8 : 63|1@1+ (1,0) [0|0] "" Vector__XXX
 SG_ RCM2_a824_upFrntPedProMRSht2Gnd m9 : 63|1@1+ (1,0) [0|0] "" Vector__XXX

BO_ 1010 RCM3_alertMatrix: 8 Vector__XXX
 SG_ RCM3_matrixIndex M : 0|4@1+ (1,0) [0|0] "" Vector__XXX
 SG_ RCM3_a001_LVPowerLossDetected m0 : 4|1@1+ (1,0) [0|0] "" Vector__XXX

BO_ 1011 UI_odo: 8 Vector__XXX
 SG_ UI_odometer : 0|24@1+ (0.1,0) [0|0] "" Vector__XXX

BO_ 1012 APP_camCalibrationStatus: 8 Vector__XXX
 SG_ APP_cameraPosition M : 0|4@1+ (1,0) [0|0] "" Vector__XXX
 SG_ APP_backupCamExtPitchCal m8 : 8|9@1+ (0.05,-12.5) [0|0] "" Vector__XXX
 SG_ APP_fisheyeCamExtPitchCal m3 : 8|9@1+ (0.05,-12.5) [0|0] "" Vector__XXX
 SG_ APP_lPillarCamExtPitchCal m4 : 8|9@1+ (0.05,-12.5) [0|0] "" Vector__XXX
 SG_ APP_lRepeatCamExtPitchCal m6 : 8|9@1+ (0.05,-12.5) [0|0] "" Vector__XXX
 SG_ APP_mainCamExtPitchCal m1 : 8|9@1+ (0.05,-12.5) [0|0] "" Vector__XXX
 SG_ APP_narrowCamExtPitchCal m2 : 8|9@1+ (0.05,-12.5) [0|0] "" Vector__XXX
 SG_ APP_rPillarCamExtPitchCal m5 : 8|9@1+ (0.05,-12.5) [0|0] "" Vector__XXX
 SG_ APP_rRepeatCamExtPitchCal m7 : 8|9@1+ (0.05,-12.5) [0|0] "" Vector__XXX
 SG_ APP_backupCamExtYawCal m8 : 17|9@1+ (0.05,-12.5) [0|0] "" Vector__XXX
 SG_ APP_fisheyeCamExtYawCal m3 : 17|9@1+ (0.05,-12.5) [0|0] "" Vector__XXX
 SG_ APP_lPillarCamExtYawCal m4 : 17|9@1+ (0.05,-12.5) [0|0] "" Vector__XXX
 SG_ APP_lRepeatCamExtYawCal m6 : 17|9@1+ (0.05,-12.5) [0|0] "" Vector__XXX
 SG_ APP_mainCamExtYawCal m1 : 17|9@1+ (0.05,-12.5) [0|0] "" Vector__XXX
 SG_ APP_narrowCamExtYawCal m2 : 17|9@1+ (0.05,-12.5) [0|0] "" Vector__XXX
 SG_ APP_rPillarCamExtYawCal m5 : 17|9@1+ (0.05,-12.5) [0|0] "" Vector__XXX
 SG_ APP_rRepeatCamExtYawCal m7 : 17|9@1+ (0.05,-12.5) [0|0] "" Vector__XXX
 SG_ APP_backupCalibTime m8 : 26|7@1+ (1,0) [0|0] "" Vector__XXX
 SG_ APP_fisheyeCalibTime m3 : 26|7@1+ (1,0) [0|0] "" Vector__XXX
 SG_ APP_lPillarCalibTime m4 : 26|7@1+ (1,0) [0|0] "" Vector__XXX
 SG_ APP_lRepeatCalibTime m6 : 26|7@1+ (1,0) [0|0] "" Vector__XXX
 SG_ APP_mainCalibTime m1 : 26|7@1+ (1,0) [0|0] "" Vector__XXX
 SG_ APP_narrowCalibTime m2 : 26|7@1+ (1,0) [0|0] "" Vector__XXX
 SG_ APP_rPillarCalibTime m5 : 26|7@1+ (1,0) [0|0] "" Vector__XXX
 SG_ APP_rRepeatCalibTime m7 : 26|7@1+ (1,0) [0|0] "" Vector__XXX
 SG_ APP_backupCalibProgress m8 : 33|7@1+ (1,0) [0|0] "" Vector__XXX
 SG_ APP_fisheyeCalibProgress m3 : 33|7@1+ (1,0) [0|0] "" Vector__XXX
 SG_ APP_lPillarCalibProgress m4 : 33|7@1+ (1,0) [0|0] "" Vector__XXX
 SG_ APP_lRepeatCalibProgress m6 : 33|7@1+ (1,0) [0|0] "" Vector__XXX
 SG_ APP_mainCalibProgress m1 : 33|7@1+ (1,0) [0|0] "" Vector__XXX
 SG_ APP_narrowCalibProgress m2 : 33|7@1+ (1,0) [0|0] "" Vector__XXX
 SG_ APP_rPillarCalibProgress m5 : 33|7@1+ (1,0) [0|0] "" Vector__XXX
 SG_ APP_rRepeatCalibProgress m7 : 33|7@1+ (1,0) [0|0] "" Vector__XXX
 SG_ APP_backupCalibrated m8 : 40|1@1+ (1,0) [0|0] "" Vector__XXX
 SG_ APP_fisheyeCalibrated m3 : 40|1@1+ (1,0) [0|0] "" Vector__XXX
 SG_ APP_lPillarCalibrated m4 : 40|1@1+ (1,0) [0|0] "" Vector__XXX
 SG_ APP_lRepeatCalibrated m6 : 40|1@1+ (1,0) [0|0] "" Vector__XXX
 SG_ APP_mainCalibrated m1 : 40|1@1+ (1,0) [0|0] "" Vector__XXX
 SG_ APP_narrowCalibrated m2 : 40|1@1+ (1,0) [0|0] "" Vector__XXX
 SG_ APP_rPillarCalibrated m5 : 40|1@1+ (1,0) [0|0] "" Vector__XXX
 SG_ APP_rRepeatCalibrated m7 : 40|1@1+ (1,0) [0|0] "" Vector__XXX

BO_ 1013 VCFRONT_lighting: 8 Vector__XXX
 SG_ VCFRONT_indicatorLeftRequest : 0|2@1+ (1,0) [0|0] "" Vector__XXX
 SG_ VCFRONT_indicatorRightRequest : 2|2@1+ (1,0) [0|0] "" Vector__XXX
 SG_ VCFRONT_hazardLightRequest : 4|4@1+ (1,0) [0|0] "" Vector__XXX
 SG_ VCFRONT_ambientLightingBrightnes : 8|8@1+ (0.5,0) [0|0] "" Vector__XXX
 SG_ VCFRONT_switchLightingBrightness : 16|8@1+ (0.5,0) [0|0] "" Vector__XXX
 SG_ VCFRONT_courtesyLightingRequest : 24|1@1+ (1,0) [0|0] "" Vector__XXX
 SG_ VCFRONT_hazardSwitchBacklight : 27|1@1+ (1,0) [0|0] "" Vector__XXX
 SG_ VCFRONT_highBeamControlState : 28|2@1+ (1,0) [0|0] "" Vector__XXX
 SG_ VCFRONT_dynamicBrakeLightState : 30|2@1+ (1,0) [0|0] "" Vector__XXX
 SG_ VCFRONT_lightingCoreState : 32|4@1+ (1,0) [0|0] "" Vector__XXX
 SG_ VCFRONT_intHighBeamsFunctionState : 36|1@1+ (1,0) [0|0] "" Vector__XXX
 SG_ VCFRONT_latchedHighBeamsFunctionState : 37|1@1+ (1,0) [0|0] "" Vector__XXX
 SG_ VCFRONT_frontFogFunctionState : 38|1@1+ (1,0) [0|0] "" Vector__XXX
 SG_ VCFRONT_headlightsReadyOrTimedOut : 39|1@1+ (1,0) [0|0] "" Vector__XXX
 SG_ VCFRONT_turnIndicatorStalk : 40|2@1+ (1,0) [0|0] "" Vector__XXX
 SG_ VCFRONT_highBeamLatchingState : 42|2@1+ (1,0) [0|0] "" Vector__XXX
 SG_ VCFRONT_lightingCustomState : 44|5@1+ (1,0) [0|0] "" Vector__XXX
 SG_ VC_fastFlashHazardsActive : 49|1@1+ (1,0) [0|0] "" Vector__XXX
 SG_ VCFRONT_indicatorLeftInternal : 50|2@1+ (1,0) [0|0] "" Vector__XXX
 SG_ VCFRONT_indicatorRightInternal : 52|2@1+ (1,0) [0|0] "" Vector__XXX

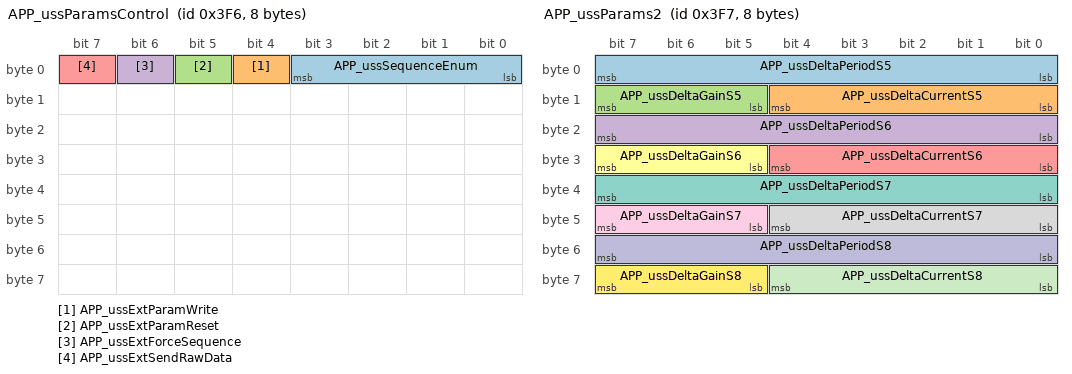
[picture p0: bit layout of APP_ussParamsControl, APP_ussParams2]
BO_ 1014 APP_ussParamsControl: 8 Vector__XXX
 SG_ APP_ussSequenceEnum : 0|4@1+ (1,0) [0|0] "" Vector__XXX
 SG_ APP_ussExtParamWrite : 4|1@1+ (1,0) [0|0] "" Vector__XXX
 SG_ APP_ussExtParamReset : 5|1@1+ (1,0) [0|0] "" Vector__XXX
 SG_ APP_ussExtForceSequence : 6|1@1+ (1,0) [0|0] "" Vector__XXX
 SG_ APP_ussExtSendRawData : 7|1@1+ (1,0) [0|0] "" Vector__XXX

BO_ 1015 APP_ussParams2: 8 Vector__XXX
 SG_ APP_ussDeltaPeriodS5 : 0|8@1- (1,0) [0|0] "" Vector__XXX
 SG_ APP_ussDeltaCurrentS5 : 8|5@1- (1,0) [0|0] "" Vector__XXX
 SG_ APP_ussDeltaGainS5 : 13|3@1- (1,0) [0|0] "" Vector__XXX
 SG_ APP_ussDeltaPeriodS6 : 16|8@1- (1,0) [0|0] "" Vector__XXX
 SG_ APP_ussDeltaCurrentS6 : 24|5@1- (1,0) [0|0] "" Vector__XXX
 SG_ APP_ussDeltaGainS6 : 29|3@1- (1,0) [0|0] "" Vector__XXX
 SG_ APP_ussDeltaPeriodS7 : 32|8@1- (1,0) [0|0] "" Vector__XXX
 SG_ APP_ussDeltaCurrentS7 : 40|5@1- (1,0) [0|0] "" Vector__XXX
 SG_ APP_ussDeltaGainS7 : 45|3@1- (1,0) [0|0] "" Vector__XXX
 SG_ APP_ussDeltaPeriodS8 : 48|8@1- (1,0) [0|0] "" Vector__XXX
 SG_ APP_ussDeltaCurrentS8 : 56|5@1- (1,0) [0|0] "" Vector__XXX
 SG_ APP_ussDeltaGainS8 : 61|3@1- (1,0) [0|0] "" Vector__XXX

BO_ 1016 UI_driverAssistControl: 8 Vector__XXX
 SG_ UI_autopilotControlRequest : 0|1@1+ (1,0) [0|0] "" Vector__XXX
 SG_ UI_ulcStalkConfirm : 1|1@1+ (1,0) [0|0] "" Vector__XXX
 SG_ UI_summonHeartbeat : 2|2@1+ (1,0) [0|0] "" Vector__XXX
 SG_ UI_curvSpeedAdaptDisable : 4|1@1+ (1,0) [0|0] "" Vector__XXX
 SG_ UI_dasDeveloper : 5|1@1+ (1,0) [0|0] "" Vector__XXX
 SG_ UI_enableVinAssociation : 6|1@1+ (1,0) [0|0] "" Vector__XXX
 SG_ UI_lssLkaEnabled : 7|1@1+ (1,0) [0|0] "" Vector__XXX
 SG_ UI_lssLdwEnabled : 8|1@1+ (1,0) [0|0] "" Vector__XXX
 SG_ UI_coastToCoast : 9|1@1+ (1,0) [0|0] "" Vector__XXX
 SG_ UI_autoSummonEnable : 10|1@1+ (1,0) [0|0] "" Vector__XXX
 SG_ UI_exceptionListEnable : 11|1@1+ (1,0) [0|0] "" Vector__XXX
 SG_ UI_roadCheckDisable : 12|1@1+ (1,0) [0|0] "" Vector__XXX
 SG_ UI_driveOnMapsEnable : 13|1@1+ (1,0) [0|0] "" Vector__XXX
 SG_ UI_handsOnRequirementDisable : 14|1@1+ (1,0) [0|0] "" Vector__XXX
 SG_ UI_ulcOffHighway : 15|1@1+ (1,0) [0|0] "" Vector__XXX
 SG_ UI_fuseLanesDisable : 16|1@1+ (1,0) [0|0] "" Vector__XXX
 SG_ UI_fuseHPPDisable : 17|1@1+ (1,0) [0|0] "" Vector__XXX
 SG_ UI_fuseVehiclesDisable : 18|1@1+ (1,0) [0|0] "" Vector__XXX
 SG_ UI_enableClipParkedTelemetry : 19|1@1+ (1,0) [0|0] "" Vector__XXX
 SG_ UI_visionSpeedType : 20|2@1+ (1,0) [0|0] "" Vector__XXX
 SG_ UI_curvatureDatabaseOnly : 22|1@1+ (1,0) [0|0] "" Vector__XXX
 SG_ UI_lssElkEnabled : 23|1@1+ (1,0) [0|0] "" Vector__XXX
 SG_ UI_summonExitType : 24|2@1+ (1,0) [0|0] "" Vector__XXX
 SG_ UI_summonEntryType : 26|2@1+ (1,0) [0|0] "" Vector__XXX
 SG_ UI_selfParkRequest : 28|4@1+ (1,0) [0|0] "" Vector__XXX
 SG_ UI_summonReverseDist : 32|6@1+ (1,0) [0|0] "" Vector__XXX
 SG_ UI_undertakeAssistEnable : 38|1@1+ (1,0) [0|0] "" Vector__XXX
 SG_ UI_adaptiveSetSpeedEnable : 39|1@1+ (1,0) [0|0] "" Vector__XXX
 SG_ UI_drivingSide : 40|2@1+ (1,0) [0|0] "" Vector__XXX
 SG_ UI_enableClipTelemetry : 42|1@1+ (1,0) [0|0] "" Vector__XXX
 SG_ UI_enableTripTelemetry : 43|1@1+ (1,0) [0|0] "" Vector__XXX
 SG_ UI_enableRoadSegmentTelemetry : 44|1@1+ (1,0) [0|0] "" Vector__XXX
 SG_ UI_accFollowDistanceSetting : 45|3@1+ (1,0) [0|0] "" Vector__XXX
 SG_ UI_hasDriveOnNav : 48|1@1+ (1,0) [0|0] "" Vector__XXX
 SG_ UI_followNavRouteEnable : 49|1@1+ (1,0) [0|0] "" Vector__XXX
 SG_ UI_ulcSpeedConfig : 50|2@1+ (1,0) [0|0] "" Vector__XXX
 SG_ UI_ulcBlindSpotConfig : 52|2@1+ (1,0) [0|0] "" Vector__XXX
 SG_ UI_suppressExitPassingLane : 54|1@1+ (1,0) [0|0] "" Vector__XXX
 SG_ UI_enableClipStartStopTelemetry : 55|1@1+ (1,0) [0|0] "" Vector__XXX
 SG_ UI_alcOffHighwayEnable : 56|1@1+ (1,0) [0|0] "" Vector__XXX
 SG_ UI_validationLoop : 57|1@1+ (1,0) [0|0] "" Vector__XXX
 SG_ UI_smartSummonType : 58|2@1+ (1,0) [0|0] "" Vector__XXX
 SG_ UI_enableVisionOnlyStops : 60|1@1+ (1,0) [0|0] "" Vector__XXX
 SG_ UI_source3D : 61|2@1+ (1,0) [0|0] "" Vector__XXX
 SG_ UI_isaSpeedingChimeMuted : 63|1@1+ (1,0) [0|0] "" Vector__XXX

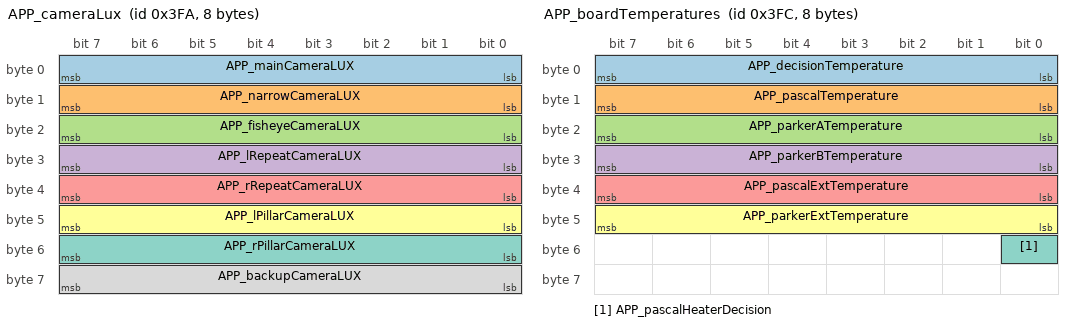
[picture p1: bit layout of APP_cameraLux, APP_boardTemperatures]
BO_ 1018 APP_cameraLux: 8 Vector__XXX
 SG_ APP_mainCameraLUX : 0|8@1+ (0.5,0) [0|0] "" Vector__XXX
 SG_ APP_narrowCameraLUX : 8|8@1+ (0.5,0) [0|0] "" Vector__XXX
 SG_ APP_fisheyeCameraLUX : 16|8@1+ (0.5,0) [0|0] "" Vector__XXX
 SG_ APP_lRepeatCameraLUX : 24|8@1+ (0.5,0) [0|0] "" Vector__XXX
 SG_ APP_rRepeatCameraLUX : 32|8@1+ (0.5,0) [0|0] "" Vector__XXX
 SG_ APP_lPillarCameraLUX : 40|8@1+ (0.5,0) [0|0] "" Vector__XXX
 SG_ APP_rPillarCameraLUX : 48|8@1+ (0.5,0) [0|0] "" Vector__XXX
 SG_ APP_backupCameraLUX : 56|8@1+ (0.5,0) [0|0] "" Vector__XXX

BO_ 1020 APP_boardTemperatures: 8 Vector__XXX
 SG_ APP_decisionTemperature : 0|8@1+ (1,-128) [0|0] "" Vector__XXX
 SG_ APP_pascalTemperature : 8|8@1+ (1,-128) [0|0] "" Vector__XXX
 SG_ APP_parkerATemperature : 16|8@1+ (1,-128) [0|0] "" Vector__XXX
 SG_ APP_parkerBTemperature : 24|8@1+ (1,-128) [0|0] "" Vector__XXX
 SG_ APP_pascalExtTemperature : 32|8@1+ (1,-128) [0|0] "" Vector__XXX
 SG_ APP_parkerExtTemperature : 40|8@1+ (1,-128) [0|0] "" Vector__XXX
 SG_ APP_pascalHeaterDecision : 48|1@1+ (1,0) [0|0] "" Vector__XXX

BO_ 1021 UI_autopilotControl: 8 Vector__XXX
 SG_ UI_autopilotControlIndex M : 0|3@1+ (1,0) [0|0] "" Vector__XXX
 SG_ UI_hovEnabled m0 : 3|1@1+ (1,0) [0|0] "" Vector__XXX
 SG_ UI_donDisableAutoWiperDuration m0 : 4|3@1+ (1,0) [0|0] "" Vector__XXX
 SG_ UI_enableApproachingEmergencyVehicleDetection m2 : 5|1@1+ (1,0) [0|0] "" Vector__XXX
 SG_ UI_enableStartFsdFromParkBrakeConfirmation m2 : 6|1@1+ (1,0) [0|0] "" Vector__XXX
 SG_ UI_donDisableOnAutoWiperSpeed m0 : 7|4@1+ (1,0) [0|0] "" Vector__XXX
 SG_ UI_enableStartFsdFromPark m2 : 7|1@1+ (1,0) [0|0] "" Vector__XXX
 SG_ UI_fsdMaxSpeedOffsetPercentage m2 : 8|6@1+ (1,0) [0|0] "" Vector__XXX
 SG_ UI_selectableCameraRequest m1 : 8|4@1+ (1,0) [0|0] "" Vector__XXX
 SG_ UI_blindspotMinSpeed m0 : 11|4@1+ (1,0) [0|0] "" Vector__XXX
 SG_ UI_blindspotDistance m0 : 15|3@1+ (1,0) [0|0] "" Vector__XXX
 SG_ UI_coldStartMonarchInFactory m2 : 16|1@1+ (1,0) [0|0] "" Vector__XXX
 SG_ UI_overrideSleepWithSuspend m1 : 16|1@1+ (1,0) [0|0] "" Vector__XXX
 SG_ UI_driverMonitorConfirmation m1 : 17|1@1+ (1,0) [0|0] "" Vector__XXX
 SG_ UI_blindspotTTC m0 : 18|3@1+ (1,0) [0|0] "" Vector__XXX
 SG_ UI_parkAssistUseVision m1 : 18|1@1+ (1,0) [0|0] "" Vector__XXX
 SG_ UI_applyEceR79 m1 : 19|1@1+ (1,0) [0|0] "" Vector__XXX
 SG_ UI_enableMapStops m1 : 20|1@1+ (1,0) [0|0] "" Vector__XXX
 SG_ UI_donStopEndOfRampBuffer m0 : 21|3@1+ (1,0) [0|0] "" Vector__XXX
 SG_ UI_disableMain m1 : 23|1@1+ (1,0) [0|0] "" Vector__XXX
 SG_ UI_disableNarrow m1 : 24|1@1+ (1,0) [0|0] "" Vector__XXX
 SG_ UI_donDisableCutin m0 : 24|1@1+ (1,0) [0|0] "" Vector__XXX
 SG_ UI_disableFisheye m1 : 25|1@1+ (1,0) [0|0] "" Vector__XXX
 SG_ UI_smartSetSpeedOffset m0 : 25|6@1+ (1,-30) [0|0] "" Vector__XXX
 SG_ UI_disableLeftPillar m1 : 26|1@1+ (1,0) [0|0] "" Vector__XXX
 SG_ UI_disableRightPillar m1 : 27|1@1+ (1,0) [0|0] "" Vector__XXX
 SG_ UI_disableLeftRepeater m1 : 28|1@1+ (1,0) [0|0] "" Vector__XXX
 SG_ UI_disableRightRepeater m1 : 29|1@1+ (1,0) [0|0] "" Vector__XXX
 SG_ UI_disableBackup m1 : 30|1@1+ (1,0) [0|0] "" Vector__XXX
 SG_ UI_disableRadar m1 : 31|1@1+ (1,0) [0|0] "" Vector__XXX
 SG_ UI_smartSetSpeedOffsetType m0 : 31|1@1+ (1,0) [0|0] "" Vector__XXX
 SG_ UI_autopilotMonarchBackup m0 : 32|1@1+ (1,0) [0|0] "" Vector__XXX
 SG_ UI_noStalkConfirmAlertHaptic m1 : 32|1@1+ (1,0) [0|0] "" Vector__XXX
 SG_ UI_regulatoryLKA m1 : 33|1@1+ (1,0) [0|0] "" Vector__XXX
 SG_ UI_regulatoryLaneAssistLevel m1 : 34|1@1+ (1,0) [0|0] "" Vector__XXX
 SG_ UI_ulcSnooze m1 : 36|1@1+ (1,0) [0|0] "" Vector__XXX
 SG_ UI_fsdVisualizationEnabled m0 : 37|1@1+ (1,0) [0|0] "" Vector__XXX
 SG_ UI_noStalkConfirmAlertChime m1 : 37|1@1+ (1,0) [0|0] "" Vector__XXX
 SG_ UI_fsdStopsControlEnabled m0 : 38|1@1+ (1,0) [0|0] "" Vector__XXX
 SG_ UI_factorySummonEnable m1 : 39|1@1+ (1,0) [0|0] "" Vector__XXX
 SG_ UI_fsdContinueOnGreenWithCIPV m0 : 39|1@1+ (1,0) [0|0] "" Vector__XXX
 SG_ UI_apmv3Branch m1 : 40|3@1+ (1,0) [0|0] "" Vector__XXX
 SG_ UI_smartSetSpeed m0 : 40|1@1+ (1,0) [0|0] "" Vector__XXX
 SG_ UI_automaticSetSpeedOffset m0 : 41|1@1+ (1,0) [0|0] "" Vector__XXX
 SG_ UI_apply2021_1958_ISA m0 : 42|1@1+ (1,0) [0|0] "" Vector__XXX
 SG_ UI_apply2021_646_ELKS m0 : 43|1@1+ (1,0) [0|0] "" Vector__XXX
 SG_ UI_enableCabinCamera m1 : 43|1@1+ (1,0) [0|0] "" Vector__XXX
 SG_ UI_apply2021_1341_DDAW m0 : 44|1@1+ (1,0) [0|0] "" Vector__XXX
 SG_ UI_enableAutopilotStopWarning m1 : 44|1@1+ (1,0) [0|0] "" Vector__XXX
 SG_ UI_homelinkNearby m0 : 45|1@1+ (1,0) [0|0] "" Vector__XXX
 SG_ UI_showLaneGraph m1 : 45|1@1+ (1,0) [0|0] "" Vector__XXX
 SG_ UI_enableFullSelfDriving m0 : 46|1@1+ (1,0) [0|0] "" Vector__XXX
 SG_ UI_showTrackLabels m1 : 46|1@1+ (1,0) [0|0] "" Vector__XXX
 SG_ UI_hardCoreSummon m1 : 47|1@1+ (1,0) [0|0] "" Vector__XXX
 SG_ UI_hasFullSelfDriving m0 : 47|1@1+ (1,0) [0|0] "" Vector__XXX
 SG_ UI_autosteerActivation m0 : 48|1@1+ (1,0) [0|0] "" Vector__XXX
 SG_ UI_enableCabinCameraTelemetry m1 : 48|1@1+ (1,0) [0|0] "" Vector__XXX
 SG_ UI_autopilotDrivingProfile m0 : 49|2@1+ (1,0) [0|0] "" Vector__XXX
 SG_ UI_enableVisionSpeedControl m1 : 49|1@1+ (1,0) [0|0] "" Vector__XXX
 SG_ UI_autopilotTelemetryInChina m1 : 50|1@1+ (1,0) [0|0] "" Vector__XXX
 SG_ UI_enableTeslaAutopark m1 : 51|1@1+ (1,0) [0|0] "" Vector__XXX
 SG_ UI_fsdBetaRequest m0 : 51|1@1+ (1,0) [0|0] "" Vector__XXX
 SG_ UI_autoTurnSignalMode m1 : 52|1@1+ (1,0) [0|0] "" Vector__XXX
 SG_ UI_fullSelfDrivingSuspended m0 : 52|1@1+ (1,0) [0|0] "" Vector__XXX
 SG_ UI_disableOptionalLaneChanges m0 : 53|1@1+ (1,0) [0|0] "" Vector__XXX
 SG_ UI_enableCautionLightControl m1 : 54|1@1+ (1,0) [0|0] "" Vector__XXX
 SG_ UI_applyEceR79SmartSummonOnly m1 : 55|1@1+ (1,0) [0|0] "" Vector__XXX
 SG_ UI_autopilotMonarchEnabled m1 : 56|1@1+ (1,0) [0|0] "" Vector__XXX
 SG_ UI_autopilotEphemerisEnabled m1 : 57|1@1+ (1,0) [0|0] "" Vector__XXX
 SG_ UI_applyR152_AEBS m0 : 59|1@1+ (1,0) [0|0] "" Vector__XXX
 SG_ UI_enableCabinAudioRecording m1 : 59|1@1+ (1,0) [0|0] "" Vector__XXX
 SG_ UI_autopilotControlMux0Valid m0 : 63|1@1+ (1,0) [0|0] "" Vector__XXX
 SG_ UI_autopilotControlMux1Valid m1 : 63|1@1+ (1,0) [0|0] "" Vector__XXX
 SG_ UI_autopilotControlMux2Valid m2 : 63|1@1+ (1,0) [0|0] "" Vector__XXX

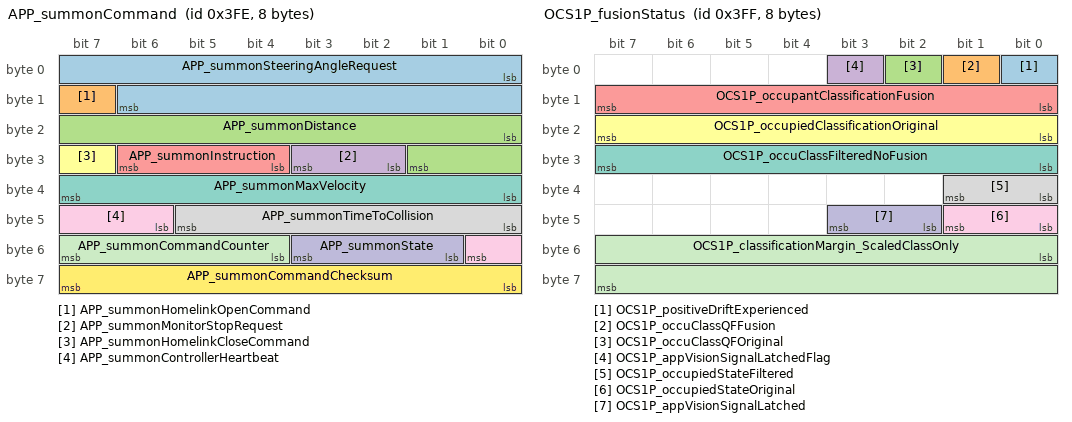
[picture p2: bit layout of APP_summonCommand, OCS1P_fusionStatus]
BO_ 1022 APP_summonCommand: 8 Vector__XXX
 SG_ APP_summonSteeringAngleRequest : 0|15@1+ (0.1,-1638.35) [0|0] "" Vector__XXX
 SG_ APP_summonHomelinkOpenCommand : 15|1@1+ (1,0) [0|0] "" Vector__XXX
 SG_ APP_summonDistance : 16|10@1+ (0.02,0) [0|0] "" Vector__XXX
 SG_ APP_summonMonitorStopRequest : 26|2@1+ (1,0) [0|0] "" Vector__XXX
 SG_ APP_summonInstruction : 28|3@1+ (1,0) [0|0] "" Vector__XXX
 SG_ APP_summonHomelinkCloseCommand : 31|1@1+ (1,0) [0|0] "" Vector__XXX
 SG_ APP_summonMaxVelocity : 32|8@1+ (0.05,0) [0|0] "" Vector__XXX
 SG_ APP_summonTimeToCollision : 40|6@1+ (0.1,0) [0|0] "" Vector__XXX
 SG_ APP_summonControllerHeartbeat : 46|3@1+ (1,0) [0|0] "" Vector__XXX
 SG_ APP_summonState : 49|3@1+ (1,0) [0|0] "" Vector__XXX
 SG_ APP_summonCommandCounter : 52|4@1+ (1,0) [0|0] "" Vector__XXX
 SG_ APP_summonCommandChecksum : 56|8@1+ (1,0) [0|0] "" Vector__XXX

BO_ 1023 OCS1P_fusionStatus: 8 Vector__XXX
 SG_ OCS1P_positiveDriftExperienced : 0|1@1+ (1,0) [0|0] "" Vector__XXX
 SG_ OCS1P_occuClassQFFusion : 1|1@1+ (1,0) [0|0] "" Vector__XXX
 SG_ OCS1P_occuClassQFOriginal : 2|1@1+ (1,0) [0|0] "" Vector__XXX
 SG_ OCS1P_appVisionSignalLatchedFlag : 3|1@1+ (1,0) [0|0] "" Vector__XXX
 SG_ OCS1P_occupantClassificationFusion : 8|8@1+ (1,0) [0|0] "" Vector__XXX
 SG_ OCS1P_occupiedClassificationOriginal : 16|8@1+ (1,0) [0|0] "" Vector__XXX
 SG_ OCS1P_occuClassFilteredNoFusion : 24|8@1+ (1,0) [0|0] "" Vector__XXX
 SG_ OCS1P_occupiedStateFiltered : 32|2@1+ (1,0) [0|0] "" Vector__XXX
 SG_ OCS1P_occupiedStateOriginal : 40|2@1+ (1,0) [0|0] "" Vector__XXX
 SG_ OCS1P_appVisionSignalLatched : 42|2@1+ (1,0) [0|0] "" Vector__XXX
 SG_ OCS1P_classificationMargin_ScaledClassOnly : 48|16@1- (2,0) [0|0] "" Vector__XXX

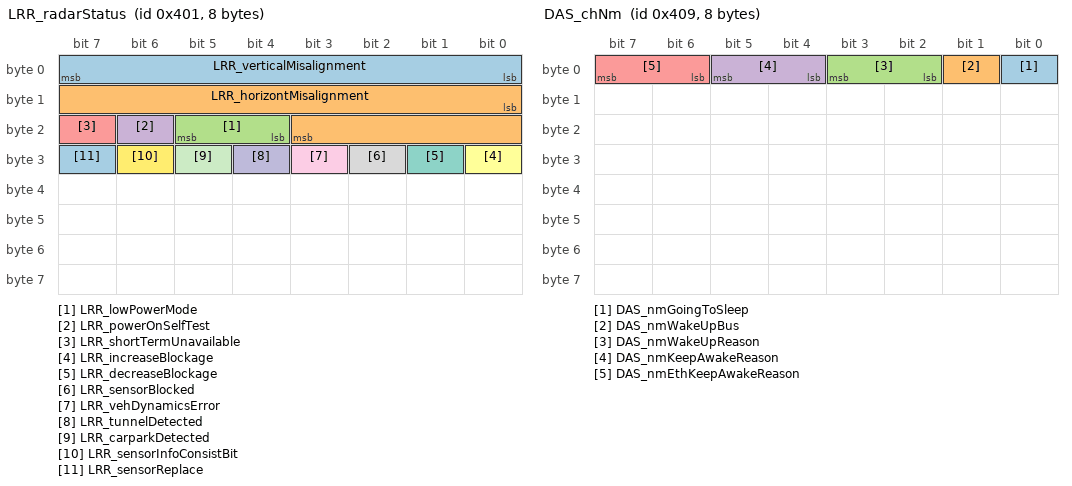
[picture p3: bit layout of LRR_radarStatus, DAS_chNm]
BO_ 1025 LRR_radarStatus: 8 Vector__XXX
 SG_ LRR_verticalMisalignment : 0|8@1+ (0.001953125,-0.25) [0|0] "" Vector__XXX
 SG_ LRR_horizontMisalignment : 8|12@1+ (0.0001220703125,-0.25) [0|0] "" Vector__XXX
 SG_ LRR_lowPowerMode : 20|2@1+ (1,0) [0|0] "" Vector__XXX
 SG_ LRR_powerOnSelfTest : 22|1@1+ (1,0) [0|0] "" Vector__XXX
 SG_ LRR_shortTermUnavailable : 23|1@1+ (1,0) [0|0] "" Vector__XXX
 SG_ LRR_increaseBlockage : 24|1@1+ (1,0) [0|0] "" Vector__XXX
 SG_ LRR_decreaseBlockage : 25|1@1+ (1,0) [0|0] "" Vector__XXX
 SG_ LRR_sensorBlocked : 26|1@1+ (1,0) [0|0] "" Vector__XXX
 SG_ LRR_vehDynamicsError : 27|1@1+ (1,0) [0|0] "" Vector__XXX
 SG_ LRR_tunnelDetected : 28|1@1+ (1,0) [0|0] "" Vector__XXX
 SG_ LRR_carparkDetected : 29|1@1+ (1,0) [0|0] "" Vector__XXX
 SG_ LRR_sensorInfoConsistBit : 30|1@1+ (1,0) [0|0] "" Vector__XXX
 SG_ LRR_sensorReplace : 31|1@1+ (1,0) [0|0] "" Vector__XXX

BO_ 1029 GTW_vin: 8 Vector__XXX
 SG_ GTW_vinIndex M : 7|8@0+ (1,0) [0|0] "" Vector__XXX
 SG_ GTW_vinLow m18 : 15|56@0+ (1,0) [0|0] "" Vector__XXX
 SG_ GTW_vinMid m17 : 15|56@0+ (1,0) [0|0] "" Vector__XXX
 SG_ GTW_vinHigh m16 : 47|24@0+ (1,0) [0|0] "" Vector__XXX

BO_ 1030 DAS_robDebug: 8 Vector__XXX
 SG_ DAS_eObjMultiplexer M : 0|4@1+ (1,0) [0|0] "" Vector__XXX
 SG_ DAS_eObj00Valid m0 : 4|1@1+ (1,0) [0|0] "" Vector__XXX
 SG_ DAS_eObj01Valid m1 : 4|1@1+ (1,0) [0|0] "" Vector__XXX
 SG_ DAS_eObj02Valid m2 : 4|1@1+ (1,0) [0|0] "" Vector__XXX
 SG_ DAS_eObj03Valid m3 : 4|1@1+ (1,0) [0|0] "" Vector__XXX
 SG_ DAS_eObj00Age m0 : 5|3@1+ (1,0) [0|0] "" Vector__XXX
 SG_ DAS_eObj01Age m1 : 5|3@1+ (1,0) [0|0] "" Vector__XXX
 SG_ DAS_eObj02Age m2 : 5|3@1+ (1,0) [0|0] "" Vector__XXX
 SG_ DAS_eObj03Age m3 : 5|3@1+ (1,0) [0|0] "" Vector__XXX
 SG_ DAS_eObj00PositionX m0 : 8|8@1+ (0.5,0) [0|0] "" Vector__XXX
 SG_ DAS_eObj01PositionX m1 : 8|8@1+ (0.5,0) [0|0] "" Vector__XXX
 SG_ DAS_eObj02PositionX m2 : 8|8@1+ (0.5,0) [0|0] "" Vector__XXX
 SG_ DAS_eObj03PositionX m3 : 8|8@1+ (0.5,0) [0|0] "" Vector__XXX
 SG_ DAS_robClusterStart m5 : 8|8@1+ (1,-95) [0|0] "" Vector__XXX
 SG_ DAS_robPossibleCollision m4 : 8|1@1+ (1,0) [0|0] "" Vector__XXX
 SG_ DAS_robActiveBraking m4 : 9|1@1+ (1,0) [0|0] "" Vector__XXX
 SG_ DAS_robRequestEventRecorder m4 : 10|1@1+ (1,0) [0|0] "" Vector__XXX
 SG_ DAS_robInfrastructure m4 : 11|1@1+ (1,0) [0|0] "" Vector__XXX
 SG_ DAS_robAEBAlertLatch m4 : 12|1@1+ (1,0) [0|0] "" Vector__XXX
 SG_ DAS_robMapTrusted m4 : 13|1@1+ (1,0) [0|0] "" Vector__XXX
 SG_ DAS_eObj00PositionY m0 : 16|8@1+ (0.25,-31.875) [0|0] "" Vector__XXX
 SG_ DAS_eObj01PositionY m1 : 16|8@1+ (0.25,-31.875) [0|0] "" Vector__XXX
 SG_ DAS_eObj02PositionY m2 : 16|8@1+ (0.25,-31.875) [0|0] "" Vector__XXX
 SG_ DAS_eObj03PositionY m3 : 16|8@1+ (0.25,-31.875) [0|0] "" Vector__XXX
 SG_ DAS_robClusterEnd m5 : 16|8@1+ (1,0) [0|0] "" Vector__XXX
 SG_ DAS_robCollisionConf m4 : 16|4@1+ (1,0) [0|0] "" Vector__XXX
 SG_ DAS_robCriticalObjAge m4 : 20|4@1+ (1,0) [0|0] "" Vector__XXX
 SG_ DAS_eObj00Moment0 m0 : 24|8@1+ (0.25,-31.875) [0|0] "" Vector__XXX
 SG_ DAS_eObj01Moment0 m1 : 24|8@1+ (0.25,-31.875) [0|0] "" Vector__XXX
 SG_ DAS_eObj02Moment0 m2 : 24|8@1+ (0.25,-31.875) [0|0] "" Vector__XXX
 SG_ DAS_eObj03Moment0 m3 : 24|8@1+ (0.25,-31.875) [0|0] "" Vector__XXX
 SG_ DAS_robCriticalObjIndex m4 : 24|4@1+ (1,0) [0|0] "" Vector__XXX
 SG_ DAS_robMapTrust m5 : 24|1@1+ (1,0) [0|0] "" Vector__XXX
 SG_ DAS_robEnableBraking m5 : 25|1@1+ (1,0) [0|0] "" Vector__XXX
 SG_ DAS_robGPSHealthy m5 : 26|1@1+ (1,0) [0|0] "" Vector__XXX
 SG_ DAS_robRadarFault m5 : 27|1@1+ (1,0) [0|0] "" Vector__XXX
 SG_ DAS_robRadarBlind m5 : 28|1@1+ (1,0) [0|0] "" Vector__XXX
 SG_ DAS_robActiveLogging m5 : 29|1@1+ (1,0) [0|0] "" Vector__XXX
 SG_ DAS_eObj00Moment1 m0 : 32|8@1+ (0.25,-31.875) [0|0] "" Vector__XXX
 SG_ DAS_eObj01Moment1 m1 : 32|8@1+ (0.25,-31.875) [0|0] "" Vector__XXX
 SG_ DAS_eObj02Moment1 m2 : 32|8@1+ (0.25,-31.875) [0|0] "" Vector__XXX
 SG_ DAS_eObj03Moment1 m3 : 32|8@1+ (0.25,-31.875) [0|0] "" Vector__XXX
 SG_ DAS_robDistanceObstacle m4 : 32|8@1+ (1,0) [0|0] "" Vector__XXX
 SG_ DAS_eObj00Moment2 m0 : 40|8@1+ (0.25,-31.875) [0|0] "" Vector__XXX
 SG_ DAS_eObj01Moment2 m1 : 40|8@1+ (0.25,-31.875) [0|0] "" Vector__XXX
 SG_ DAS_eObj02Moment2 m2 : 40|8@1+ (0.25,-31.875) [0|0] "" Vector__XXX
 SG_ DAS_eObj03Moment2 m3 : 40|8@1+ (0.25,-31.875) [0|0] "" Vector__XXX
 SG_ DAS_robWidthObstacle m4 : 40|8@1+ (0.1,0) [0|0] "" Vector__XXX
 SG_ DAS_eObj00Moment3 m0 : 48|8@1+ (0.25,-31.875) [0|0] "" Vector__XXX
 SG_ DAS_eObj01Moment3 m1 : 48|8@1+ (0.25,-31.875) [0|0] "" Vector__XXX
 SG_ DAS_eObj02Moment3 m2 : 48|8@1+ (0.25,-31.875) [0|0] "" Vector__XXX
 SG_ DAS_eObj03Moment3 m3 : 48|8@1+ (0.25,-31.875) [0|0] "" Vector__XXX
 SG_ DAS_robOverlapObstacle m4 : 48|8@1+ (0.1,0) [0|0] "" Vector__XXX
 SG_ DAS_eObj00InPath m0 : 56|1@1+ (1,0) [0|0] "" Vector__XXX
 SG_ DAS_eObj01InPath m1 : 56|1@1+ (1,0) [0|0] "" Vector__XXX
 SG_ DAS_eObj02InPath m2 : 56|1@1+ (1,0) [0|0] "" Vector__XXX
 SG_ DAS_eObj03InPath m3 : 56|1@1+ (1,0) [0|0] "" Vector__XXX
 SG_ DAS_robTimeCollision m4 : 56|8@1+ (0.05,0) [0|0] "" Vector__XXX
 SG_ DAS_eObj00Blacklist m0 : 57|1@1+ (1,0) [0|0] "" Vector__XXX
 SG_ DAS_eObj01Blacklist m1 : 57|1@1+ (1,0) [0|0] "" Vector__XXX
 SG_ DAS_eObj02Blacklist m2 : 57|1@1+ (1,0) [0|0] "" Vector__XXX
 SG_ DAS_eObj03Blacklist m3 : 57|1@1+ (1,0) [0|0] "" Vector__XXX
 SG_ DAS_eObj00Elevated m0 : 58|1@1+ (1,0) [0|0] "" Vector__XXX
 SG_ DAS_eObj01Elevated m1 : 58|1@1+ (1,0) [0|0] "" Vector__XXX
 SG_ DAS_eObj02Elevated m2 : 58|1@1+ (1,0) [0|0] "" Vector__XXX
 SG_ DAS_eObj03Elevated m3 : 58|1@1+ (1,0) [0|0] "" Vector__XXX

BO_ 1033 DAS_chNm: 8 Vector__XXX
 SG_ DAS_nmGoingToSleep : 0|1@1+ (1,0) [0|0] "" Vector__XXX
 SG_ DAS_nmWakeUpBus : 1|1@1+ (1,0) [0|0] "" Vector__XXX
 SG_ DAS_nmWakeUpReason : 2|2@1+ (1,0) [0|0] "" Vector__XXX
 SG_ DAS_nmKeepAwakeReason : 4|2@1+ (1,0) [0|0] "" Vector__XXX
 SG_ DAS_nmEthKeepAwakeReason : 6|2@1+ (1,0) [0|0] "" Vector__XXX

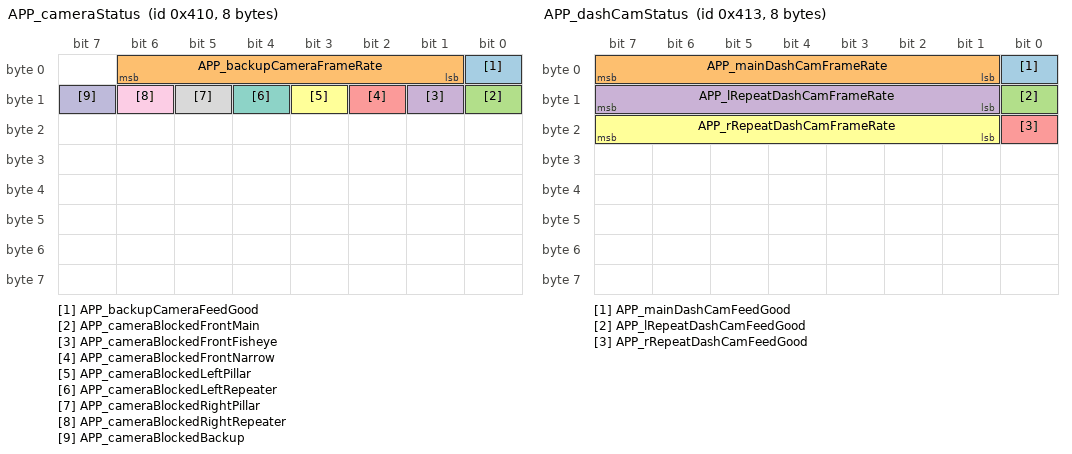
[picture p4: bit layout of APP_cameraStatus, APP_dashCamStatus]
BO_ 1040 APP_cameraStatus: 8 Vector__XXX
 SG_ APP_backupCameraFeedGood : 0|1@1+ (1,0) [0|0] "" Vector__XXX
 SG_ APP_backupCameraFrameRate : 1|6@1+ (1,0) [0|0] "" Vector__XXX
 SG_ APP_cameraBlockedFrontMain : 8|1@1+ (1,0) [0|0] "" Vector__XXX
 SG_ APP_cameraBlockedFrontFisheye : 9|1@1+ (1,0) [0|0] "" Vector__XXX
 SG_ APP_cameraBlockedFrontNarrow : 10|1@1+ (1,0) [0|0] "" Vector__XXX
 SG_ APP_cameraBlockedLeftPillar : 11|1@1+ (1,0) [0|0] "" Vector__XXX
 SG_ APP_cameraBlockedLeftRepeater : 12|1@1+ (1,0) [0|0] "" Vector__XXX
 SG_ APP_cameraBlockedRightPillar : 13|1@1+ (1,0) [0|0] "" Vector__XXX
 SG_ APP_cameraBlockedRightRepeater : 14|1@1+ (1,0) [0|0] "" Vector__XXX
 SG_ APP_cameraBlockedBackup : 15|1@1+ (1,0) [0|0] "" Vector__XXX

BO_ 1043 APP_dashCamStatus: 8 Vector__XXX
 SG_ APP_mainDashCamFeedGood : 0|1@1+ (1,0) [0|0] "" Vector__XXX
 SG_ APP_mainDashCamFrameRate : 1|7@1+ (1,0) [0|0] "" Vector__XXX
 SG_ APP_lRepeatDashCamFeedGood : 8|1@1+ (1,0) [0|0] "" Vector__XXX
 SG_ APP_lRepeatDashCamFrameRate : 9|7@1+ (1,0) [0|0] "" Vector__XXX
 SG_ APP_rRepeatDashCamFeedGood : 16|1@1+ (1,0) [0|0] "" Vector__XXX
 SG_ APP_rRepeatDashCamFrameRate : 17|7@1+ (1,0) [0|0] "" Vector__XXX

BO_ 1045 APP_backupDashCamStatus: 8 Vector__XXX
 SG_ APP_backupDashCamFeedGood : 0|1@1+ (1,0) [0|0] "" Vector__XXX
 SG_ APP_backupDashCamFrameRate : 1|7@1+ (1,0) [0|0] "" Vector__XXX

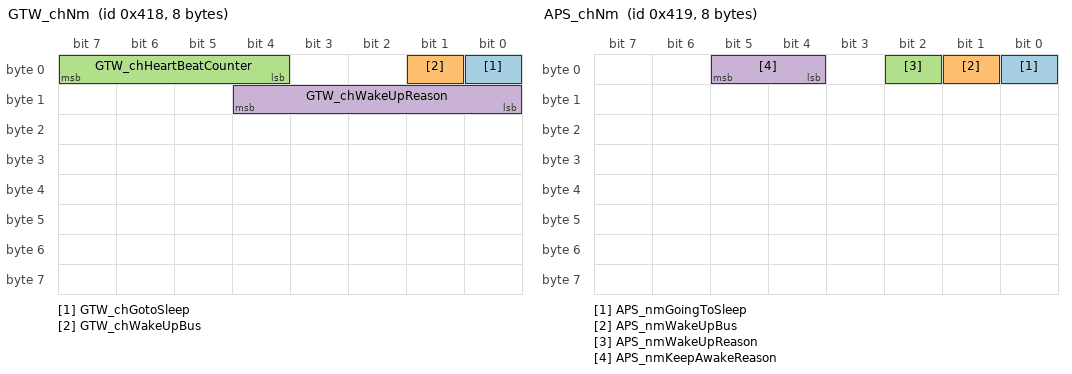
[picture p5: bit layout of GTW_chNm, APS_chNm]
BO_ 1048 GTW_chNm: 8 Vector__XXX
 SG_ GTW_chGotoSleep : 0|1@1+ (1,0) [0|0] "" Vector__XXX
 SG_ GTW_chWakeUpBus : 1|1@1+ (1,0) [0|0] "" Vector__XXX
 SG_ GTW_chHeartBeatCounter : 4|4@1+ (1,0) [0|0] "" Vector__XXX
 SG_ GTW_chWakeUpReason : 8|5@1+ (1,0) [0|0] "" Vector__XXX

BO_ 1049 APS_chNm: 8 Vector__XXX
 SG_ APS_nmGoingToSleep : 0|1@1+ (1,0) [0|0] "" Vector__XXX
 SG_ APS_nmWakeUpBus : 1|1@1+ (1,0) [0|0] "" Vector__XXX
 SG_ APS_nmWakeUpReason : 2|1@1+ (1,0) [0|0] "" Vector__XXX
 SG_ APS_nmKeepAwakeReason : 4|2@1+ (1,0) [0|0] "" Vector__XXX

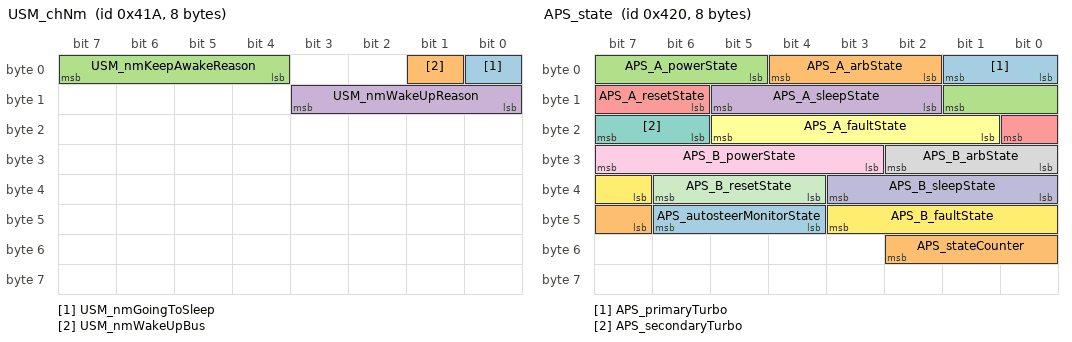
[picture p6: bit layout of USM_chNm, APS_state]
BO_ 1050 USM_chNm: 8 Vector__XXX
 SG_ USM_nmGoingToSleep : 0|1@1+ (1,0) [0|0] "" Vector__XXX
 SG_ USM_nmWakeUpBus : 1|1@1+ (1,0) [0|0] "" Vector__XXX
 SG_ USM_nmKeepAwakeReason : 4|4@1+ (1,0) [0|0] "" Vector__XXX
 SG_ USM_nmWakeUpReason : 8|4@1+ (1,0) [0|0] "" Vector__XXX

BO_ 1056 APS_state: 8 Vector__XXX
 SG_ APS_primaryTurbo : 0|2@1+ (1,0) [0|0] "" Vector__XXX
 SG_ APS_A_arbState : 2|3@1+ (1,0) [0|0] "" Vector__XXX
 SG_ APS_A_powerState : 5|5@1+ (1,0) [0|0] "" Vector__XXX
 SG_ APS_A_sleepState : 10|4@1+ (1,0) [0|0] "" Vector__XXX
 SG_ APS_A_resetState : 14|3@1+ (1,0) [0|0] "" Vector__XXX
 SG_ APS_A_faultState : 17|5@1+ (1,0) [0|0] "" Vector__XXX
 SG_ APS_secondaryTurbo : 22|2@1+ (1,0) [0|0] "" Vector__XXX
 SG_ APS_B_arbState : 24|3@1+ (1,0) [0|0] "" Vector__XXX
 SG_ APS_B_powerState : 27|5@1+ (1,0) [0|0] "" Vector__XXX
 SG_ APS_B_sleepState : 32|4@1+ (1,0) [0|0] "" Vector__XXX
 SG_ APS_B_resetState : 36|3@1+ (1,0) [0|0] "" Vector__XXX
 SG_ APS_B_faultState : 39|5@1+ (1,0) [0|0] "" Vector__XXX
 SG_ APS_autosteerMonitorState : 44|3@1+ (1,0) [0|0] "" Vector__XXX
 SG_ APS_stateCounter : 47|4@1+ (1,0) [0|0] "" Vector__XXX

BO_ 1060 PCS_alertLog: 8 Vector__XXX
 SG_ PCS_alertID M : 0|7@1+ (1,0) [0|0] "" Vector__XXX
 SG_ PCS_alertSet : 15|1@1+ (1,0) [0|0] "" Vector__XXX
 SG_ PCS_a001_llcFrequency m1 : 16|8@1+ (1,50) [0|0] "" Vector__XXX
 SG_ PCS_a002_phState m2 : 16|4@1+ (1,0) [0|0] "" Vector__XXX
 SG_ PCS_a003_phState m3 : 16|4@1+ (1,0) [0|0] "" Vector__XXX
 SG_ PCS_a004_phState m4 : 16|4@1+ (1,0) [0|0] "" Vector__XXX
 SG_ PCS_a005_outputV m5 : 16|8@1+ (2,0) [0|0] "" Vector__XXX
 SG_ PCS_a006_phState m6 : 16|4@1+ (1,0) [0|0] "" Vector__XXX
 SG_ PCS_a007_phATemperature m7 : 16|7@1+ (1,0) [0|0] "" Vector__XXX
 SG_ PCS_a008_phState m8 : 16|4@1+ (1,0) [0|0] "" Vector__XXX
 SG_ PCS_a009_phState m9 : 16|4@1+ (1,0) [0|0] "" Vector__XXX
 SG_ PCS_a010_phState m10 : 16|4@1+ (1,0) [0|0] "" Vector__XXX
 SG_ PCS_a011_phState m11 : 16|4@1+ (1,0) [0|0] "" Vector__XXX
 SG_ PCS_a012_phState m12 : 16|4@1+ (1,0) [0|0] "" Vector__XXX
 SG_ PCS_a013_phState m13 : 16|4@1+ (1,0) [0|0] "" Vector__XXX
 SG_ PCS_a014_phaTemperature m14 : 16|11@1- (0.1,40) [0|0] "" Vector__XXX
 SG_ PCS_a015_lvBusVoltage m15 : 16|8@1+ (0.15625,0) [0|0] "" Vector__XXX
 SG_ PCS_a016_phAVoltSrcMissingDetected m16 : 16|1@1+ (1,0) [0|0] "" Vector__XXX
 SG_ PCS_a018_PhaseDiff_L1N_L2N m18 : 16|9@1+ (1,-1) [0|0] "" Vector__XXX
 SG_ PCS_a019_pcsMaxAvailablePower m19 : 16|8@1+ (0.1,0) [0|0] "" Vector__XXX
 SG_ PCS_a020_chargeEnableLine m20 : 16|1@1+ (1,0) [0|0] "" Vector__XXX
 SG_ PCS_a021_HVP_hvsControl m21 : 16|1@1+ (1,0) [0|0] "" Vector__XXX
 SG_ PCS_a022_BMS_pcsRequest m22 : 16|1@1+ (1,0) [0|0] "" Vector__XXX
 SG_ PCS_a023_CP_chargeStatus m23 : 16|1@1+ (1,0) [0|0] "" Vector__XXX
 SG_ PCS_a024_VCFRONT_sensors m24 : 16|1@1+ (1,0) [0|0] "" Vector__XXX
 SG_ PCS_a025_cpu2ErrorCode m25 : 16|4@1+ (1,0) [0|0] "" Vector__XXX
 SG_ PCS_a026_CPU1_watchdog_alarmed m26 : 16|1@1+ (1,0) [0|0] "" Vector__XXX
 SG_ PCS_a027_chgPhATemp m27 : 16|8@1- (1,40) [0|0] "" Vector__XXX
 SG_ PCS_a028_outputV m28 : 16|10@1+ (0.5,0) [0|0] "" Vector__XXX
 SG_ PCS_a029_inputVrms m29 : 16|9@1+ (1,0) [0|0] "" Vector__XXX
 SG_ PCS_a030_canRxErrorType m30 : 16|3@1+ (1,0) [0|0] "" Vector__XXX
 SG_ PCS_a031_UI_chargeRequest m31 : 16|1@1+ (1,0) [0|0] "" Vector__XXX
 SG_ PCS_a032_phATransientRetryCount m32 : 16|9@1+ (0.1,0) [0|0] "" Vector__XXX
 SG_ PCS_a033_HV_busV m33 : 16|12@1+ (0.146484375,0) [0|0] "" Vector__XXX
 SG_ PCS_a034_HV_busV m34 : 16|12@1+ (0.146484375,0) [0|0] "" Vector__XXX
 SG_ PCS_a035_LV_busV m35 : 16|12@1+ (0.009765625,0) [0|0] "" Vector__XXX
 SG_ PCS_a036_LV_busV m36 : 16|12@1+ (0.009765625,0) [0|0] "" Vector__XXX
 SG_ PCS_a037_dcdcPwmDeassertedCount m37 : 16|8@1+ (1,0) [0|0] "" Vector__XXX
 SG_ PCS_a038_dcdcClaFaultCode m38 : 16|4@1+ (1,0) [0|0] "" Vector__XXX
 SG_ PCS_a039_SDModuleClockFault_HV m39 : 16|1@1+ (1,0) [0|0] "" Vector__XXX
 SG_ PCS_a040_dcdcLvVoltageTarget m40 : 16|8@1+ (0.1,0) [0|0] "" Vector__XXX
 SG_ PCS_a041_dcdcTemperature m41 : 16|11@1- (0.1,40) [0|0] "" Vector__XXX
 SG_ PCS_a042_dcdcEnableLine m42 : 16|1@1+ (1,0) [0|0] "" Vector__XXX
 SG_ PCS_a043_dcdcLvBusV m43 : 16|10@1+ (0.0390625,0) [0|0] "" Vector__XXX
 SG_ PCS_a044_FaultReasonCode m44 : 16|2@1+ (1,0) [0|0] "" Vector__XXX
 SG_ PCS_a045_hvBusEstimated_C_uF m45 : 16|10@1+ (7.820136852394917,0) [0|0] "" Vector__XXX
 SG_ PCS_a046_hvBusEstimated_C_uF m46 : 16|10@1+ (7.820136852394917,0) [0|0] "" Vector__XXX
 SG_ PCS_a047_cpu1BootLoaderCrcMismatch m47 : 16|1@1+ (1,0) [0|0] "" Vector__XXX
 SG_ PCS_a048_assertionReason m48 : 16|1@1+ (1,0) [0|0] "" Vector__XXX
 SG_ PCS_a049_dcdcTemperature m49 : 16|11@1- (0.1,40) [0|0] "" Vector__XXX
 SG_ PCS_a051_phState m51 : 16|4@1+ (1,0) [0|0] "" Vector__XXX
 SG_ PCS_a052_inputVrms m52 : 16|9@1+ (1,0) [0|0] "" Vector__XXX
 SG_ PCS_a053_inputVrms m53 : 16|9@1+ (1,0) [0|0] "" Vector__XXX
 SG_ PCS_a054_inputVrms m54 : 16|9@1+ (1,0) [0|0] "" Vector__XXX
 SG_ PCS_a057_inputVrms m57 : 16|10@1+ (0.5,0) [0|0] "" Vector__XXX
 SG_ PCS_a058_inputVrms m58 : 16|10@1+ (0.5,0) [0|0] "" Vector__XXX
 SG_ PCS_a059_inputVrms m59 : 16|10@1+ (0.5,0) [0|0] "" Vector__XXX
 SG_ PCS_a060_inputVPeak m60 : 16|10@1+ (0.5,0) [0|0] "" Vector__XXX
 SG_ PCS_a061_chgInputVdcOffset_L1N m61 : 16|8@1+ (1,0) [0|0] "" Vector__XXX
 SG_ PCS_a062_chgInputIOffset m62 : 16|12@1- (0.01,0) [0|0] "" Vector__XXX
 SG_ PCS_a063_chgOutputV m63 : 16|10@1+ (1,0) [0|0] "" Vector__XXX
 SG_ PCS_a064_chgOutputIOffset m64 : 16|12@1- (0.01,0) [0|0] "" Vector__XXX
 SG_ PCS_a065_inputVrms m65 : 16|10@1+ (0.5,0) [0|0] "" Vector__XXX
 SG_ PCS_a066_dcdcHvBusVolt m66 : 16|14@1+ (0.1,0) [0|0] "" Vector__XXX
 SG_ PCS_a067_dcdcLvBusVolt m67 : 16|13@1+ (0.01,0) [0|0] "" Vector__XXX
 SG_ PCS_a068_dcdcTankVolt m68 : 16|16@1- (0.03051757813,0) [0|0] "" Vector__XXX
 SG_ PCS_a069_phState m69 : 16|4@1+ (1,0) [0|0] "" Vector__XXX
 SG_ PCS_a070_phState m70 : 16|4@1+ (1,0) [0|0] "" Vector__XXX
 SG_ PCS_a071_phState m71 : 16|4@1+ (1,0) [0|0] "" Vector__XXX
 SG_ PCS_a072_task1Stopped m72 : 16|1@1+ (1,0) [0|0] "" Vector__XXX
 SG_ PCS_a073_inputL1NVrms m73 : 16|9@1+ (1,0) [0|0] "" Vector__XXX
 SG_ PCS_a074_dcdcLvBusV m74 : 16|10@1+ (0.0390625,0) [0|0] "" Vector__XXX
 SG_ PCS_a075_dcdcLvBusV m75 : 16|10@1+ (0.0390625,0) [0|0] "" Vector__XXX
 SG_ PCS_a076_pcsControlRequest m76 : 16|2@1+ (1,0) [0|0] "" Vector__XXX
 SG_ PCS_a078_phaTemperature m78 : 16|8@1- (1,40) [0|0] "" Vector__XXX
 SG_ PCS_a079_eepromOperation m79 : 16|4@1+ (1,0) [0|0] "" Vector__XXX
 SG_ PCS_a080_phADamaged m80 : 16|1@1+ (1,0) [0|0] "" Vector__XXX
 SG_ PCS_a081_dcdcLvBusV m81 : 16|10@1+ (0.0390625,0) [0|0] "" Vector__XXX
 SG_ PCS_a082_dcdcLvBusV m82 : 16|10@1+ (0.0390625,0) [0|0] "" Vector__XXX
 SG_ PCS_a083_logId m83 : 16|4@1+ (1,0) [0|0] "" Vector__XXX
 SG_ PCS_a084_dcdcSubState m84 : 16|5@1+ (1,0) [0|0] "" Vector__XXX
 SG_ PCS_a085_dcdcHalfPeriodUs m85 : 16|16@1+ (0.005,0) [0|0] "" Vector__XXX
 SG_ PCS_a086_dcdcTemperature m86 : 16|12@1- (0.1,0) [0|0] "" Vector__XXX
 SG_ PCS_a087_recordID m87 : 16|8@1+ (1,0) [0|0] "" Vector__XXX
 SG_ PCS_a088_gridConfig m88 : 16|4@1+ (1,0) [0|0] "" Vector__XXX
 SG_ PCS_a089_hvSlewRate m89 : 16|8@1- (2,0) [0|0] "" Vector__XXX
 SG_ PCS_a090_vRmsL1N m90 : 16|9@1+ (1,0) [0|0] "" Vector__XXX
 SG_ PCS_a091_intBusTarget m91 : 16|9@1+ (1,0) [0|0] "" Vector__XXX
 SG_ PCS_a092_pfcIrmsPhA m92 : 16|7@1+ (0.2,0) [0|0] "" Vector__XXX
 SG_ PCS_a093_powerRail5VN m93 : 16|10@1+ (0.01,0) [0|0] "" Vector__XXX
 SG_ PCS_a094_malfunctionCode m94 : 16|2@1+ (1,0) [0|0] "" Vector__XXX
 SG_ PCS_a095_powerRail5VN m95 : 16|10@1+ (0.01,0) [0|0] "" Vector__XXX
 SG_ PCS_a096_gridConfig m96 : 16|4@1+ (1,0) [0|0] "" Vector__XXX
 SG_ PCS_a097_phADamaged m97 : 16|1@1+ (1,0) [0|0] "" Vector__XXX
 SG_ PCS_a098_gridConfig m98 : 16|4@1+ (1,0) [0|0] "" Vector__XXX
 SG_ PCS_a099_gridConfig m99 : 16|4@1+ (1,0) [0|0] "" Vector__XXX
 SG_ PCS_a100_inputVrms m100 : 16|9@1+ (1,0) [0|0] "" Vector__XXX
 SG_ PCS_a101_phPllFreq m101 : 16|12@1+ (0.01,40) [0|0] "" Vector__XXX
 SG_ PCS_a102_pcsControlRequest m102 : 16|2@1+ (1,0) [0|0] "" Vector__XXX
 SG_ PCS_a103_lvBusVoltMin m103 : 16|8@1+ (0.1,0) [0|0] "" Vector__XXX
 SG_ PCS_a104_ambientTemperature m104 : 16|11@1- (0.1,40) [0|0] "" Vector__XXX
 SG_ PCS_a105_vRmsL1N m105 : 16|9@1+ (1,0) [0|0] "" Vector__XXX
 SG_ PCS_a107_VC_pcsInterface m107 : 16|1@1+ (1,0) [0|0] "" Vector__XXX
 SG_ PCS_a108_installedInAWrongPlatform m108 : 16|1@1+ (1,0) [0|0] "" Vector__XXX
 SG_ PCS_a109_inputL2NVrms m109 : 16|9@1+ (1,0) [0|0] "" Vector__XXX
 SG_ PCS_a016_phBVoltSrcMissingDetected m16 : 17|1@1+ (1,0) [0|0] "" Vector__XXX
 SG_ PCS_a020_chargeEnableCan m20 : 17|1@1+ (1,0) [0|0] "" Vector__XXX
 SG_ PCS_a022_BMS_chargeStatus m22 : 17|1@1+ (1,0) [0|0] "" Vector__XXX
 SG_ PCS_a023_CP_status m23 : 17|1@1+ (1,0) [0|0] "" Vector__XXX
 SG_ PCS_a024_VCFRONT_vehicleStatus m24 : 17|1@1+ (1,0) [0|0] "" Vector__XXX
 SG_ PCS_a026_CPU2_watchdog_alarmed m26 : 17|1@1+ (1,0) [0|0] "" Vector__XXX
 SG_ PCS_a039_SDModuleClockFault_LV m39 : 17|1@1+ (1,0) [0|0] "" Vector__XXX
 SG_ PCS_a042_dcdcEnableCan m42 : 17|1@1+ (1,0) [0|0] "" Vector__XXX
 SG_ PCS_a047_cpu2BootLoaderCrcMismatch m47 : 17|1@1+ (1,0) [0|0] "" Vector__XXX
 SG_ PCS_a048_4bitsData1 m48 : 17|4@1+ (1,0) [0|0] "" Vector__XXX
 SG_ PCS_a072_task2Stopped m72 : 17|1@1+ (1,0) [0|0] "" Vector__XXX
 SG_ PCS_a080_phBDamaged m80 : 17|1@1+ (1,0) [0|0] "" Vector__XXX
 SG_ PCS_a097_phBDamaged m97 : 17|1@1+ (1,0) [0|0] "" Vector__XXX
 SG_ PCS_a016_phCVoltSrcMissingDetected m16 : 18|1@1+ (1,0) [0|0] "" Vector__XXX
 SG_ PCS_a024_VCFRONT_systemStatus m24 : 18|1@1+ (1,0) [0|0] "" Vector__XXX
 SG_ PCS_a026_NMIFlagRegisters m26 : 18|11@1+ (1,0) [0|0] "" Vector__XXX
 SG_ PCS_a044_shortTime_us m44 : 18|10@1+ (0.03128054740957967,0) [0|0] "" Vector__XXX
 SG_ PCS_a076_dcdcSubState m76 : 18|5@1+ (1,0) [0|0] "" Vector__XXX
 SG_ PCS_a080_phCDamaged m80 : 18|1@1+ (1,0) [0|0] "" Vector__XXX
 SG_ PCS_a097_phCDamaged m97 : 18|1@1+ (1,0) [0|0] "" Vector__XXX
 SG_ PCS_a102_NMIFlagRegisters m102 : 18|11@1+ (1,0) [0|0] "" Vector__XXX
 SG_ PCS_a024_VCFRONT_coolant m24 : 19|1@1+ (1,0) [0|0] "" Vector__XXX
 SG_ PCS_a080_phANVRAMStoredState m80 : 19|3@1+ (1,0) [0|0] "" Vector__XXX
 SG_ PCS_a097_phANVRAMStoredState m97 : 19|3@1+ (1,0) [0|0] "" Vector__XXX
 SG_ PCS_a006_intBusPrechargeTarget m6 : 20|9@1+ (1,0) [0|0] "" Vector__XXX
 SG_ PCS_a008_phaseTemperature m8 : 20|11@1- (0.1,40) [0|0] "" Vector__XXX
 SG_ PCS_a009_pfcCurrentRms m9 : 20|9@1+ (0.1,0) [0|0] "" Vector__XXX
 SG_ PCS_a010_pfcCurrentRms m10 : 20|9@1+ (0.1,0) [0|0] "" Vector__XXX
 SG_ PCS_a011_llcCurrent m11 : 20|8@1+ (0.1,0) [0|0] "" Vector__XXX
 SG_ PCS_a012_llcFrequency m12 : 20|8@1+ (1,50) [0|0] "" Vector__XXX
 SG_ PCS_a013_intBusPrechargeTarget m13 : 20|9@1+ (1,0) [0|0] "" Vector__XXX
 SG_ PCS_a024_VCFRONT_vehNm m24 : 20|1@1+ (1,0) [0|0] "" Vector__XXX
 SG_ PCS_a025_bootromStatus m25 : 20|4@1+ (1,0) [0|0] "" Vector__XXX
 SG_ PCS_a038_dcdcSubState m38 : 20|5@1+ (1,0) [0|0] "" Vector__XXX
 SG_ PCS_a051_pfcCurrentRms m51 : 20|9@1+ (0.1,0) [0|0] "" Vector__XXX
 SG_ PCS_a069_inputIDelta m69 : 20|10@1+ (0.1,0) [0|0] "" Vector__XXX
 SG_ PCS_a070_inputVDelta m70 : 20|10@1+ (0.1,0) [0|0] "" Vector__XXX
 SG_ PCS_a071_inputVrms m71 : 20|10@1+ (0.5,0) [0|0] "" Vector__XXX
 SG_ PCS_a079_eepromOperationRegion m79 : 20|2@1+ (1,0) [0|0] "" Vector__XXX
 SG_ PCS_a088_phAFrequency m88 : 20|12@1+ (0.01,40) [0|0] "" Vector__XXX
 SG_ PCS_a096_phAFrequency m96 : 20|12@1+ (0.01,40) [0|0] "" Vector__XXX
 SG_ PCS_a098_phAFrequency m98 : 20|12@1+ (0.01,40) [0|0] "" Vector__XXX
 SG_ PCS_a099_phAFrequency m99 : 20|12@1+ (0.01,40) [0|0] "" Vector__XXX
 SG_ PCS_a024_VC_pcsManagement m24 : 21|1@1+ (1,0) [0|0] "" Vector__XXX
 SG_ PCS_a024_VCFRONT_LVPowerState m24 : 22|1@1+ (1,0) [0|0] "" Vector__XXX
 SG_ PCS_a007_phBTemperature m7 : 23|7@1+ (1,0) [0|0] "" Vector__XXX
 SG_ PCS_a076_dcdcEnableLine m76 : 23|1@1+ (1,0) [0|0] "" Vector__XXX
 SG_ PCS_a092_pfcIrmsPhB m92 : 23|7@1+ (0.2,0) [0|0] "" Vector__XXX
 SG_ PCS_a001_llcCurrent m1 : 24|8@1+ (0.1,0) [0|0] "" Vector__XXX
 SG_ PCS_a005_outputVOvThreshold m5 : 24|8@1+ (2,0) [0|0] "" Vector__XXX
 SG_ PCS_a019_utilityPowerAvailable m19 : 24|8@1+ (0.1,0) [0|0] "" Vector__XXX
 SG_ PCS_a025_bootloaderStatus m25 : 24|4@1+ (1,0) [0|0] "" Vector__XXX
 SG_ PCS_a027_chgPhBTemp m27 : 24|8@1- (1,40) [0|0] "" Vector__XXX
 SG_ PCS_a030_canID m30 : 24|16@1+ (1,0) [0|0] "" Vector__XXX
 SG_ PCS_a040_dcdcLvVoltage m40 : 24|8@1+ (0.1,0) [0|0] "" Vector__XXX
 SG_ PCS_a047_calculatedBootloaderCrc m47 : 24|32@1+ (1,0) [0|0] "" Vector__XXX
 SG_ PCS_a048_4bitsData2 m48 : 24|4@1+ (1,0) [0|0] "" Vector__XXX
 SG_ PCS_a061_chgInputVdcOffset_L2N m61 : 24|8@1+ (1,0) [0|0] "" Vector__XXX
 SG_ PCS_a076_dcdcPwmEnableDeassertedCount m76 : 24|8@1+ (1,0) [0|0] "" Vector__XXX
 SG_ PCS_a078_phbTemperature m78 : 24|8@1- (1,40) [0|0] "" Vector__XXX
 SG_ PCS_a079_recordID m79 : 24|8@1+ (1,0) [0|0] "" Vector__XXX
 SG_ PCS_a080_phBNVRAMStoredState m80 : 24|3@1+ (1,0) [0|0] "" Vector__XXX
 SG_ PCS_a084_dcdcLvBusV m84 : 24|8@1+ (0.15625,0) [0|0] "" Vector__XXX
 SG_ PCS_a087_recordStatus m87 : 24|16@1+ (1,0) [0|0] "" Vector__XXX
 SG_ PCS_a089_avgSlewRate m89 : 24|8@1- (2,0) [0|0] "" Vector__XXX
 SG_ PCS_a097_phBNVRAMStoredState m97 : 24|3@1+ (1,0) [0|0] "" Vector__XXX
 SG_ PCS_a103_lvBusVoltMax m103 : 24|8@1+ (0.1,0) [0|0] "" Vector__XXX
 SG_ PCS_a018_PhaseDiff_L2N_L3N m18 : 25|9@1+ (1,-1) [0|0] "" Vector__XXX
 SG_ PCS_a032_phBTransientRetryCount m32 : 25|9@1+ (0.1,0) [0|0] "" Vector__XXX
 SG_ PCS_a038_dcdcLvBusV m38 : 25|8@1+ (0.15625,0) [0|0] "" Vector__XXX
 SG_ PCS_a053_inputIrms m53 : 25|10@1+ (0.1,0) [0|0] "" Vector__XXX
 SG_ PCS_a054_inputIrms m54 : 25|10@1+ (0.1,0) [0|0] "" Vector__XXX
 SG_ PCS_a073_inputL2NVrms m73 : 25|9@1+ (1,0) [0|0] "" Vector__XXX
 SG_ PCS_a090_vRmsL2N m90 : 25|9@1+ (1,0) [0|0] "" Vector__XXX
 SG_ PCS_a091_intBusMaxRippleLevel m91 : 25|9@1+ (0.1,0) [0|0] "" Vector__XXX
 SG_ PCS_a100_phIntBusVolt m100 : 25|9@1+ (1,0) [0|0] "" Vector__XXX
 SG_ PCS_a105_vRmsL2N m105 : 25|9@1+ (1,0) [0|0] "" Vector__XXX
 SG_ PCS_a109_inputL3NVrms m109 : 25|9@1+ (1,0) [0|0] "" Vector__XXX
 SG_ PCS_a028_outputVUvThreshold m28 : 26|10@1+ (0.5,0) [0|0] "" Vector__XXX
 SG_ PCS_a043_dcdcHvBusV m43 : 26|12@1+ (0.146484375,0) [0|0] "" Vector__XXX
 SG_ PCS_a045_hvBusEstimated_R_kOhm m45 : 26|10@1+ (0.04887585532746823,0) [0|0] "" Vector__XXX
 SG_ PCS_a046_hvBusEstimated_R_kOhm m46 : 26|10@1+ (0.04887585532746823,0) [0|0] "" Vector__XXX
 SG_ PCS_a057_inputFrequency m57 : 26|9@1+ (0.1,40) [0|0] "" Vector__XXX
 SG_ PCS_a058_inputFrequency m58 : 26|12@1+ (0.01,40) [0|0] "" Vector__XXX
 SG_ PCS_a059_inputOvRmsThreshold m59 : 26|10@1+ (0.5,0) [0|0] "" Vector__XXX
 SG_ PCS_a060_inputOvPeakThreshold m60 : 26|10@1+ (0.5,0) [0|0] "" Vector__XXX
 SG_ PCS_a063_hvpHvLinkVoltage m63 : 26|11@1- (1,0) [0|0] "" Vector__XXX
 SG_ PCS_a065_inputFrequency m65 : 26|9@1+ (0.1,40) [0|0] "" Vector__XXX
 SG_ PCS_a074_dcdcHvBusV m74 : 26|12@1+ (0.146484375,0) [0|0] "" Vector__XXX
 SG_ PCS_a075_dcdcHvBusV m75 : 26|12@1+ (0.146484375,0) [0|0] "" Vector__XXX
 SG_ PCS_a081_dcdcHvBusV m81 : 26|12@1+ (0.146484375,0) [0|0] "" Vector__XXX
 SG_ PCS_a082_dcdcHvBusV m82 : 26|12@1+ (0.146484375,0) [0|0] "" Vector__XXX
 SG_ PCS_a093_powerRail3V3 m93 : 26|10@1+ (0.01,0) [0|0] "" Vector__XXX
 SG_ PCS_a095_pcsControlRequest m95 : 26|2@1+ (1,0) [0|0] "" Vector__XXX
 SG_ PCS_a014_phbTemperature m14 : 27|11@1- (0.1,40) [0|0] "" Vector__XXX
 SG_ PCS_a080_phCNVRAMStoredState m80 : 27|3@1+ (1,0) [0|0] "" Vector__XXX
 SG_ PCS_a097_phCNVRAMStoredState m97 : 27|3@1+ (1,0) [0|0] "" Vector__XXX
 SG_ PCS_a011_llcCurrentTarget m11 : 28|8@1+ (0.1,0) [0|0] "" Vector__XXX
 SG_ PCS_a012_llcCurrent m12 : 28|8@1+ (0.1,0) [0|0] "" Vector__XXX
 SG_ PCS_a025_bootromRequestFlag m25 : 28|1@1+ (1,0) [0|0] "" Vector__XXX
 SG_ PCS_a044_dcdcLvBusCurrent_A m44 : 28|10@1+ (0.39100684261974583,0) [0|0] "" Vector__XXX
 SG_ PCS_a086_pcsAmbientTemperature m86 : 28|12@1- (0.1,0) [0|0] "" Vector__XXX
 SG_ PCS_a101_phMachineModelFreq m101 : 28|12@1+ (0.01,40) [0|0] "" Vector__XXX
 SG_ PCS_a006_intBusV m6 : 29|9@1+ (1,0) [0|0] "" Vector__XXX
 SG_ PCS_a013_intBusV m13 : 29|9@1+ (1,0) [0|0] "" Vector__XXX
 SG_ PCS_a025_bootromRequestStatusFlag m25 : 29|1@1+ (1,0) [0|0] "" Vector__XXX
 SG_ PCS_a026_systemResetRegisters m26 : 29|11@1+ (1,0) [0|0] "" Vector__XXX
 SG_ PCS_a051_llcCurrent m51 : 29|8@1+ (0.1,0) [0|0] "" Vector__XXX
 SG_ PCS_a067_vcfrontPcsEFuseV m67 : 29|10@1+ (0.1,0) [0|0] "" Vector__XXX
 SG_ PCS_a102_systemResetRegisters m102 : 29|11@1+ (1,0) [0|0] "" Vector__XXX
 SG_ PCS_a007_phCTemperature m7 : 30|7@1+ (1,0) [0|0] "" Vector__XXX
 SG_ PCS_a069_inputVrms m69 : 30|10@1+ (0.5,0) [0|0] "" Vector__XXX
 SG_ PCS_a070_inputVrms m70 : 30|10@1+ (0.5,0) [0|0] "" Vector__XXX
 SG_ PCS_a071_intBusV m71 : 30|9@1+ (1,0) [0|0] "" Vector__XXX
 SG_ PCS_a092_pfcIrmsPhC m92 : 30|7@1+ (0.2,0) [0|0] "" Vector__XXX
 SG_ PCS_a008_inputVrms m8 : 31|9@1+ (1,0) [0|0] "" Vector__XXX
 SG_ PCS_a001_phState m1 : 32|4@1+ (1,0) [0|0] "" Vector__XXX
 SG_ PCS_a009_pfcCurrentTarget m9 : 32|12@1+ (0.01,0) [0|0] "" Vector__XXX
 SG_ PCS_a010_llcCurrent m10 : 32|8@1+ (0.1,0) [0|0] "" Vector__XXX
 SG_ PCS_a019_userPowerRequest m19 : 32|8@1+ (0.1,0) [0|0] "" Vector__XXX
 SG_ PCS_a025_cpu2StoredAppCrcLsb16 m25 : 32|16@1+ (1,0) [0|0] "" Vector__XXX
 SG_ PCS_a027_chgPhCTemp m27 : 32|8@1- (1,40) [0|0] "" Vector__XXX
 SG_ PCS_a029_chgInputPower m29 : 32|8@1+ (0.1,0) [0|0] "" Vector__XXX
 SG_ PCS_a040_dcdcLvOutputCurrent m40 : 32|13@1- (0.1,0) [0|0] "" Vector__XXX
 SG_ PCS_a048_8bitsData1 m48 : 32|8@1+ (1,0) [0|0] "" Vector__XXX
 SG_ PCS_a061_chgInputVdcOffset_L3N m61 : 32|8@1+ (1,0) [0|0] "" Vector__XXX
 SG_ PCS_a066_hvpHvLinkVoltage m66 : 32|11@1- (1,0) [0|0] "" Vector__XXX
 SG_ PCS_a068_dcdcTankVoltOffset m68 : 32|16@1- (0.001525878906,0) [0|0] "" Vector__XXX
 SG_ PCS_a078_phcTemperature m78 : 32|8@1- (1,40) [0|0] "" Vector__XXX
 SG_ PCS_a079_eepromOperationErrorCode m79 : 32|5@1+ (1,0) [0|0] "" Vector__XXX
 SG_ PCS_a084_dcdcHvBusV m84 : 32|10@1+ (0.5859375,0) [0|0] "" Vector__XXX
 SG_ PCS_a088_phBFrequency m88 : 32|12@1+ (0.01,40) [0|0] "" Vector__XXX
 SG_ PCS_a089_G m89 : 32|4@1+ (0.2,0) [0|0] "" Vector__XXX
 SG_ PCS_a096_phBFrequency m96 : 32|12@1+ (0.01,40) [0|0] "" Vector__XXX
 SG_ PCS_a098_phBFrequency m98 : 32|12@1+ (0.01,40) [0|0] "" Vector__XXX
 SG_ PCS_a099_phBFrequency m99 : 32|12@1+ (0.01,40) [0|0] "" Vector__XXX
 SG_ PCS_a103_hvBusVoltMax m103 : 32|9@1+ (1,0) [0|0] "" Vector__XXX
 SG_ PCS_a038_dcdcHvBusV m38 : 33|10@1+ (0.5859375,0) [0|0] "" Vector__XXX
 SG_ PCS_a018_PhaseDiff_L1N_L3N m18 : 34|9@1+ (1,-1) [0|0] "" Vector__XXX
 SG_ PCS_a032_phCTransientRetryCount m32 : 34|9@1+ (0.1,0) [0|0] "" Vector__XXX
 SG_ PCS_a073_inputL3NVrms m73 : 34|9@1+ (1,0) [0|0] "" Vector__XXX
 SG_ PCS_a090_vRmsL3N m90 : 34|9@1+ (1,0) [0|0] "" Vector__XXX
 SG_ PCS_a091_pfcCurrentIrms m91 : 34|8@1+ (0.1,0) [0|0] "" Vector__XXX
 SG_ PCS_a100_phKwhCounter m100 : 34|13@1+ (1,0) [0|0] "" Vector__XXX
 SG_ PCS_a105_vRmsL3N m105 : 34|9@1+ (1,0) [0|0] "" Vector__XXX
 SG_ PCS_a001_pfcCurrentRms m1 : 36|9@1+ (0.1,0) [0|0] "" Vector__XXX
 SG_ PCS_a011_llcFrequency m11 : 36|8@1+ (1,50) [0|0] "" Vector__XXX
 SG_ PCS_a012_outOfIBandDuration m12 : 36|7@1+ (0.05,0) [0|0] "" Vector__XXX
 SG_ PCS_a089_HV_busV m89 : 36|9@1+ (0.8203125,0) [0|0] "" Vector__XXX
 SG_ PCS_a007_ambientTemperature m7 : 37|7@1+ (1,0) [0|0] "" Vector__XXX
 SG_ PCS_a051_intBusV m51 : 37|9@1+ (1,0) [0|0] "" Vector__XXX
 SG_ PCS_a092_chgTempPhA m92 : 37|8@1- (1,40) [0|0] "" Vector__XXX
 SG_ PCS_a006_inputVrms m6 : 38|9@1+ (1,0) [0|0] "" Vector__XXX
 SG_ PCS_a013_inputVrms m13 : 38|9@1+ (1,0) [0|0] "" Vector__XXX
 SG_ PCS_a044_vTankPeak_abs_V m44 : 38|10@1+ (1,0) [0|0] "" Vector__XXX
 SG_ PCS_a071_inputFrequency m71 : 39|9@1+ (0.1,40) [0|0] "" Vector__XXX
 SG_ PCS_a008_inputIrms m8 : 40|10@1+ (0.1,0) [0|0] "" Vector__XXX
 SG_ PCS_a010_intBusV m10 : 40|9@1+ (1,0) [0|0] "" Vector__XXX
 SG_ PCS_a014_phcTemperature m14 : 40|11@1- (0.1,40) [0|0] "" Vector__XXX
 SG_ PCS_a019_phAFaulted m19 : 40|1@1+ (1,0) [0|0] "" Vector__XXX
 SG_ PCS_a027_chgPhANoFlowBucket m27 : 40|5@1+ (0.2,0) [0|0] "" Vector__XXX
 SG_ PCS_a029_bmsPowerCommand m29 : 40|8@1+ (0.1,0) [0|0] "" Vector__XXX
 SG_ PCS_a043_hvPrechargeTargetV m43 : 40|12@1+ (0.146484375,0) [0|0] "" Vector__XXX
 SG_ PCS_a048_8bitsData2 m48 : 40|8@1+ (1,0) [0|0] "" Vector__XXX
 SG_ PCS_a053_acChargeCurrentLimit m53 : 40|7@1+ (1,0) [0|0] "" Vector__XXX
 SG_ PCS_a054_acChargeCurrentLimit m54 : 40|7@1+ (1,0) [0|0] "" Vector__XXX
 SG_ PCS_a061_chgInputVdcOffset_L1L2 m61 : 40|8@1+ (1,0) [0|0] "" Vector__XXX
 SG_ PCS_a067_vcfrontVcrightVoltage m67 : 40|10@1+ (0.1,0) [0|0] "" Vector__XXX
 SG_ PCS_a069_intBusV m69 : 40|9@1+ (1,0) [0|0] "" Vector__XXX
 SG_ PCS_a070_intBusV m70 : 40|9@1+ (1,0) [0|0] "" Vector__XXX
 SG_ PCS_a075_dcdcSubState m75 : 40|5@1+ (1,0) [0|0] "" Vector__XXX
 SG_ PCS_a078_dcdcTemperature m78 : 40|8@1- (1,40) [0|0] "" Vector__XXX
 SG_ PCS_a079_operationAddress m79 : 40|16@1+ (1,0) [0|0] "" Vector__XXX
 SG_ PCS_a081_faultedSubstate m81 : 40|5@1+ (1,0) [0|0] "" Vector__XXX
 SG_ PCS_a082_faultedSubstate m82 : 40|5@1+ (1,0) [0|0] "" Vector__XXX
 SG_ PCS_a086_vcfrontPTCoolantTemp m86 : 40|12@1- (0.1,0) [0|0] "" Vector__XXX
 SG_ PCS_a093_powerRail1V5 m93 : 40|8@1+ (0.01,0) [0|0] "" Vector__XXX
 SG_ PCS_a101_phMachineModelCurrent m101 : 40|9@1+ (0.1,0) [0|0] "" Vector__XXX
 SG_ PCS_a102_dcdcEnableLine m102 : 40|1@1+ (1,0) [0|0] "" Vector__XXX
 SG_ PCS_a019_phBFaulted m19 : 41|1@1+ (1,0) [0|0] "" Vector__XXX
 SG_ PCS_a103_hvPrechargeTargetV m103 : 41|9@1+ (1,0) [0|0] "" Vector__XXX
 SG_ PCS_a019_phCFaulted m19 : 42|1@1+ (1,0) [0|0] "" Vector__XXX
 SG_ PCS_a084_dcdcHvBusVDropRate m84 : 42|12@1+ (1,0) [0|0] "" Vector__XXX
 SG_ PCS_a091_phaseInputVrms m91 : 42|9@1+ (1,0) [0|0] "" Vector__XXX
 SG_ PCS_a012_batteryV m12 : 43|9@1+ (1,0) [0|0] "" Vector__XXX
 SG_ PCS_a018_PhaseDiff_L1L2_L1N m18 : 43|9@1+ (1,-1) [0|0] "" Vector__XXX
 SG_ PCS_a032_phAFaulted m32 : 43|1@1+ (1,0) [0|0] "" Vector__XXX
 SG_ PCS_a038_dcdcLvBusCurrent_A m38 : 43|10@1- (0.78125,0) [0|0] "" Vector__XXX
 SG_ PCS_a073_inputNGVrms m73 : 43|9@1+ (1,0) [0|0] "" Vector__XXX
 SG_ PCS_a090_vRmsL1L2 m90 : 43|9@1+ (1,0) [0|0] "" Vector__XXX
 SG_ PCS_a105_vRmsL1L2 m105 : 43|9@1+ (1,0) [0|0] "" Vector__XXX
 SG_ PCS_a007_inputVrms m7 : 44|9@1+ (1,0) [0|0] "" Vector__XXX
 SG_ PCS_a009_llcCurrent m9 : 44|8@1+ (0.1,0) [0|0] "" Vector__XXX
 SG_ PCS_a011_intBusV m11 : 44|8@1+ (2,0) [0|0] "" Vector__XXX
 SG_ PCS_a032_phBFaulted m32 : 44|1@1+ (1,0) [0|0] "" Vector__XXX
 SG_ PCS_a088_phCFrequency m88 : 44|12@1+ (0.01,40) [0|0] "" Vector__XXX
 SG_ PCS_a096_phCFrequency m96 : 44|12@1+ (0.01,40) [0|0] "" Vector__XXX
 SG_ PCS_a098_phCFrequency m98 : 44|12@1+ (0.01,40) [0|0] "" Vector__XXX
 SG_ PCS_a099_phCFrequency m99 : 44|12@1+ (0.01,40) [0|0] "" Vector__XXX
 SG_ PCS_a001_intBusV m1 : 45|9@1+ (1,0) [0|0] "" Vector__XXX
 SG_ PCS_a032_phCFaulted m32 : 45|1@1+ (1,0) [0|0] "" Vector__XXX
 SG_ PCS_a089_PhaseShift m89 : 45|5@1+ (0.5,0) [0|0] "" Vector__XXX
 SG_ PCS_a092_chgTempPhB m92 : 45|8@1- (1,40) [0|0] "" Vector__XXX
 SG_ PCS_a051_intBusVTarget m51 : 46|9@1+ (1,0) [0|0] "" Vector__XXX
 SG_ PCS_a006_inputVToIntBusDeltaMax m6 : 47|7@1+ (1,0) [0|0] "" Vector__XXX
 SG_ PCS_a013_inputVToIntBusDeltaMax m13 : 47|7@1+ (1,0) [0|0] "" Vector__XXX
 SG_ PCS_a053_startingInputVrms m53 : 47|9@1+ (1,0) [0|0] "" Vector__XXX
 SG_ PCS_a054_startingInputVrms m54 : 47|9@1+ (1,0) [0|0] "" Vector__XXX
 SG_ PCS_a027_chgPhBNoFlowBucket m27 : 48|5@1+ (0.2,0) [0|0] "" Vector__XXX
 SG_ PCS_a029_phaseConfig m29 : 48|4@1+ (1,0) [0|0] "" Vector__XXX
 SG_ PCS_a048_16bitsData1 m48 : 48|8@1+ (1,0) [0|0] "" Vector__XXX
 SG_ PCS_a061_PllSourceIrrational_L1N m61 : 48|1@1+ (1,0) [0|0] "" Vector__XXX
 SG_ PCS_a071_llcFrequency m71 : 48|8@1+ (1,50) [0|0] "" Vector__XXX
 SG_ PCS_a078_ptCoolantTemp m78 : 48|8@1- (1,40) [0|0] "" Vector__XXX
 SG_ PCS_a093_powerRail1V2 m93 : 48|8@1+ (0.01,0) [0|0] "" Vector__XXX
 SG_ PCS_a100_phKwhCounterDeltaFromMax m100 : 48|13@1+ (1,0) [0|0] "" Vector__XXX
 SG_ PCS_a010_intBusVTarget m10 : 49|9@1+ (1,0) [0|0] "" Vector__XXX
 SG_ PCS_a061_PllSourceIrrational_L2N m61 : 49|1@1+ (1,0) [0|0] "" Vector__XXX
 SG_ PCS_a069_inputFrequency m69 : 49|9@1+ (0.1,40) [0|0] "" Vector__XXX
 SG_ PCS_a070_inputFrequency m70 : 49|9@1+ (0.1,40) [0|0] "" Vector__XXX
 SG_ PCS_a101_phInputVoltage m101 : 49|9@1+ (1,0) [0|0] "" Vector__XXX
 SG_ PCS_a061_PllSourceIrrational_L3N m61 : 50|1@1+ (1,0) [0|0] "" Vector__XXX
 SG_ PCS_a089_Freq m89 : 50|9@1+ (1,0) [0|0] "" Vector__XXX
 SG_ PCS_a103_faultPresent m103 : 50|1@1+ (1,0) [0|0] "" Vector__XXX
 SG_ PCS_a061_PllSourceIrrational_L1L2 m61 : 51|1@1+ (1,0) [0|0] "" Vector__XXX
 SG_ PCS_a091_phaseTemp m91 : 51|8@1- (1,0) [0|0] "" Vector__XXX
 SG_ PCS_a103_lvBusCurrentMax m103 : 51|8@1+ (1,0) [0|0] "" Vector__XXX
 SG_ PCS_a009_intBusV m9 : 52|8@1+ (2,0) [0|0] "" Vector__XXX
 SG_ PCS_a011_outputV m11 : 52|8@1+ (2,0) [0|0] "" Vector__XXX
 SG_ PCS_a012_transientRetryCount m12 : 52|9@1+ (0.1,0) [0|0] "" Vector__XXX
 SG_ PCS_a018_L1NLocked m18 : 52|1@1+ (1,0) [0|0] "" Vector__XXX
 SG_ PCS_a073_phaseConfig m73 : 52|4@1+ (1,0) [0|0] "" Vector__XXX
 SG_ PCS_a090_evaluatedGridConfig m90 : 52|4@1+ (1,0) [0|0] "" Vector__XXX
 SG_ PCS_a105_L1NStatus m105 : 52|2@1+ (1,0) [0|0] "" Vector__XXX
 SG_ PCS_a007_inputIrms m7 : 53|8@1+ (0.5,0) [0|0] "" Vector__XXX
 SG_ PCS_a018_L2NLocked m18 : 53|1@1+ (1,0) [0|0] "" Vector__XXX
 SG_ PCS_a038_dcdcPwmEnableDeassertedCount m38 : 53|7@1+ (1,0) [0|0] "" Vector__XXX
 SG_ PCS_a092_chgTempPhC m92 : 53|8@1- (1,40) [0|0] "" Vector__XXX
 SG_ PCS_a006_inputFrequency m6 : 54|7@1+ (1,40) [0|0] "" Vector__XXX
 SG_ PCS_a013_inputFrequency m13 : 54|7@1+ (1,40) [0|0] "" Vector__XXX
 SG_ PCS_a018_L3NLocked m18 : 54|1@1+ (1,0) [0|0] "" Vector__XXX
 SG_ PCS_a105_L2NStatus m105 : 54|2@1+ (1,0) [0|0] "" Vector__XXX
 SG_ PCS_a018_L1L2Locked m18 : 55|1@1+ (1,0) [0|0] "" Vector__XXX
 SG_ PCS_a051_intBusStaticRipple m51 : 55|6@1+ (1,0) [0|0] "" Vector__XXX
 SG_ PCS_a027_chgPhCNoFlowBucket m27 : 56|5@1+ (0.2,0) [0|0] "" Vector__XXX
 SG_ PCS_a053_phaseConfig m53 : 56|4@1+ (1,0) [0|0] "" Vector__XXX
 SG_ PCS_a054_phaseConfig m54 : 56|4@1+ (1,0) [0|0] "" Vector__XXX
 SG_ PCS_a073_cpType m73 : 56|2@1+ (1,0) [0|0] "" Vector__XXX
 SG_ PCS_a079_eepromErrorCount m79 : 56|5@1+ (1,0) [0|0] "" Vector__XXX
 SG_ PCS_a090_phASourceMissing m90 : 56|1@1+ (1,0) [0|0] "" Vector__XXX
 SG_ PCS_a093_irrational1V2Rail m93 : 56|1@1+ (1,0) [0|0] "" Vector__XXX
 SG_ PCS_a105_L3NStatus m105 : 56|2@1+ (1,0) [0|0] "" Vector__XXX
 SG_ PCS_a090_phBSourceMissing m90 : 57|1@1+ (1,0) [0|0] "" Vector__XXX
 SG_ PCS_a093_irrational1V5Rail m93 : 57|1@1+ (1,0) [0|0] "" Vector__XXX
 SG_ PCS_a090_phCSourceMissing m90 : 58|1@1+ (1,0) [0|0] "" Vector__XXX
 SG_ PCS_a093_irrational3V3Rail m93 : 58|1@1+ (1,0) [0|0] "" Vector__XXX
 SG_ PCS_a101_retryCount m101 : 58|2@1+ (1,0) [0|0] "" Vector__XXX
 SG_ PCS_a105_L1L2Status m105 : 58|2@1+ (1,0) [0|0] "" Vector__XXX
 SG_ PCS_a089_fastDischargeMode m89 : 59|1@1+ (1,0) [0|0] "" Vector__XXX
 SG_ PCS_a093_irrational5VNRail m93 : 59|1@1+ (1,0) [0|0] "" Vector__XXX
 SG_ PCS_a103_usingReducedMinPrechargePowerLimit m103 : 59|1@1+ (1,0) [0|0] "" Vector__XXX
 SG_ PCS_a038_dcdcPwmEnableLine m38 : 60|1@1+ (1,0) [0|0] "" Vector__XXX
 SG_ PCS_a089_slowDischargeMode m89 : 60|1@1+ (1,0) [0|0] "" Vector__XXX
 SG_ PCS_alertSource : 61|3@1+ (1,0) [0|0] "" Vector__XXX

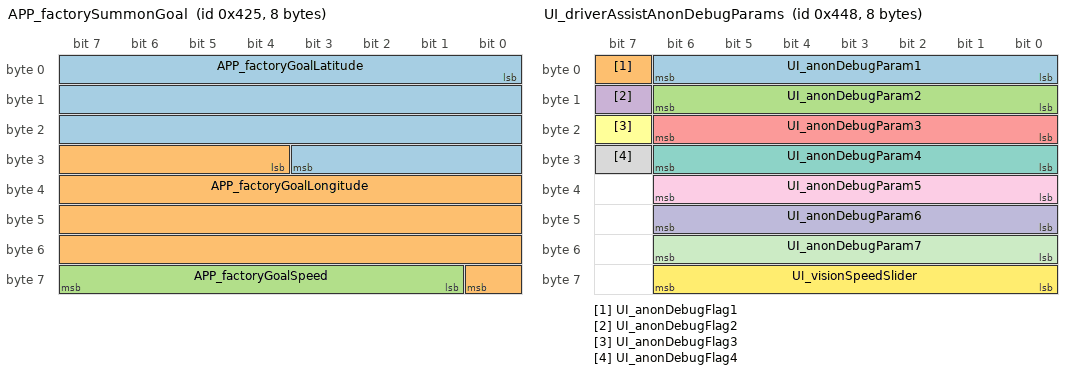
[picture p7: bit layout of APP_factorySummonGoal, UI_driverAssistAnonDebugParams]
BO_ 1061 APP_factorySummonGoal: 8 Vector__XXX
 SG_ APP_factoryGoalLatitude : 0|28@1- (1e-06,0) [0|0] "" Vector__XXX
 SG_ APP_factoryGoalLongitude : 28|29@1- (1e-06,0) [0|0] "" Vector__XXX
 SG_ APP_factoryGoalSpeed : 57|7@1+ (1,0) [0|0] "" Vector__XXX

BO_ 1064 UI_telemetryControl: 8 Vector__XXX
 SG_ UI_TCR_enable : 0|1@1+ (1,0) [0|0] "" Vector__XXX
 SG_ UI_TCR_moveStateStanding : 1|1@1+ (1,0) [0|0] "" Vector__XXX
 SG_ UI_TCR_moveStateStopped : 2|1@1+ (1,0) [0|0] "" Vector__XXX
 SG_ UI_TCR_moveStateMoving : 3|1@1+ (1,0) [0|0] "" Vector__XXX
 SG_ UI_TCR_moveStateIndeterm : 4|1@1+ (1,0) [0|0] "" Vector__XXX
 SG_ UI_TCR_classConstElem : 5|1@1+ (1,0) [0|0] "" Vector__XXX
 SG_ UI_TCR_classMovingPed : 6|1@1+ (1,0) [0|0] "" Vector__XXX
 SG_ UI_TCR_classMovingTwoWheel : 7|1@1+ (1,0) [0|0] "" Vector__XXX
 SG_ UI_TCR_classMovingFourWheel : 8|1@1+ (1,0) [0|0] "" Vector__XXX
 SG_ UI_TCR_classUnknown : 9|1@1+ (1,0) [0|0] "" Vector__XXX
 SG_ UI_TCR_downSampleFactor : 10|4@1+ (1,0) [0|0] "" Vector__XXX
 SG_ UI_TCR_wExist : 24|5@1+ (1,0) [0|0] "" Vector__XXX
 SG_ UI_TCR_vehSpeed : 32|8@1+ (1,0) [0|0] "" Vector__XXX
 SG_ UI_TCR_minRCS : 40|8@1+ (0.25,-14) [0|0] "" Vector__XXX
 SG_ UI_TCR_maxDy : 48|5@1+ (0.5,0) [0|0] "" Vector__XXX
 SG_ UI_TCR_maxObjects : 56|5@1+ (1,0) [0|0] "" Vector__XXX
 SG_ UI_TCR_maxRoadClass : 61|3@1+ (1,0) [0|0] "" Vector__XXX

BO_ 1065 APP_warningMatrix2: 8 Vector__XXX
 SG_ APP_w129_mainCamExtNotCal : 0|1@1+ (1,0) [0|0] "" Vector__XXX
 SG_ APP_w130_narrowCamExtNotCal : 1|1@1+ (1,0) [0|0] "" Vector__XXX
 SG_ APP_w131_mainCamCalSaved : 2|1@1+ (1,0) [0|0] "" Vector__XXX
 SG_ APP_w132_narrowCamCalSaved : 3|1@1+ (1,0) [0|0] "" Vector__XXX
 SG_ APP_w133_mainCamInitFault : 4|1@1+ (1,0) [0|0] "" Vector__XXX
 SG_ APP_w134_narrowCamInitFault : 5|1@1+ (1,0) [0|0] "" Vector__XXX
 SG_ APP_w135_fisheyeCamInitFault : 6|1@1+ (1,0) [0|0] "" Vector__XXX
 SG_ APP_w136_lPillarCamInitFault : 7|1@1+ (1,0) [0|0] "" Vector__XXX
 SG_ APP_w137_rPillarCamInitFault : 8|1@1+ (1,0) [0|0] "" Vector__XXX
 SG_ APP_w138_lRepeatCamInitFault : 9|1@1+ (1,0) [0|0] "" Vector__XXX
 SG_ APP_w139_rRepeatCamInitFault : 10|1@1+ (1,0) [0|0] "" Vector__XXX
 SG_ APP_w140_backupCamInitFault : 11|1@1+ (1,0) [0|0] "" Vector__XXX
 SG_ APP_w141_ECU_Thermal_Issue : 12|1@1+ (1,0) [0|0] "" Vector__XXX
 SG_ APP_w142_fwdCamPitchProblem : 13|1@1+ (1,0) [0|0] "" Vector__XXX
 SG_ APP_w143_IDF_event : 14|1@1+ (1,0) [0|0] "" Vector__XXX
 SG_ APP_w144_fanctrldError : 15|1@1+ (1,0) [0|0] "" Vector__XXX
 SG_ APP_w145_camSelfCalIssue : 16|1@1+ (1,0) [0|0] "" Vector__XXX
 SG_ APP_w146_telemetryProblem : 17|1@1+ (1,0) [0|0] "" Vector__XXX
 SG_ APP_w147_selfieCamInitFault : 18|1@1+ (1,0) [0|0] "" Vector__XXX
 SG_ APP_w148_overlayActive : 19|1@1+ (1,0) [0|0] "" Vector__XXX
 SG_ APP_w149_diskFull : 20|1@1+ (1,0) [0|0] "" Vector__XXX
 SG_ APP_w150_diMiaPartyBus : 21|1@1+ (1,0) [0|0] "" Vector__XXX
 SG_ APP_w151_epasMiaPartyBus : 22|1@1+ (1,0) [0|0] "" Vector__XXX
 SG_ APP_w152_espMiaPartyBus : 23|1@1+ (1,0) [0|0] "" Vector__XXX
 SG_ APP_w153_rcmMiaPartyBus : 24|1@1+ (1,0) [0|0] "" Vector__XXX
 SG_ APP_w154_vcleftMiaPartyBus : 25|1@1+ (1,0) [0|0] "" Vector__XXX
 SG_ APP_w155_vcrightMiaPartyBus : 26|1@1+ (1,0) [0|0] "" Vector__XXX
 SG_ APP_w156_epblMiaVehBus : 27|1@1+ (1,0) [0|0] "" Vector__XXX
 SG_ APP_w157_sccmMiaVehBus : 28|1@1+ (1,0) [0|0] "" Vector__XXX
 SG_ APP_w158_vcfrontMiaVehBus : 29|1@1+ (1,0) [0|0] "" Vector__XXX
 SG_ APP_w159_vcleftMiaVehBus : 30|1@1+ (1,0) [0|0] "" Vector__XXX
 SG_ APP_w160_vcrightMiaVehBus : 31|1@1+ (1,0) [0|0] "" Vector__XXX
 SG_ APP_w161_backupCameraUnavailable : 32|1@1+ (1,0) [0|0] "" Vector__XXX
 SG_ APP_w162_mainCameraTypeError : 33|1@1+ (1,0) [0|0] "" Vector__XXX
 SG_ APP_w163_narrowCameraTypeError : 34|1@1+ (1,0) [0|0] "" Vector__XXX
 SG_ APP_w164_fisheyeCameraTypeError : 35|1@1+ (1,0) [0|0] "" Vector__XXX
 SG_ APP_w165_lPillarCameraTypeError : 36|1@1+ (1,0) [0|0] "" Vector__XXX
 SG_ APP_w166_rPillarCameraTypeError : 37|1@1+ (1,0) [0|0] "" Vector__XXX
 SG_ APP_w167_lRepeatCameraTypeError : 38|1@1+ (1,0) [0|0] "" Vector__XXX
 SG_ APP_w168_rRepeatCameraTypeError : 39|1@1+ (1,0) [0|0] "" Vector__XXX
 SG_ APP_w169_backupCameraTypeError : 40|1@1+ (1,0) [0|0] "" Vector__XXX
 SG_ APP_w170_selfieCameraTypeError : 41|1@1+ (1,0) [0|0] "" Vector__XXX
 SG_ APP_w171_appHighCoolantFlowReq : 42|1@1+ (1,0) [0|0] "" Vector__XXX
 SG_ APP_w172_fisheyeCamExtNotCal : 43|1@1+ (1,0) [0|0] "" Vector__XXX
 SG_ APP_w173_lPillarCamExtNotCal : 44|1@1+ (1,0) [0|0] "" Vector__XXX
 SG_ APP_w174_rPillarCamExtNotCal : 45|1@1+ (1,0) [0|0] "" Vector__XXX
 SG_ APP_w175_lRepeatCamExtNotCal : 46|1@1+ (1,0) [0|0] "" Vector__XXX
 SG_ APP_w176_rRepeatCamExtNotCal : 47|1@1+ (1,0) [0|0] "" Vector__XXX
 SG_ APP_w177_fisheyeCamCalSaved : 48|1@1+ (1,0) [0|0] "" Vector__XXX
 SG_ APP_w178_lPillarCamCalSaved : 49|1@1+ (1,0) [0|0] "" Vector__XXX
 SG_ APP_w179_rPillarCamCalSaved : 50|1@1+ (1,0) [0|0] "" Vector__XXX
 SG_ APP_w180_lRepeatCamCalSaved : 51|1@1+ (1,0) [0|0] "" Vector__XXX
 SG_ APP_w181_rRepeatCamCalSaved : 52|1@1+ (1,0) [0|0] "" Vector__XXX
 SG_ APP_w182_mainCameraStreamExit : 53|1@1+ (1,0) [0|0] "" Vector__XXX
 SG_ APP_w183_narrowCameraStreamExit : 54|1@1+ (1,0) [0|0] "" Vector__XXX
 SG_ APP_w184_fisheyeCameraStreamExit : 55|1@1+ (1,0) [0|0] "" Vector__XXX
 SG_ APP_w185_lPillarCameraStreamExit : 56|1@1+ (1,0) [0|0] "" Vector__XXX
 SG_ APP_w186_rPillarCameraStreamExit : 57|1@1+ (1,0) [0|0] "" Vector__XXX
 SG_ APP_w187_lRepeatCameraStreamExit : 58|1@1+ (1,0) [0|0] "" Vector__XXX
 SG_ APP_w188_rRepeatCameraStreamExit : 59|1@1+ (1,0) [0|0] "" Vector__XXX
 SG_ APP_w189_backupCameraStreamExit : 60|1@1+ (1,0) [0|0] "" Vector__XXX
 SG_ APP_w190_selfieCameraStreamExit : 61|1@1+ (1,0) [0|0] "" Vector__XXX
 SG_ APP_w191_autopilotAborting : 62|1@1+ (1,0) [0|0] "" Vector__XXX
 SG_ APP_w192_emergencySpeakerFail : 63|1@1+ (1,0) [0|0] "" Vector__XXX

BO_ 1081 APP_warningMatrix3: 8 Vector__XXX
 SG_ APP_w193_camWindshieldUnclean : 0|1@1+ (1,0) [0|0] "" Vector__XXX
 SG_ APP_w194_accDriverResumeRqrd : 1|1@1+ (1,0) [0|0] "" Vector__XXX
 SG_ APP_w195_scwUnavailable : 2|1@1+ (1,0) [0|0] "" Vector__XXX
 SG_ APP_w196_stopSignWarning : 3|1@1+ (1,0) [0|0] "" Vector__XXX
 SG_ APP_w197_redLightWarning : 4|1@1+ (1,0) [0|0] "" Vector__XXX
 SG_ APP_w198_tsrUnavailable : 5|1@1+ (1,0) [0|0] "" Vector__XXX
 SG_ APP_w199_apcAbort : 6|1@1+ (1,0) [0|0] "" Vector__XXX
 SG_ APP_w200_lcSlowdown : 7|1@1+ (1,0) [0|0] "" Vector__XXX
 SG_ APP_w201_lcAborting : 8|1@1+ (1,0) [0|0] "" Vector__XXX
 SG_ APP_w202_scwNoisyEnvironment : 9|1@1+ (1,0) [0|0] "" Vector__XXX
 SG_ APP_w203_apcActivation : 10|1@1+ (1,0) [0|0] "" Vector__XXX
 SG_ APP_w204_apcFinalFront : 11|1@1+ (1,0) [0|0] "" Vector__XXX
 SG_ APP_w205_apcFinalRear : 12|1@1+ (1,0) [0|0] "" Vector__XXX
 SG_ APP_w206_autosteerNotEnabled : 13|1@1+ (1,0) [0|0] "" Vector__XXX
 SG_ APP_w207_autosteerUnavailable : 14|1@1+ (1,0) [0|0] "" Vector__XXX
 SG_ APP_w208_rackDetected : 15|1@1+ (1,0) [0|0] "" Vector__XXX
 SG_ APP_w209_autoSummonRequest : 16|1@1+ (1,0) [0|0] "" Vector__XXX
 SG_ APP_w210_camObstrcted : 17|1@1+ (1,0) [0|0] "" Vector__XXX
 SG_ APP_w211_accNoSeatBelt : 18|1@1+ (1,0) [0|0] "" Vector__XXX
 SG_ APP_w212_lcUnavailableStrikeOut : 19|1@1+ (1,0) [0|0] "" Vector__XXX
 SG_ APP_w213_autosteerStruckOut : 20|1@1+ (1,0) [0|0] "" Vector__XXX
 SG_ APP_w214_driverNotIntracting : 21|1@1+ (1,0) [0|0] "" Vector__XXX
 SG_ APP_w215_contDriverNotIntracting : 22|1@1+ (1,0) [0|0] "" Vector__XXX
 SG_ APP_w216_driverOverriding : 23|1@1+ (1,0) [0|0] "" Vector__XXX
 SG_ APP_w217_lcUnavailableSpeeding : 24|1@1+ (1,0) [0|0] "" Vector__XXX
 SG_ APP_w218_lcSpeedExceededLimit : 25|1@1+ (1,0) [0|0] "" Vector__XXX
 SG_ APP_w219_lcTempUnavailableSpeed : 26|1@1+ (1,0) [0|0] "" Vector__XXX
 SG_ APP_w220_lcTempUnavailableRoad : 27|1@1+ (1,0) [0|0] "" Vector__XXX
 SG_ APP_w221_accRadarBlind : 28|1@1+ (1,0) [0|0] "" Vector__XXX
 SG_ APP_w222_accCameraBlind : 29|1@1+ (1,0) [0|0] "" Vector__XXX
 SG_ APP_w223_accObjectInPath : 30|1@1+ (1,0) [0|0] "" Vector__XXX
 SG_ APP_w224_accCameraCalibration : 31|1@1+ (1,0) [0|0] "" Vector__XXX
 SG_ APP_w225_lcDegradedVisSpeedLmt : 32|1@1+ (1,0) [0|0] "" Vector__XXX
 SG_ APP_w226_lcCamCalNeededSpeedLmt : 33|1@1+ (1,0) [0|0] "" Vector__XXX
 SG_ APP_w227_virtualWallBlocked : 34|1@1+ (1,0) [0|0] "" Vector__XXX
 SG_ APP_w228_DEPRECATED : 35|1@1+ (1,0) [0|0] "" Vector__XXX
 SG_ APP_w229_alcUltrasoundDamaged : 36|1@1+ (1,0) [0|0] "" Vector__XXX
 SG_ APP_w230_alcUltrasoundBlocked : 37|1@1+ (1,0) [0|0] "" Vector__XXX
 SG_ APP_w231_idfEvent : 38|1@1+ (1,0) [0|0] "" Vector__XXX
 SG_ APP_w232_laneChangeRequested : 39|1@1+ (1,0) [0|0] "" Vector__XXX
 SG_ APP_w234_activeSafetyTelemetry : 41|1@1+ (1,0) [0|0] "" Vector__XXX

BO_ 1082 DAS_warningMatrix3: 8 Vector__XXX
 SG_ DAS_w193_camWindshieldUnclean : 0|1@1+ (1,0) [0|0] "" Vector__XXX
 SG_ DAS_w194_accDriverResumeRqrd : 1|1@1+ (1,0) [0|0] "" Vector__XXX
 SG_ DAS_w195_scwUnavailable : 2|1@1+ (1,0) [0|0] "" Vector__XXX
 SG_ DAS_w196_stopSignWarning : 3|1@1+ (1,0) [0|0] "" Vector__XXX
 SG_ DAS_w197_redLightWarning : 4|1@1+ (1,0) [0|0] "" Vector__XXX
 SG_ DAS_w198_tsrUnavailable : 5|1@1+ (1,0) [0|0] "" Vector__XXX
 SG_ DAS_w199_apcAbort : 6|1@1+ (1,0) [0|0] "" Vector__XXX
 SG_ DAS_w200_lcSlowdown : 7|1@1+ (1,0) [0|0] "" Vector__XXX
 SG_ DAS_w201_lcAborting : 8|1@1+ (1,0) [0|0] "" Vector__XXX
 SG_ DAS_w202_scwNoisyEnvironment : 9|1@1+ (1,0) [0|0] "" Vector__XXX
 SG_ DAS_w203_apcActivation : 10|1@1+ (1,0) [0|0] "" Vector__XXX
 SG_ DAS_w204_apcFinalFront : 11|1@1+ (1,0) [0|0] "" Vector__XXX
 SG_ DAS_w205_apcFinalRear : 12|1@1+ (1,0) [0|0] "" Vector__XXX
 SG_ DAS_w206_autosteerNotEnabled : 13|1@1+ (1,0) [0|0] "" Vector__XXX
 SG_ DAS_w207_autosteerUnavailable : 14|1@1+ (1,0) [0|0] "" Vector__XXX
 SG_ DAS_w208_rackDetected : 15|1@1+ (1,0) [0|0] "" Vector__XXX
 SG_ DAS_w209_autoSummonRequest : 16|1@1+ (1,0) [0|0] "" Vector__XXX
 SG_ DAS_w210_camObstrcted : 17|1@1+ (1,0) [0|0] "" Vector__XXX
 SG_ DAS_w211_accNoSeatBelt : 18|1@1+ (1,0) [0|0] "" Vector__XXX
 SG_ DAS_w212_lcUnavailableStrikeOut : 19|1@1+ (1,0) [0|0] "" Vector__XXX
 SG_ DAS_w213_autosteerStruckOut : 20|1@1+ (1,0) [0|0] "" Vector__XXX
 SG_ DAS_w214_driverNotIntracting : 21|1@1+ (1,0) [0|0] "" Vector__XXX
 SG_ DAS_w215_contDriverNotIntracting : 22|1@1+ (1,0) [0|0] "" Vector__XXX
 SG_ DAS_w216_driverOverriding : 23|1@1+ (1,0) [0|0] "" Vector__XXX
 SG_ DAS_w217_lcUnavailableSpeeding : 24|1@1+ (1,0) [0|0] "" Vector__XXX
 SG_ DAS_w218_lcSpeedExceededLimit : 25|1@1+ (1,0) [0|0] "" Vector__XXX
 SG_ DAS_w219_lcTempUnavailableSpeed : 26|1@1+ (1,0) [0|0] "" Vector__XXX
 SG_ DAS_w220_lcTempUnavailableRoad : 27|1@1+ (1,0) [0|0] "" Vector__XXX
 SG_ DAS_w221_accRadarBlind : 28|1@1+ (1,0) [0|0] "" Vector__XXX
 SG_ DAS_w222_accCameraBlind : 29|1@1+ (1,0) [0|0] "" Vector__XXX
 SG_ DAS_w223_accObjectInPath : 30|1@1+ (1,0) [0|0] "" Vector__XXX
 SG_ DAS_w224_accCameraCalibration : 31|1@1+ (1,0) [0|0] "" Vector__XXX
 SG_ DAS_w225_lcDegradedVisSpeedLmt : 32|1@1+ (1,0) [0|0] "" Vector__XXX
 SG_ DAS_w226_lcCamCalNeededSpeedLmt : 33|1@1+ (1,0) [0|0] "" Vector__XXX
 SG_ DAS_w227_virtualWallBlocked : 34|1@1+ (1,0) [0|0] "" Vector__XXX
 SG_ DAS_w228_DEPRECATED : 35|1@1+ (1,0) [0|0] "" Vector__XXX
 SG_ DAS_w229_alcUltrasoundDamaged : 36|1@1+ (1,0) [0|0] "" Vector__XXX
 SG_ DAS_w230_alcUltrasoundBlocked : 37|1@1+ (1,0) [0|0] "" Vector__XXX
 SG_ DAS_w231_idfEvent : 38|1@1+ (1,0) [0|0] "" Vector__XXX
 SG_ DAS_w232_laneChangeRequested : 39|1@1+ (1,0) [0|0] "" Vector__XXX

BO_ 1096 UI_driverAssistAnonDebugParams: 8 Vector__XXX
 SG_ UI_anonDebugParam1 : 0|7@1+ (1,0) [0|0] "" Vector__XXX
 SG_ UI_anonDebugFlag1 : 7|1@1+ (1,0) [0|0] "" Vector__XXX
 SG_ UI_anonDebugParam2 : 8|7@1+ (1,0) [0|0] "" Vector__XXX
 SG_ UI_anonDebugFlag2 : 15|1@1+ (1,0) [0|0] "" Vector__XXX
 SG_ UI_anonDebugParam3 : 16|7@1+ (1,0) [0|0] "" Vector__XXX
 SG_ UI_anonDebugFlag3 : 23|1@1+ (1,0) [0|0] "" Vector__XXX
 SG_ UI_anonDebugParam4 : 24|7@1+ (1,0) [0|0] "" Vector__XXX
 SG_ UI_anonDebugFlag4 : 31|1@1+ (1,0) [0|0] "" Vector__XXX
 SG_ UI_anonDebugParam5 : 32|7@1+ (1,0) [0|0] "" Vector__XXX
 SG_ UI_anonDebugParam6 : 40|7@1+ (1,0) [0|0] "" Vector__XXX
 SG_ UI_anonDebugParam7 : 48|7@1+ (1,0) [0|0] "" Vector__XXX
 SG_ UI_visionSpeedSlider : 56|7@1+ (1,0) [0|0] "" Vector__XXX

BO_ 1097 APP_warningMatrix4: 8 Vector__XXX
 SG_ APP_w257_brakeJerkEvent : 0|1@1+ (1,0) [0|0] "" Vector__XXX
 SG_ APP_w258_aebEvent : 1|1@1+ (1,0) [0|0] "" Vector__XXX
 SG_ APP_w259_aebOverrideEvent : 2|1@1+ (1,0) [0|0] "" Vector__XXX
 SG_ APP_w260_collisionWarningEvent : 3|1@1+ (1,0) [0|0] "" Vector__XXX
 SG_ APP_w261_pcieHardwareErrors : 4|1@1+ (1,0) [0|0] "" Vector__XXX
 SG_ APP_w262_apeCalibMode : 5|1@1+ (1,0) [0|0] "" Vector__XXX
 SG_ APP_w263_lssAbort : 6|1@1+ (1,0) [0|0] "" Vector__XXX
 SG_ APP_w264_lssFault : 7|1@1+ (1,0) [0|0] "" Vector__XXX
 SG_ APP_w265_drvOnNavUnavailable : 8|1@1+ (1,0) [0|0] "" Vector__XXX
 SG_ APP_w266_visionScheduleFallback : 9|1@1+ (1,0) [0|0] "" Vector__XXX
 SG_ APP_w267_benchtopEcu : 10|1@1+ (1,0) [0|0] "" Vector__XXX
 SG_ APP_w268_backupCamExtNotCal : 11|1@1+ (1,0) [0|0] "" Vector__XXX
 SG_ APP_w269_autopilotLimited : 12|1@1+ (1,0) [0|0] "" Vector__XXX
 SG_ APP_w270_blindspotRestricted : 13|1@1+ (1,0) [0|0] "" Vector__XXX
 SG_ APP_w271_laneChangeAborted : 14|1@1+ (1,0) [0|0] "" Vector__XXX
 SG_ APP_w272_laneChangeUnavailable : 15|1@1+ (1,0) [0|0] "" Vector__XXX
 SG_ APP_w273_lssEvent : 16|1@1+ (1,0) [0|0] "" Vector__XXX
 SG_ APP_w274_mainCameraStreamErr : 17|1@1+ (1,0) [0|0] "" Vector__XXX
 SG_ APP_w275_narrowCameraStreamErr : 18|1@1+ (1,0) [0|0] "" Vector__XXX
 SG_ APP_w276_fisheyeCameraStreamErr : 19|1@1+ (1,0) [0|0] "" Vector__XXX
 SG_ APP_w277_lPillarCameraStreamErr : 20|1@1+ (1,0) [0|0] "" Vector__XXX
 SG_ APP_w278_rPillarCameraStreamErr : 21|1@1+ (1,0) [0|0] "" Vector__XXX
 SG_ APP_w279_lRepeatCameraStreamErr : 22|1@1+ (1,0) [0|0] "" Vector__XXX
 SG_ APP_w280_rRepeatCameraStreamErr : 23|1@1+ (1,0) [0|0] "" Vector__XXX
 SG_ APP_w281_backupCameraStreamErr : 24|1@1+ (1,0) [0|0] "" Vector__XXX
 SG_ APP_w282_selfieCameraStreamErr : 25|1@1+ (1,0) [0|0] "" Vector__XXX
 SG_ APP_w283_enhancedSummonAbort : 26|1@1+ (1,0) [0|0] "" Vector__XXX
 SG_ APP_w284_gpsAntennaDisconnected : 27|1@1+ (1,0) [0|0] "" Vector__XXX
 SG_ APP_w285_gpsFaultReset : 28|1@1+ (1,0) [0|0] "" Vector__XXX
 SG_ APP_w286_gpsComIssue : 29|1@1+ (1,0) [0|0] "" Vector__XXX
 SG_ APP_w287_gpsFusionStatus : 30|1@1+ (1,0) [0|0] "" Vector__XXX
 SG_ APP_w288_trafficLightWarning : 31|1@1+ (1,0) [0|0] "" Vector__XXX
 SG_ APP_w289_dramCorrEccErrors : 32|1@1+ (1,0) [0|0] "" Vector__XXX
 SG_ APP_w290_dramUncorrEccErrors : 33|1@1+ (1,0) [0|0] "" Vector__XXX
 SG_ APP_w291_stopSignWarning : 34|1@1+ (1,0) [0|0] "" Vector__XXX
 SG_ APP_w293_mainCameraSyncFailed : 36|1@1+ (1,0) [0|0] "" Vector__XXX
 SG_ APP_w294_narrowCameraSyncFailed : 37|1@1+ (1,0) [0|0] "" Vector__XXX
 SG_ APP_w295_fisheyeCameraSyncFailed : 38|1@1+ (1,0) [0|0] "" Vector__XXX
 SG_ APP_w296_lPillarCameraSyncFailed : 39|1@1+ (1,0) [0|0] "" Vector__XXX
 SG_ APP_w297_rPillarCameraSyncFailed : 40|1@1+ (1,0) [0|0] "" Vector__XXX
 SG_ APP_w298_lRepeatCameraSyncFailed : 41|1@1+ (1,0) [0|0] "" Vector__XXX
 SG_ APP_w299_rRepeatCameraSyncFailed : 42|1@1+ (1,0) [0|0] "" Vector__XXX
 SG_ APP_w300_backupCameraSyncFailed : 43|1@1+ (1,0) [0|0] "" Vector__XXX
 SG_ APP_w301_selfieCameraSyncFailed : 44|1@1+ (1,0) [0|0] "" Vector__XXX
 SG_ APP_w302_vcfrontMiaPartyBus : 45|1@1+ (1,0) [0|0] "" Vector__XXX
 SG_ APP_w303_imuIrational : 46|1@1+ (1,0) [0|0] "" Vector__XXX
 SG_ APP_w304_lssCamBlockedStatus : 47|1@1+ (1,0) [0|0] "" Vector__XXX
 SG_ APP_w305_lssCamStreamExit : 48|1@1+ (1,0) [0|0] "" Vector__XXX
 SG_ APP_w306_lssUltrasonicsBlocked : 49|1@1+ (1,0) [0|0] "" Vector__XXX
 SG_ APP_w307_lssTurnSignalFault : 50|1@1+ (1,0) [0|0] "" Vector__XXX
 SG_ APP_w308_iboosterMia : 51|1@1+ (1,0) [0|0] "" Vector__XXX
 SG_ APP_w309_selfieDisabledOnCar : 52|1@1+ (1,0) [0|0] "" Vector__XXX
 SG_ APP_w310_eth0FrameErrors : 53|1@1+ (1,0) [0|0] "" Vector__XXX
 SG_ APP_w311_eth1FrameErrors : 54|1@1+ (1,0) [0|0] "" Vector__XXX
 SG_ APP_w312_mainCamTypeMismatch : 55|1@1+ (1,0) [0|0] "" Vector__XXX
 SG_ APP_w313_narrowCamTypeMismatch : 56|1@1+ (1,0) [0|0] "" Vector__XXX
 SG_ APP_w314_fisheyeCamTypeMismatch : 57|1@1+ (1,0) [0|0] "" Vector__XXX
 SG_ APP_w315_lPillarCamTypeMismatch : 58|1@1+ (1,0) [0|0] "" Vector__XXX
 SG_ APP_w316_rPillarCamTypeMismatch : 59|1@1+ (1,0) [0|0] "" Vector__XXX
 SG_ APP_w317_lRepeatCamTypeMismatch : 60|1@1+ (1,0) [0|0] "" Vector__XXX
 SG_ APP_w318_rRepeatCamTypeMismatch : 61|1@1+ (1,0) [0|0] "" Vector__XXX
 SG_ APP_w319_backupCamTypeMismatch : 62|1@1+ (1,0) [0|0] "" Vector__XXX
 SG_ APP_w320_selfieCamTypeMismatch : 63|1@1+ (1,0) [0|0] "" Vector__XXX

BO_ 1113 APS_warningMatrix2: 8 Vector__XXX
 SG_ APS_w129_ECU_Power_Issue : 0|1@1+ (1,0) [0|0] "" Vector__XXX
 SG_ APS_w130_ECU_Thermal_Issue : 1|1@1+ (1,0) [0|0] "" Vector__XXX
 SG_ APS_w131_trap_exception : 2|1@1+ (1,0) [0|0] "" Vector__XXX
 SG_ APS_w132_appVersionMismatch : 3|1@1+ (1,0) [0|0] "" Vector__XXX
 SG_ APS_w133_ETHSwitchError : 4|1@1+ (1,0) [0|0] "" Vector__XXX
 SG_ APS_w134_appMia : 5|1@1+ (1,0) [0|0] "" Vector__XXX
 SG_ APS_w135_appCritical : 6|1@1+ (1,0) [0|0] "" Vector__XXX
 SG_ APS_w136_gpsDisabled : 7|1@1+ (1,0) [0|0] "" Vector__XXX
 SG_ APS_w137_gpsFaultReset : 8|1@1+ (1,0) [0|0] "" Vector__XXX
 SG_ APS_w138_gpsComIssue : 9|1@1+ (1,0) [0|0] "" Vector__XXX
 SG_ APS_w139_udpBufferOverflow : 10|1@1+ (1,0) [0|0] "" Vector__XXX
 SG_ APS_w140_vcfrontMiaVehicleBus : 11|1@1+ (1,0) [0|0] "" Vector__XXX
 SG_ APS_w141_rcmMiaPartyBus : 12|1@1+ (1,0) [0|0] "" Vector__XXX
 SG_ APS_w142_diMiaPartyBus : 13|1@1+ (1,0) [0|0] "" Vector__XXX
 SG_ APS_w143_espMiaPartyBus : 14|1@1+ (1,0) [0|0] "" Vector__XXX
 SG_ APS_w144_vcleftMiaPartyBus : 15|1@1+ (1,0) [0|0] "" Vector__XXX
 SG_ APS_w145_vcrightMiaPartyBus : 16|1@1+ (1,0) [0|0] "" Vector__XXX
 SG_ APS_w146_epas3pMiaPartyBus : 17|1@1+ (1,0) [0|0] "" Vector__XXX
 SG_ APS_w147_vcleftMiaVehBus : 18|1@1+ (1,0) [0|0] "" Vector__XXX
 SG_ APS_w148_vcrightMiaVehBus : 19|1@1+ (1,0) [0|0] "" Vector__XXX
 SG_ APS_w149_epblMiaVehBus : 20|1@1+ (1,0) [0|0] "" Vector__XXX
 SG_ APS_w150_sccmMiaVehBus : 21|1@1+ (1,0) [0|0] "" Vector__XXX
 SG_ APS_w151_apRecovered : 22|1@1+ (1,0) [0|0] "" Vector__XXX
 SG_ APS_w152_gpsFusionStatus : 23|1@1+ (1,0) [0|0] "" Vector__XXX
 SG_ APS_w153_eacInhibit : 24|1@1+ (1,0) [0|0] "" Vector__XXX
 SG_ APS_w155_ethLwipError : 26|1@1+ (1,0) [0|0] "" Vector__XXX
 SG_ APS_w156_lwipAssert : 27|1@1+ (1,0) [0|0] "" Vector__XXX
 SG_ APS_w157_autopilotReboot : 28|1@1+ (1,0) [0|0] "" Vector__XXX
 SG_ APS_w158_apbMia : 29|1@1+ (1,0) [0|0] "" Vector__XXX
 SG_ APS_w159_apbCritical : 30|1@1+ (1,0) [0|0] "" Vector__XXX
 SG_ APS_w160_apbVersionMismatch : 31|1@1+ (1,0) [0|0] "" Vector__XXX
 SG_ APS_w161_gpsAntennaDisconnected : 32|1@1+ (1,0) [0|0] "" Vector__XXX
 SG_ APS_w162_TurboA_DisRegPgoodErr : 33|1@1+ (1,0) [0|0] "" Vector__XXX
 SG_ APS_w163_TurboA_DisRegNFault : 34|1@1+ (1,0) [0|0] "" Vector__XXX
 SG_ APS_w164_TurboA_12VFuseFault : 35|1@1+ (1,0) [0|0] "" Vector__XXX
 SG_ APS_w165_TurboA_Temp_NOS : 36|1@1+ (1,0) [0|0] "" Vector__XXX
 SG_ APS_w166_TurboA_SMSLockStepErr : 37|1@1+ (1,0) [0|0] "" Vector__XXX
 SG_ APS_w167_TurboA_TMU_Throttle : 38|1@1+ (1,0) [0|0] "" Vector__XXX
 SG_ APS_w168_TurboA_SMS_WDOG : 39|1@1+ (1,0) [0|0] "" Vector__XXX
 SG_ APS_w169_TurboA_SCS_LKUP : 40|1@1+ (1,0) [0|0] "" Vector__XXX
 SG_ APS_w170_TurboA_A72_watchdog : 41|1@1+ (1,0) [0|0] "" Vector__XXX
 SG_ APS_w171_TurboA_SMS_taskUtilErr : 42|1@1+ (1,0) [0|0] "" Vector__XXX
 SG_ APS_w172_apFeaturesUnavailable : 43|1@1+ (1,0) [0|0] "" Vector__XXX
 SG_ APS_w178_TurboB_DisRegPgoodErr : 49|1@1+ (1,0) [0|0] "" Vector__XXX
 SG_ APS_w179_TurboB_DisRegNFault : 50|1@1+ (1,0) [0|0] "" Vector__XXX
 SG_ APS_w180_TurboB_12VFuseFault : 51|1@1+ (1,0) [0|0] "" Vector__XXX
 SG_ APS_w181_TurboB_Temp_NOS : 52|1@1+ (1,0) [0|0] "" Vector__XXX
 SG_ APS_w182_TurboB_SMSLockStepErr : 53|1@1+ (1,0) [0|0] "" Vector__XXX
 SG_ APS_w183_TurboB_TMU_Throttle : 54|1@1+ (1,0) [0|0] "" Vector__XXX
 SG_ APS_w184_TurboB_SMS_WDOG : 55|1@1+ (1,0) [0|0] "" Vector__XXX
 SG_ APS_w185_TurboB_SCS_LKUP : 56|1@1+ (1,0) [0|0] "" Vector__XXX
 SG_ APS_w186_TurboB_A72_watchdog : 57|1@1+ (1,0) [0|0] "" Vector__XXX
 SG_ APS_w187_TurboB_SMS_taskUtilErr : 58|1@1+ (1,0) [0|0] "" Vector__XXX
 SG_ APS_w188_otherTurboUartMIA : 59|1@1+ (1,0) [0|0] "" Vector__XXX
 SG_ APS_w189_vcfrontMiaPartyBus : 60|1@1+ (1,0) [0|0] "" Vector__XXX
 SG_ APS_w190_iboosterMia : 61|1@1+ (1,0) [0|0] "" Vector__XXX
 SG_ APS_w191_timesyncError : 62|1@1+ (1,0) [0|0] "" Vector__XXX
 SG_ APS_w192_CANFault : 63|1@1+ (1,0) [0|0] "" Vector__XXX

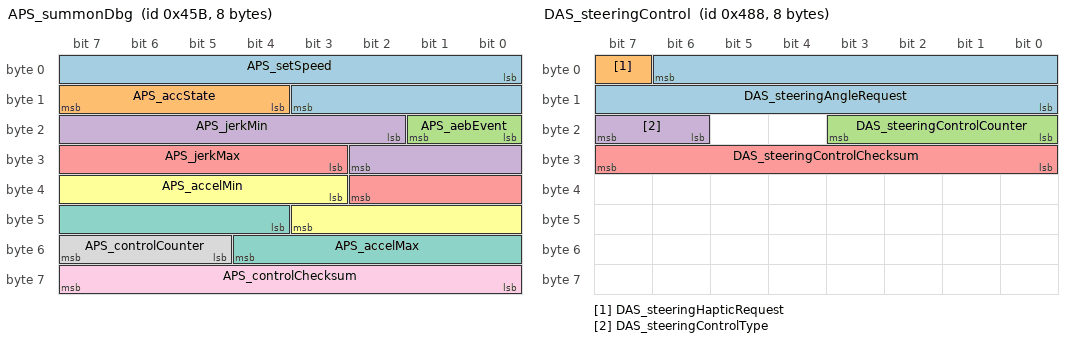
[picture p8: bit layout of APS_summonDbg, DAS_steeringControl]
BO_ 1115 APS_summonDbg: 8 Vector__XXX
 SG_ APS_setSpeed : 0|12@1+ (0.1,0) [0|0] "" Vector__XXX
 SG_ APS_accState : 12|4@1+ (1,0) [0|0] "" Vector__XXX
 SG_ APS_aebEvent : 16|2@1+ (1,0) [0|0] "" Vector__XXX
 SG_ APS_jerkMin : 18|9@1+ (0.03,-15.232) [0|0] "" Vector__XXX
 SG_ APS_jerkMax : 27|8@1+ (0.059,0) [0|0] "" Vector__XXX
 SG_ APS_accelMin : 35|9@1+ (0.04,-15) [0|0] "" Vector__XXX
 SG_ APS_accelMax : 44|9@1+ (0.04,-15) [0|0] "" Vector__XXX
 SG_ APS_controlCounter : 53|3@1+ (1,0) [0|0] "" Vector__XXX
 SG_ APS_controlChecksum : 56|8@1+ (1,0) [0|0] "" Vector__XXX

BO_ 1149 APP_warningMatrix6: 8 Vector__XXX
 SG_ APP_w385_posEngineUnhealthy : 0|1@1+ (1,0) [0|0] "" Vector__XXX
 SG_ APP_w386_radarOnlyBrakingEvent : 1|1@1+ (1,0) [0|0] "" Vector__XXX
 SG_ APP_w387_radarBlockageDetected : 2|1@1+ (1,0) [0|0] "" Vector__XXX
 SG_ APP_w388_windshieldCameraHeaterFaulted : 3|1@1+ (1,0) [0|0] "" Vector__XXX
 SG_ APP_w389_camFovResidueDetected : 4|1@1+ (1,0) [0|0] "" Vector__XXX
 SG_ APP_w390_cabinCamVisDegraded : 5|1@1+ (1,0) [0|0] "" Vector__XXX
 SG_ APP_w391_cabinCameraBlockedonAP : 6|1@1+ (1,0) [0|0] "" Vector__XXX
 SG_ APP_w392_fsdSuspended : 7|1@1+ (1,0) [0|0] "" Vector__XXX
 SG_ APP_w393_attnMntrUnavailable : 8|1@1+ (1,0) [0|0] "" Vector__XXX
 SG_ APP_w394_apImuGrossErrors : 9|1@1+ (1,0) [0|0] "" Vector__XXX
 SG_ APP_w395_cabinCameraLEDFaultSvc : 10|1@1+ (1,0) [0|0] "" Vector__XXX
 SG_ APP_w396_severeResidueDetected : 11|1@1+ (1,0) [0|0] "" Vector__XXX
 SG_ APP_w397_apFeatDisabledPermanent : 12|1@1+ (1,0) [0|0] "" Vector__XXX
 SG_ APP_w398_imuOutputUnhealthy : 13|1@1+ (1,0) [0|0] "" Vector__XXX
 SG_ APP_w399_brakeboosterMia : 14|1@1+ (1,0) [0|0] "" Vector__XXX
 SG_ APP_w400_selfieCameraFanFault : 15|1@1+ (1,0) [0|0] "" Vector__XXX
 SG_ APP_w401_leftPillarCameraHeaterFaulted : 16|1@1+ (1,0) [0|0] "" Vector__XXX
 SG_ APP_w402_rightPillarCameraHeaterFaulted : 17|1@1+ (1,0) [0|0] "" Vector__XXX
 SG_ APP_w411_backupCameraOccluded : 26|1@1+ (1,0) [0|0] "" Vector__XXX
 SG_ APP_w412_abortBackupCamOccluded : 27|1@1+ (1,0) [0|0] "" Vector__XXX
 SG_ APP_w423_cameraVisPopUpForward : 38|1@1+ (1,0) [0|0] "" Vector__XXX
 SG_ APP_w424_cameraVisPopUpLPillar : 39|1@1+ (1,0) [0|0] "" Vector__XXX
 SG_ APP_w425_cameraVisPopUpRPillar : 40|1@1+ (1,0) [0|0] "" Vector__XXX
 SG_ APP_w426_cameraVisPopUpLRepeater : 41|1@1+ (1,0) [0|0] "" Vector__XXX
 SG_ APP_w427_cameraVisPopUpRRepeater : 42|1@1+ (1,0) [0|0] "" Vector__XXX
 SG_ APP_w428_cameraVisPopUpBackup : 43|1@1+ (1,0) [0|0] "" Vector__XXX
 SG_ APP_w429_cameraVisPopUpFascia : 44|1@1+ (1,0) [0|0] "" Vector__XXX
 SG_ APP_w430_frontVisibilityDegraded_LOW : 45|1@1+ (1,0) [0|0] "" Vector__XXX
 SG_ APP_w431_frontVisibilityDegraded_MEDIUM : 46|1@1+ (1,0) [0|0] "" Vector__XXX
 SG_ APP_w432_frontVisibilityDegraded_HIGH : 47|1@1+ (1,0) [0|0] "" Vector__XXX
 SG_ APP_w433_leftRepeaterDowngradeDetected : 48|1@1+ (1,0) [0|0] "" Vector__XXX
 SG_ APP_w434_rightRepeaterDowngradeDetected : 49|1@1+ (1,0) [0|0] "" Vector__XXX
 SG_ APP_w435_repeaterAeroRibInfoMismatched : 50|1@1+ (1,0) [0|0] "" Vector__XXX
 SG_ APP_w437_missingCloudEepromData : 52|1@1+ (1,0) [0|0] "" Vector__XXX
 SG_ APP_w443_mainImagerConfigMismatch : 58|1@1+ (1,0) [0|0] "" Vector__XXX
 SG_ APP_w444_narrowImagerConfigMismatch : 59|1@1+ (1,0) [0|0] "" Vector__XXX
 SG_ APP_w445_fisheyeImagerConfigMismatch : 60|1@1+ (1,0) [0|0] "" Vector__XXX
 SG_ APP_w446_leftPillarImagerConfigMismatch : 61|1@1+ (1,0) [0|0] "" Vector__XXX
 SG_ APP_w447_rightPillarImagerConfigMismatch : 62|1@1+ (1,0) [0|0] "" Vector__XXX
 SG_ APP_w448_leftRepeaterImagerConfigMismatch : 63|1@1+ (1,0) [0|0] "" Vector__XXX

BO_ 1151 APP_warningMatrix5: 8 Vector__XXX
 SG_ APP_w321_bmsMia : 0|1@1+ (1,0) [0|0] "" Vector__XXX
 SG_ APP_w322_autoWiperWash : 1|1@1+ (1,0) [0|0] "" Vector__XXX
 SG_ APP_w323_drivableSpaceFCW : 2|1@1+ (1,0) [0|0] "" Vector__XXX
 SG_ APP_w324_adspMia : 3|1@1+ (1,0) [0|0] "" Vector__XXX
 SG_ APP_w325_watchdogReset : 4|1@1+ (1,0) [0|0] "" Vector__XXX
 SG_ APP_w326_kernelPanic : 5|1@1+ (1,0) [0|0] "" Vector__XXX
 SG_ APP_w327_vehicleConfigMismatch : 6|1@1+ (1,0) [0|0] "" Vector__XXX
 SG_ APP_w328_autoparkDegraded : 7|1@1+ (1,0) [0|0] "" Vector__XXX
 SG_ APP_w329_evasiveManeuver : 8|1@1+ (1,0) [0|0] "" Vector__XXX
 SG_ APP_w330_cabinCameraFault : 9|1@1+ (1,0) [0|0] "" Vector__XXX
 SG_ APP_w331_fsdDegradedUnavailable : 10|1@1+ (1,0) [0|0] "" Vector__XXX
 SG_ APP_w332_cameraPositionsSwapped : 11|1@1+ (1,0) [0|0] "" Vector__XXX
 SG_ APP_w333_fsdUnavailableLocation : 12|1@1+ (1,0) [0|0] "" Vector__XXX
 SG_ APP_w334_frontCameraOccluded : 13|1@1+ (1,0) [0|0] "" Vector__XXX
 SG_ APP_w335_tradfcRfSensorError : 14|1@1+ (1,0) [0|0] "" Vector__XXX
 SG_ APP_w336_tradfcLfPmicError : 15|1@1+ (1,0) [0|0] "" Vector__XXX
 SG_ APP_w337_tradfcRfPmicError : 16|1@1+ (1,0) [0|0] "" Vector__XXX
 SG_ APP_w338_tradfcLfTempError : 17|1@1+ (1,0) [0|0] "" Vector__XXX
 SG_ APP_w339_tradfcRfTempError : 18|1@1+ (1,0) [0|0] "" Vector__XXX
 SG_ APP_w340_tradfcCsiError : 19|1@1+ (1,0) [0|0] "" Vector__XXX
 SG_ APP_w341_tradfcCalibError : 20|1@1+ (1,0) [0|0] "" Vector__XXX
 SG_ APP_w342_tradfcDspHwError : 21|1@1+ (1,0) [0|0] "" Vector__XXX
 SG_ APP_w343_tradfcDspSwError : 22|1@1+ (1,0) [0|0] "" Vector__XXX
 SG_ APP_w344_tradfcDspAlgoTimeout : 23|1@1+ (1,0) [0|0] "" Vector__XXX
 SG_ APP_w345_tradfcPerfDegraded : 24|1@1+ (1,0) [0|0] "" Vector__XXX
 SG_ APP_w346_gpsSwEvent : 25|1@1+ (1,0) [0|0] "" Vector__XXX
 SG_ APP_w347_vcbattMiaVehBus : 26|1@1+ (1,0) [0|0] "" Vector__XXX
 SG_ APP_w348_cameraSwUpdateRequired : 27|1@1+ (1,0) [0|0] "" Vector__XXX
 SG_ APP_w349_cameraPersistentlyFaulted : 28|1@1+ (1,0) [0|0] "" Vector__XXX
 SG_ APP_w350_tradfcSensorMisaligned : 29|1@1+ (1,0) [0|0] "" Vector__XXX
 SG_ APP_w351_csiDevice0Down : 30|1@1+ (1,0) [0|0] "" Vector__XXX
 SG_ APP_w352_csiDevice1Down : 31|1@1+ (1,0) [0|0] "" Vector__XXX
 SG_ APP_w353_csiDevice2Down : 32|1@1+ (1,0) [0|0] "" Vector__XXX
 SG_ APP_w354_tradfcMia : 33|1@1+ (1,0) [0|0] "" Vector__XXX
 SG_ APP_w355_camQuadPowerFault : 34|1@1+ (1,0) [0|0] "" Vector__XXX
 SG_ APP_w356_driverOverriding : 35|1@1+ (1,0) [0|0] "" Vector__XXX
 SG_ APP_w357_ddawSystemFault : 36|1@1+ (1,0) [0|0] "" Vector__XXX
 SG_ APP_w358_isaSystemFault : 37|1@1+ (1,0) [0|0] "" Vector__XXX
 SG_ APP_w359_aebDegraded : 38|1@1+ (1,0) [0|0] "" Vector__XXX
 SG_ APP_w360_ApImuNoiseDetected : 39|1@1+ (1,0) [0|0] "" Vector__XXX
 SG_ APP_w361_cabinCameraLEDFault : 40|1@1+ (1,0) [0|0] "" Vector__XXX
 SG_ APP_w369_cruiseWithSingleClick : 48|1@1+ (1,0) [0|0] "" Vector__XXX
 SG_ APP_w370_accApUnavUserSettings : 49|1@1+ (1,0) [0|0] "" Vector__XXX
 SG_ APP_w371_networkLoadingIssue : 50|1@1+ (1,0) [0|0] "" Vector__XXX
 SG_ APP_w372_cabinCameraBlocked : 51|1@1+ (1,0) [0|0] "" Vector__XXX
 SG_ APP_w373_gnssUartError : 52|1@1+ (1,0) [0|0] "" Vector__XXX
 SG_ APP_w374_gnssUartDataMia : 53|1@1+ (1,0) [0|0] "" Vector__XXX
 SG_ APP_w375_gnssPpsMia : 54|1@1+ (1,0) [0|0] "" Vector__XXX
 SG_ APP_w376_wheeltickCountMia : 55|1@1+ (1,0) [0|0] "" Vector__XXX
 SG_ APP_w377_apImuMia : 56|1@1+ (1,0) [0|0] "" Vector__XXX
 SG_ APP_w378_ubloxImuMia : 57|1@1+ (1,0) [0|0] "" Vector__XXX
 SG_ APP_w379_positioningEngineMia : 58|1@1+ (1,0) [0|0] "" Vector__XXX
 SG_ APP_w380_gnssPpsTimestampIssue : 59|1@1+ (1,0) [0|0] "" Vector__XXX
 SG_ APP_w381_apImuTimestampIssue : 60|1@1+ (1,0) [0|0] "" Vector__XXX
 SG_ APP_w382_ubloxImuTimestampIssue : 61|1@1+ (1,0) [0|0] "" Vector__XXX
 SG_ APP_w383_manyApRebootsWhileInP : 62|1@1+ (1,0) [0|0] "" Vector__XXX
 SG_ APP_w384_posEngineInitInMotion : 63|1@1+ (1,0) [0|0] "" Vector__XXX

BO_ 1160 DAS_steeringControl: 8 Vector__XXX
 SG_ DAS_steeringAngleRequest : 6|15@0+ (0.1,-1638.35) [0|0] "" Vector__XXX
 SG_ DAS_steeringHapticRequest : 7|1@0+ (1,0) [0|0] "" Vector__XXX
 SG_ DAS_steeringControlCounter : 19|4@0+ (1,0) [0|0] "" Vector__XXX
 SG_ DAS_steeringControlType : 23|2@0+ (1,0) [0|0] "" Vector__XXX
 SG_ DAS_steeringControlChecksum : 31|8@0+ (1,0) [0|0] "" Vector__XXX

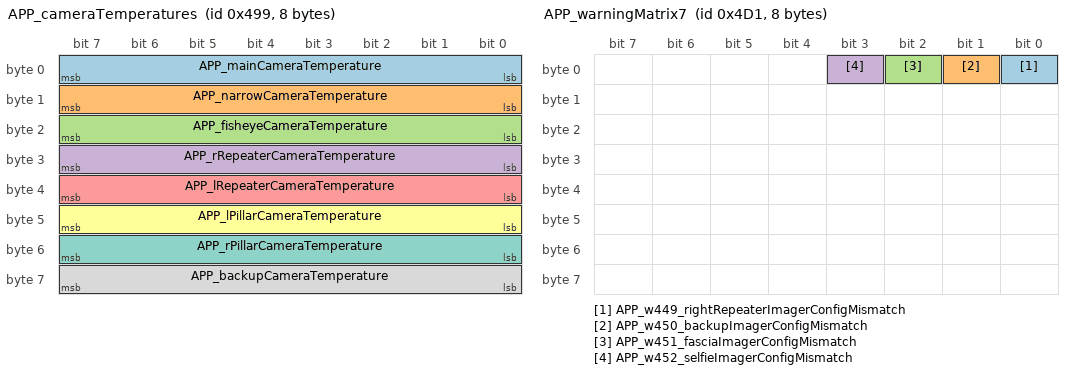
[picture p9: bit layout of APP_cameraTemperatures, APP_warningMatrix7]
BO_ 1177 APP_cameraTemperatures: 8 Vector__XXX
 SG_ APP_mainCameraTemperature : 0|8@1+ (1,-60) [0|0] "" Vector__XXX
 SG_ APP_narrowCameraTemperature : 8|8@1+ (1,-60) [0|0] "" Vector__XXX
 SG_ APP_fisheyeCameraTemperature : 16|8@1+ (1,-60) [0|0] "" Vector__XXX
 SG_ APP_rRepeaterCameraTemperature : 24|8@1+ (1,-60) [0|0] "" Vector__XXX
 SG_ APP_lRepeaterCameraTemperature : 32|8@1+ (1,-60) [0|0] "" Vector__XXX
 SG_ APP_lPillarCameraTemperature : 40|8@1+ (1,-60) [0|0] "" Vector__XXX
 SG_ APP_rPillarCameraTemperature : 48|8@1+ (1,-60) [0|0] "" Vector__XXX
 SG_ APP_backupCameraTemperature : 56|8@1+ (1,-60) [0|0] "" Vector__XXX

BO_ 1233 APP_warningMatrix7: 8 Vector__XXX
 SG_ APP_w449_rightRepeaterImagerConfigMismatch : 0|1@1+ (1,0) [0|0] "" Vector__XXX
 SG_ APP_w450_backupImagerConfigMismatch : 1|1@1+ (1,0) [0|0] "" Vector__XXX
 SG_ APP_w451_fasciaImagerConfigMismatch : 2|1@1+ (1,0) [0|0] "" Vector__XXX
 SG_ APP_w452_selfieImagerConfigMismatch : 3|1@1+ (1,0) [0|0] "" Vector__XXX

BO_ 1249 RCM2_alertLog: 8 Vector__XXX
 SG_ RCM2_alertID M : 0|10@1+ (1,0) [0|0] "" Vector__XXX
 SG_ RCM2_a000_crashDetectedStaticRoll m0 : 13|1@1+ (1,0) [0|0] "" Vector__XXX
 SG_ RCM2_a000_crashDetectedPitch m0 : 14|1@1+ (1,0) [0|0] "" Vector__XXX
 SG_ RCM2_alertState : 15|1@1+ (1,0) [0|0] "" Vector__XXX
 SG_ RCM2_a000_crashDetectedFront m0 : 16|1@1+ (1,0) [0|0] "" Vector__XXX
 SG_ RCM2_a001_nearDeployFront m1 : 16|1@1+ (1,0) [0|0] "" Vector__XXX
 SG_ RCM2_a002_airbagsUnArmed_s m2 : 16|1@1+ (1,0) [0|0] "" Vector__XXX
 SG_ RCM2_a003_warningIndicator_s m3 : 16|1@1+ (1,0) [0|0] "" Vector__XXX
 SG_ RCM2_a004_crashAlgoWakeup_s m4 : 16|1@1+ (1,0) [0|0] "" Vector__XXX
 SG_ RCM2_a005_abuseImmunityThrshold_s m5 : 16|1@1+ (1,0) [0|0] "" Vector__XXX
 SG_ RCM2_a006_supplierDiagEnabled_s m6 : 16|1@1+ (1,0) [0|0] "" Vector__XXX
 SG_ RCM2_a007_pedProCrashDetected_s m7 : 16|1@1+ (1,0) [0|0] "" Vector__XXX
 SG_ RCM2_a008_factoryMode_s m8 : 16|1@1+ (1,0) [0|0] "" Vector__XXX
 SG_ RCM2_a009_edrDataAreaLocked_s m9 : 16|1@1+ (1,0) [0|0] "" Vector__XXX
 SG_ RCM2_a010_pedProEDRDataLocked_s m10 : 16|1@1+ (1,0) [0|0] "" Vector__XXX
 SG_ RCM2_a011_placeholder0_s m11 : 16|1@1+ (1,0) [0|0] "" Vector__XXX
 SG_ RCM2_a012_placeholder1_s m12 : 16|1@1+ (1,0) [0|0] "" Vector__XXX
 SG_ RCM2_a013_placeholder2_s m13 : 16|1@1+ (1,0) [0|0] "" Vector__XXX
 SG_ RCM2_a014_pedProNearDeploy_s m14 : 16|1@1+ (1,0) [0|0] "" Vector__XXX
 SG_ RCM2_a015_noDeployCrashCal_s m15 : 16|1@1+ (1,0) [0|0] "" Vector__XXX
 SG_ RCM2_a016_noDeployPedProCal_s m16 : 16|1@1+ (1,0) [0|0] "" Vector__XXX
 SG_ RCM2_a017_ecuLogAvailable_s m17 : 16|1@1+ (1,0) [0|0] "" Vector__XXX
 SG_ RCM2_a047_batteryESRhigh_s m47 : 16|1@1+ (1,0) [0|0] "" Vector__XXX
 SG_ RCM2_a048_batteryVoltageTooHigh_s m48 : 16|1@1+ (1,0) [0|0] "" Vector__XXX
 SG_ RCM2_a049_batteryVoltageTooLow_s m49 : 16|1@1+ (1,0) [0|0] "" Vector__XXX
 SG_ RCM2_a050_driverABStg1Sht2Gnd_s m50 : 16|1@1+ (1,0) [0|0] "" Vector__XXX
 SG_ RCM2_a051_driverABStg1Sht2Bat_s m51 : 16|1@1+ (1,0) [0|0] "" Vector__XXX
 SG_ RCM2_a052_driverABStg1Open_s m52 : 16|1@1+ (1,0) [0|0] "" Vector__XXX
 SG_ RCM2_a053_driverABStg1Short_s m53 : 16|1@1+ (1,0) [0|0] "" Vector__XXX
 SG_ RCM2_a054_driverABStg1CrssCoup_s m54 : 16|1@1+ (1,0) [0|0] "" Vector__XXX
 SG_ RCM2_a055_driverABStg1Config_s m55 : 16|1@1+ (1,0) [0|0] "" Vector__XXX
 SG_ RCM2_a056_driverABStg2Sht2Gnd_s m56 : 16|1@1+ (1,0) [0|0] "" Vector__XXX
 SG_ RCM2_a057_driverABStg2Sht2Bat_s m57 : 16|1@1+ (1,0) [0|0] "" Vector__XXX
 SG_ RCM2_a058_driverABStg2Open_s m58 : 16|1@1+ (1,0) [0|0] "" Vector__XXX
 SG_ RCM2_a059_driverABStg2Short_s m59 : 16|1@1+ (1,0) [0|0] "" Vector__XXX
 SG_ RCM2_a060_driverABStg2CrssCoup_s m60 : 16|1@1+ (1,0) [0|0] "" Vector__XXX
 SG_ RCM2_a061_driverABStg2Config_s m61 : 16|1@1+ (1,0) [0|0] "" Vector__XXX
 SG_ RCM2_a062_passABStg1Sht2Gnd_s m62 : 16|1@1+ (1,0) [0|0] "" Vector__XXX
 SG_ RCM2_a063_passABStg1Sht2Bat_s m63 : 16|1@1+ (1,0) [0|0] "" Vector__XXX
 SG_ RCM2_a064_passABStg1Open_s m64 : 16|1@1+ (1,0) [0|0] "" Vector__XXX
 SG_ RCM2_a065_passABStg1Short_s m65 : 16|1@1+ (1,0) [0|0] "" Vector__XXX
 SG_ RCM2_a066_passABStg1CrssCoup_s m66 : 16|1@1+ (1,0) [0|0] "" Vector__XXX
 SG_ RCM2_a067_passABStg1Config_s m67 : 16|1@1+ (1,0) [0|0] "" Vector__XXX
 SG_ RCM2_a068_passABStg2Sht2Gnd_s m68 : 16|1@1+ (1,0) [0|0] "" Vector__XXX
 SG_ RCM2_a069_passABStg2Sht2Bat_s m69 : 16|1@1+ (1,0) [0|0] "" Vector__XXX
 SG_ RCM2_a070_passABStg2Open_s m70 : 16|1@1+ (1,0) [0|0] "" Vector__XXX
 SG_ RCM2_a071_passABStg2Short_s m71 : 16|1@1+ (1,0) [0|0] "" Vector__XXX
 SG_ RCM2_a072_passABStg2CrssCoup_s m72 : 16|1@1+ (1,0) [0|0] "" Vector__XXX
 SG_ RCM2_a073_passABStg2Config_s m73 : 16|1@1+ (1,0) [0|0] "" Vector__XXX
 SG_ RCM2_a074_passActiveVentSht2Gnd_s m74 : 16|1@1+ (1,0) [0|0] "" Vector__XXX
 SG_ RCM2_a075_passActiveVentSht2Bat_s m75 : 16|1@1+ (1,0) [0|0] "" Vector__XXX
 SG_ RCM2_a076_passActiveVentOpen_s m76 : 16|1@1+ (1,0) [0|0] "" Vector__XXX
 SG_ RCM2_a077_passActiveVentShort_s m77 : 16|1@1+ (1,0) [0|0] "" Vector__XXX
 SG_ RCM2_a078_passActiveVentCrssCoup_s m78 : 16|1@1+ (1,0) [0|0] "" Vector__XXX
 SG_ RCM2_a079_passActiveVentConfig_s m79 : 16|1@1+ (1,0) [0|0] "" Vector__XXX
 SG_ RCM2_a080_pretenShldLeftSht2Gnd_s m80 : 16|1@1+ (1,0) [0|0] "" Vector__XXX
 SG_ RCM2_a081_pretenShldLeftSht2Bat_s m81 : 16|1@1+ (1,0) [0|0] "" Vector__XXX
 SG_ RCM2_a082_pretenShldLeftOpen_s m82 : 16|1@1+ (1,0) [0|0] "" Vector__XXX
 SG_ RCM2_a083_pretenShldLeftShort_s m83 : 16|1@1+ (1,0) [0|0] "" Vector__XXX
 SG_ RCM2_a084_pretenShldLeftCrossC_s m84 : 16|1@1+ (1,0) [0|0] "" Vector__XXX
 SG_ RCM2_a085_pretenShldLeftConfig_s m85 : 16|1@1+ (1,0) [0|0] "" Vector__XXX
 SG_ RCM2_a086_pretenShldRightSht2Gnd_s m86 : 16|1@1+ (1,0) [0|0] "" Vector__XXX
 SG_ RCM2_a087_pretenShldRightSht2Bat_s m87 : 16|1@1+ (1,0) [0|0] "" Vector__XXX
 SG_ RCM2_a088_pretenShldRightOpen_s m88 : 16|1@1+ (1,0) [0|0] "" Vector__XXX
 SG_ RCM2_a089_pretenShldRightShort_s m89 : 16|1@1+ (1,0) [0|0] "" Vector__XXX
 SG_ RCM2_a090_pretenShldRightCrssCou_s m90 : 16|1@1+ (1,0) [0|0] "" Vector__XXX
 SG_ RCM2_a091_pretenShldRightConfig_s m91 : 16|1@1+ (1,0) [0|0] "" Vector__XXX
 SG_ RCM2_a092_pretenLapLeftSht2Gnd_s m92 : 16|1@1+ (1,0) [0|0] "" Vector__XXX
 SG_ RCM2_a093_pretenLapLeftSht2Bat_s m93 : 16|1@1+ (1,0) [0|0] "" Vector__XXX
 SG_ RCM2_a094_pretenLapLeftOpen_s m94 : 16|1@1+ (1,0) [0|0] "" Vector__XXX
 SG_ RCM2_a095_pretenLapLeftShort_s m95 : 16|1@1+ (1,0) [0|0] "" Vector__XXX
 SG_ RCM2_a096_pretenLapLeftCrssCoup_s m96 : 16|1@1+ (1,0) [0|0] "" Vector__XXX
 SG_ RCM2_a097_pretenLapLeftConfig_s m97 : 16|1@1+ (1,0) [0|0] "" Vector__XXX
 SG_ RCM2_a098_pretenLapRightSht2Gnd_s m98 : 16|1@1+ (1,0) [0|0] "" Vector__XXX
 SG_ RCM2_a099_pretenLapRightSht2Bat_s m99 : 16|1@1+ (1,0) [0|0] "" Vector__XXX
 SG_ RCM2_a100_pretenLapRightOpen_s m100 : 16|1@1+ (1,0) [0|0] "" Vector__XXX
 SG_ RCM2_a101_pretenLapRightShort_s m101 : 16|1@1+ (1,0) [0|0] "" Vector__XXX
 SG_ RCM2_a102_pretenLapRightCrssCoup_s m102 : 16|1@1+ (1,0) [0|0] "" Vector__XXX
 SG_ RCM2_a103_pretenLapRightConfig_s m103 : 16|1@1+ (1,0) [0|0] "" Vector__XXX
 SG_ RCM2_a104_loadLimLeftSht2Gnd_s m104 : 16|1@1+ (1,0) [0|0] "" Vector__XXX
 SG_ RCM2_a105_loadLimLeftSht2Bat_s m105 : 16|1@1+ (1,0) [0|0] "" Vector__XXX
 SG_ RCM2_a106_loadLimLeftOpen_s m106 : 16|1@1+ (1,0) [0|0] "" Vector__XXX
 SG_ RCM2_a107_loadLimLeftShort_s m107 : 16|1@1+ (1,0) [0|0] "" Vector__XXX
 SG_ RCM2_a108_loadLimLeftCrssCoup_s m108 : 16|1@1+ (1,0) [0|0] "" Vector__XXX
 SG_ RCM2_a109_loadLimLeftConfig_s m109 : 16|1@1+ (1,0) [0|0] "" Vector__XXX
 SG_ RCM2_a110_loadLimRightSht2Gnd_s m110 : 16|1@1+ (1,0) [0|0] "" Vector__XXX
 SG_ RCM2_a111_loadLimRightSht2Bat_s m111 : 16|1@1+ (1,0) [0|0] "" Vector__XXX
 SG_ RCM2_a112_loadLimRightOpen_s m112 : 16|1@1+ (1,0) [0|0] "" Vector__XXX
 SG_ RCM2_a113_loadLimRightShort_s m113 : 16|1@1+ (1,0) [0|0] "" Vector__XXX
 SG_ RCM2_a114_loadLimRightCrssCoup_s m114 : 16|1@1+ (1,0) [0|0] "" Vector__XXX
 SG_ RCM2_a115_loadLimRightConfig_s m115 : 16|1@1+ (1,0) [0|0] "" Vector__XXX
 SG_ RCM2_a116_kneeABDrvrSht2Gnd_s m116 : 16|1@1+ (1,0) [0|0] "" Vector__XXX
 SG_ RCM2_a117_kneeABDrvrSht2Bat_s m117 : 16|1@1+ (1,0) [0|0] "" Vector__XXX
 SG_ RCM2_a118_kneeABDrvrOpen_s m118 : 16|1@1+ (1,0) [0|0] "" Vector__XXX
 SG_ RCM2_a119_kneeABDrvrShort_s m119 : 16|1@1+ (1,0) [0|0] "" Vector__XXX
 SG_ RCM2_a120_kneeABDrvrCrssCoup_s m120 : 16|1@1+ (1,0) [0|0] "" Vector__XXX
 SG_ RCM2_a121_kneeABDrvrConfig_s m121 : 16|1@1+ (1,0) [0|0] "" Vector__XXX
 SG_ RCM2_a122_kneeABPassSht2Gnd_s m122 : 16|1@1+ (1,0) [0|0] "" Vector__XXX
 SG_ RCM2_a123_kneeABPassSht2Bat_s m123 : 16|1@1+ (1,0) [0|0] "" Vector__XXX
 SG_ RCM2_a124_kneeABPassOpen_s m124 : 16|1@1+ (1,0) [0|0] "" Vector__XXX
 SG_ RCM2_a125_kneeABPassShort_s m125 : 16|1@1+ (1,0) [0|0] "" Vector__XXX
 SG_ RCM2_a126_kneeABPassCrssCoup_s m126 : 16|1@1+ (1,0) [0|0] "" Vector__XXX
 SG_ RCM2_a127_kneeABPassConfig_s m127 : 16|1@1+ (1,0) [0|0] "" Vector__XXX
 SG_ RCM2_a128_sideAB1stRowLSht2Gnd_s m128 : 16|1@1+ (1,0) [0|0] "" Vector__XXX
 SG_ RCM2_a129_sideAB1stRowLSht2Bat_s m129 : 16|1@1+ (1,0) [0|0] "" Vector__XXX
 SG_ RCM2_a130_sideAB1stRowLOpen_s m130 : 16|1@1+ (1,0) [0|0] "" Vector__XXX
 SG_ RCM2_a131_sideAB1stRowLShort_s m131 : 16|1@1+ (1,0) [0|0] "" Vector__XXX
 SG_ RCM2_a132_sideAB1stRowLCrssCoup_s m132 : 16|1@1+ (1,0) [0|0] "" Vector__XXX
 SG_ RCM2_a133_sideAB1stRowLConfig_s m133 : 16|1@1+ (1,0) [0|0] "" Vector__XXX
 SG_ RCM2_a134_sideAB1stRowRSht2Gnd_s m134 : 16|1@1+ (1,0) [0|0] "" Vector__XXX
 SG_ RCM2_a135_sideAB1stRowRSht2Bat_s m135 : 16|1@1+ (1,0) [0|0] "" Vector__XXX
 SG_ RCM2_a136_sideAB1stRowROpen_s m136 : 16|1@1+ (1,0) [0|0] "" Vector__XXX
 SG_ RCM2_a137_sideAB1stRowRShort_s m137 : 16|1@1+ (1,0) [0|0] "" Vector__XXX
 SG_ RCM2_a138_sideAB1stRowRCrssCoup_s m138 : 16|1@1+ (1,0) [0|0] "" Vector__XXX
 SG_ RCM2_a139_sideAB1stRowRConfig_s m139 : 16|1@1+ (1,0) [0|0] "" Vector__XXX
 SG_ RCM2_a140_hvdPyroSht2Gnd_s m140 : 16|1@1+ (1,0) [0|0] "" Vector__XXX
 SG_ RCM2_a141_hvdPyroSht2Bat_s m141 : 16|1@1+ (1,0) [0|0] "" Vector__XXX
 SG_ RCM2_a142_hvdPyroOpen_s m142 : 16|1@1+ (1,0) [0|0] "" Vector__XXX
 SG_ RCM2_a143_hvdPyroShort_s m143 : 16|1@1+ (1,0) [0|0] "" Vector__XXX
 SG_ RCM2_a144_hvdPyroCrssCoup_s m144 : 16|1@1+ (1,0) [0|0] "" Vector__XXX
 SG_ RCM2_a145_hvdPyroConfig_s m145 : 16|1@1+ (1,0) [0|0] "" Vector__XXX
 SG_ RCM2_a146_curABLeftSht2Gnd_s m146 : 16|1@1+ (1,0) [0|0] "" Vector__XXX
 SG_ RCM2_a147_curABLeftSht2Bat_s m147 : 16|1@1+ (1,0) [0|0] "" Vector__XXX
 SG_ RCM2_a148_curABLeftOpen_s m148 : 16|1@1+ (1,0) [0|0] "" Vector__XXX
 SG_ RCM2_a149_curABLeftShort_s m149 : 16|1@1+ (1,0) [0|0] "" Vector__XXX
 SG_ RCM2_a150_curABLeftCrssCoup_s m150 : 16|1@1+ (1,0) [0|0] "" Vector__XXX
 SG_ RCM2_a151_curABLeftConfig_s m151 : 16|1@1+ (1,0) [0|0] "" Vector__XXX
 SG_ RCM2_a152_curABRightSht2Gnd_s m152 : 16|1@1+ (1,0) [0|0] "" Vector__XXX
 SG_ RCM2_a153_curABRightSht2Bat_s m153 : 16|1@1+ (1,0) [0|0] "" Vector__XXX
 SG_ RCM2_a154_curABRightOpen_s m154 : 16|1@1+ (1,0) [0|0] "" Vector__XXX
 SG_ RCM2_a155_curABRightShort_s m155 : 16|1@1+ (1,0) [0|0] "" Vector__XXX
 SG_ RCM2_a156_curABRightCrssCoup_s m156 : 16|1@1+ (1,0) [0|0] "" Vector__XXX
 SG_ RCM2_a157_curABRightConfig_s m157 : 16|1@1+ (1,0) [0|0] "" Vector__XXX
 SG_ RCM2_a158_preten2ndRowLSht2Gnd_s m158 : 16|1@1+ (1,0) [0|0] "" Vector__XXX
 SG_ RCM2_a159_preten2ndRowLSht2Bat_s m159 : 16|1@1+ (1,0) [0|0] "" Vector__XXX
 SG_ RCM2_a160_preten2ndRowLOpen_s m160 : 16|1@1+ (1,0) [0|0] "" Vector__XXX
 SG_ RCM2_a161_preten2ndRowLShort_s m161 : 16|1@1+ (1,0) [0|0] "" Vector__XXX
 SG_ RCM2_a162_preten2ndRowLCrssCoup_s m162 : 16|1@1+ (1,0) [0|0] "" Vector__XXX
 SG_ RCM2_a163_preten2ndRowLCgf_s m163 : 16|1@1+ (1,0) [0|0] "" Vector__XXX
 SG_ RCM2_a164_preten2ndRowRSht2Gnd_s m164 : 16|1@1+ (1,0) [0|0] "" Vector__XXX
 SG_ RCM2_a165_preten2ndRowRSht2Bat_s m165 : 16|1@1+ (1,0) [0|0] "" Vector__XXX
 SG_ RCM2_a166_preten2ndRowROpen_s m166 : 16|1@1+ (1,0) [0|0] "" Vector__XXX
 SG_ RCM2_a167_preten2ndRowRShort_s m167 : 16|1@1+ (1,0) [0|0] "" Vector__XXX
 SG_ RCM2_a168_preten2ndRowRCrssCoup_s m168 : 16|1@1+ (1,0) [0|0] "" Vector__XXX
 SG_ RCM2_a169_preten2ndRowRCgf_s m169 : 16|1@1+ (1,0) [0|0] "" Vector__XXX
 SG_ RCM2_a170_curAB2ndRowLSht2Gnd_s m170 : 16|1@1+ (1,0) [0|0] "" Vector__XXX
 SG_ RCM2_a171_curAB2ndRowLSht2Bat_s m171 : 16|1@1+ (1,0) [0|0] "" Vector__XXX
 SG_ RCM2_a172_curAB2ndRowLOpen_s m172 : 16|1@1+ (1,0) [0|0] "" Vector__XXX
 SG_ RCM2_a173_curAB2ndRowLShort_s m173 : 16|1@1+ (1,0) [0|0] "" Vector__XXX
 SG_ RCM2_a174_curAB2ndRowLCrssCoup_s m174 : 16|1@1+ (1,0) [0|0] "" Vector__XXX
 SG_ RCM2_a175_curAB2ndRowLConfig_s m175 : 16|1@1+ (1,0) [0|0] "" Vector__XXX
 SG_ RCM2_a176_curAB2ndRowRSht2Gnd_s m176 : 16|1@1+ (1,0) [0|0] "" Vector__XXX
 SG_ RCM2_a177_curAB2ndRowRSht2Bat_s m177 : 16|1@1+ (1,0) [0|0] "" Vector__XXX
 SG_ RCM2_a178_curAB2ndRowROpen_s m178 : 16|1@1+ (1,0) [0|0] "" Vector__XXX
 SG_ RCM2_a179_curAB2ndRowRShort_s m179 : 16|1@1+ (1,0) [0|0] "" Vector__XXX
 SG_ RCM2_a180_curAB2ndRowRCrssCoup_s m180 : 16|1@1+ (1,0) [0|0] "" Vector__XXX
 SG_ RCM2_a181_curAB2ndRowRConfig_s m181 : 16|1@1+ (1,0) [0|0] "" Vector__XXX
 SG_ RCM2_a182_hoodActuatorRSht2Gnd_s m182 : 16|1@1+ (1,0) [0|0] "" Vector__XXX
 SG_ RCM2_a183_hoodActuatorRSht2Bat_s m183 : 16|1@1+ (1,0) [0|0] "" Vector__XXX
 SG_ RCM2_a184_hoodActuatorROpen_s m184 : 16|1@1+ (1,0) [0|0] "" Vector__XXX
 SG_ RCM2_a185_hoodActuatorRShort_s m185 : 16|1@1+ (1,0) [0|0] "" Vector__XXX
 SG_ RCM2_a186_hoodActuatorRCrssCoup_s m186 : 16|1@1+ (1,0) [0|0] "" Vector__XXX
 SG_ RCM2_a187_hoodActuatorRConfig_s m187 : 16|1@1+ (1,0) [0|0] "" Vector__XXX
 SG_ RCM2_a188_hoodActuatorLSht2Gnd_s m188 : 16|1@1+ (1,0) [0|0] "" Vector__XXX
 SG_ RCM2_a189_hoodActuatorLSht2Bat_s m189 : 16|1@1+ (1,0) [0|0] "" Vector__XXX
 SG_ RCM2_a190_hoodActuatorLOpen_s m190 : 16|1@1+ (1,0) [0|0] "" Vector__XXX
 SG_ RCM2_a191_hoodActuatorLShort_s m191 : 16|1@1+ (1,0) [0|0] "" Vector__XXX
 SG_ RCM2_a192_hoodActuatorLCrssCoup_s m192 : 16|1@1+ (1,0) [0|0] "" Vector__XXX
 SG_ RCM2_a193_hoodActuatorLConfig_s m193 : 16|1@1+ (1,0) [0|0] "" Vector__XXX
 SG_ RCM2_a194_driverABAVSht2Gnd_s m194 : 16|1@1+ (1,0) [0|0] "" Vector__XXX
 SG_ RCM2_a195_driverABAVSht2Bat_s m195 : 16|1@1+ (1,0) [0|0] "" Vector__XXX
 SG_ RCM2_a196_driverABAVOpen_s m196 : 16|1@1+ (1,0) [0|0] "" Vector__XXX
 SG_ RCM2_a197_driverABAVShort_s m197 : 16|1@1+ (1,0) [0|0] "" Vector__XXX
 SG_ RCM2_a198_driverABAVCrossCoup_s m198 : 16|1@1+ (1,0) [0|0] "" Vector__XXX
 SG_ RCM2_a199_driverABAVConfig_s m199 : 16|1@1+ (1,0) [0|0] "" Vector__XXX
 SG_ RCM2_a200_driverFSABSht2Gnd_s m200 : 16|1@1+ (1,0) [0|0] "" Vector__XXX
 SG_ RCM2_a201_driverFSABSht2Bat_s m201 : 16|1@1+ (1,0) [0|0] "" Vector__XXX
 SG_ RCM2_a202_driverFSABOpen_s m202 : 16|1@1+ (1,0) [0|0] "" Vector__XXX
 SG_ RCM2_a203_driverFSABShort_s m203 : 16|1@1+ (1,0) [0|0] "" Vector__XXX
 SG_ RCM2_a204_driverFSABCrossCoup_s m204 : 16|1@1+ (1,0) [0|0] "" Vector__XXX
 SG_ RCM2_a205_driverFSABConfig_s m205 : 16|1@1+ (1,0) [0|0] "" Vector__XXX
 SG_ RCM2_a206_sideAB2ndRowLSht2Gnd_s m206 : 16|1@1+ (1,0) [0|0] "" Vector__XXX
 SG_ RCM2_a207_sideAB2ndRowLSht2Bat_s m207 : 16|1@1+ (1,0) [0|0] "" Vector__XXX
 SG_ RCM2_a208_sideAB2ndRowLOpen_s m208 : 16|1@1+ (1,0) [0|0] "" Vector__XXX
 SG_ RCM2_a209_sideAB2ndRowLShort_s m209 : 16|1@1+ (1,0) [0|0] "" Vector__XXX
 SG_ RCM2_a210_sideAB2ndRowLCrssCoup_s m210 : 16|1@1+ (1,0) [0|0] "" Vector__XXX
 SG_ RCM2_a211_sideAB2ndRowLConfig_s m211 : 16|1@1+ (1,0) [0|0] "" Vector__XXX
 SG_ RCM2_a212_sideAB2ndRowRSht2Gnd_s m212 : 16|1@1+ (1,0) [0|0] "" Vector__XXX
 SG_ RCM2_a213_sideAB2ndRowRSht2Bat_s m213 : 16|1@1+ (1,0) [0|0] "" Vector__XXX
 SG_ RCM2_a214_sideAB2ndRowROpen_s m214 : 16|1@1+ (1,0) [0|0] "" Vector__XXX
 SG_ RCM2_a215_sideAB2ndRowRShort_s m215 : 16|1@1+ (1,0) [0|0] "" Vector__XXX
 SG_ RCM2_a216_sideAB2ndRowRCrssCoup_s m216 : 16|1@1+ (1,0) [0|0] "" Vector__XXX
 SG_ RCM2_a217_sideAB2ndRowRConfig_s m217 : 16|1@1+ (1,0) [0|0] "" Vector__XXX
 SG_ RCM2_a250_ens1Sht2Bat_s m250 : 16|1@1+ (1,0) [0|0] "" Vector__XXX
 SG_ RCM2_a251_ens1Sht2Gnd_s m251 : 16|1@1+ (1,0) [0|0] "" Vector__XXX
 SG_ RCM2_a252_ens1Config_s m252 : 16|1@1+ (1,0) [0|0] "" Vector__XXX
 SG_ RCM2_a253_ens2Sht2Bat_s m253 : 16|1@1+ (1,0) [0|0] "" Vector__XXX
 SG_ RCM2_a254_ens2Sht2Gnd_s m254 : 16|1@1+ (1,0) [0|0] "" Vector__XXX
 SG_ RCM2_a255_ens2Config_s m255 : 16|1@1+ (1,0) [0|0] "" Vector__XXX
 SG_ RCM2_a256_ens3Sht2Bat_s m256 : 16|1@1+ (1,0) [0|0] "" Vector__XXX
 SG_ RCM2_a257_ens3Sht2Gnd_s m257 : 16|1@1+ (1,0) [0|0] "" Vector__XXX
 SG_ RCM2_a258_ens3Config_s m258 : 16|1@1+ (1,0) [0|0] "" Vector__XXX
 SG_ RCM2_a259_ens4Sht2Bat_s m259 : 16|1@1+ (1,0) [0|0] "" Vector__XXX
 SG_ RCM2_a260_ens4Sht2Gnd_s m260 : 16|1@1+ (1,0) [0|0] "" Vector__XXX
 SG_ RCM2_a261_ens4Config_s m261 : 16|1@1+ (1,0) [0|0] "" Vector__XXX
 SG_ RCM2_a264_imuYawR8OffCompPosLife_s m264 : 16|1@1+ (1,0) [0|0] "" Vector__XXX
 SG_ RCM2_a265_imuYawR8OffCompNegLife_s m265 : 16|1@1+ (1,0) [0|0] "" Vector__XXX
 SG_ RCM2_a266_imuYawR8OffCompPosFLDC_s m266 : 16|1@1+ (1,0) [0|0] "" Vector__XXX
 SG_ RCM2_a267_imuYawR8OffCompNegFLDC_s m267 : 16|1@1+ (1,0) [0|0] "" Vector__XXX
 SG_ RCM2_a268_imuYawR8OffCompPosSLDC_s m268 : 16|1@1+ (1,0) [0|0] "" Vector__XXX
 SG_ RCM2_a269_imuYawR8OffCompNegSLDC_s m269 : 16|1@1+ (1,0) [0|0] "" Vector__XXX
 SG_ RCM2_a270_imuPtchR8OffCompPosLife_s m270 : 16|1@1+ (1,0) [0|0] "" Vector__XXX
 SG_ RCM2_a271_imuPtchR8OffCompNegLife_s m271 : 16|1@1+ (1,0) [0|0] "" Vector__XXX
 SG_ RCM2_a272_imuPtchR8OffCompPosFLDC_s m272 : 16|1@1+ (1,0) [0|0] "" Vector__XXX
 SG_ RCM2_a273_imuPtchR8OffCompNegFLDC_s m273 : 16|1@1+ (1,0) [0|0] "" Vector__XXX
 SG_ RCM2_a274_imuPtchR8OffCompPosSLDC_s m274 : 16|1@1+ (1,0) [0|0] "" Vector__XXX
 SG_ RCM2_a275_imuPtchR8OffCompNegSLDC_s m275 : 16|1@1+ (1,0) [0|0] "" Vector__XXX
 SG_ RCM2_a276_imuRollR8OffCompPosLife_s m276 : 16|1@1+ (1,0) [0|0] "" Vector__XXX
 SG_ RCM2_a277_imuRollR8OffCompNegLife_s m277 : 16|1@1+ (1,0) [0|0] "" Vector__XXX
 SG_ RCM2_a278_imuRollR8OffCompPosFLDC_s m278 : 16|1@1+ (1,0) [0|0] "" Vector__XXX
 SG_ RCM2_a279_imuRollR8OffCompNegFLDC_s m279 : 16|1@1+ (1,0) [0|0] "" Vector__XXX
 SG_ RCM2_a280_imuRollR8OffCompPosSLDC_s m280 : 16|1@1+ (1,0) [0|0] "" Vector__XXX
 SG_ RCM2_a281_imuRollR8OffCompNegSLDC_s m281 : 16|1@1+ (1,0) [0|0] "" Vector__XXX
 SG_ RCM2_a282_imuLongAOffCompPosLife_s m282 : 16|1@1+ (1,0) [0|0] "" Vector__XXX
 SG_ RCM2_a283_imuLongAOffCompNegLife_s m283 : 16|1@1+ (1,0) [0|0] "" Vector__XXX
 SG_ RCM2_a284_imuLongAOffCompPosFLDC_s m284 : 16|1@1+ (1,0) [0|0] "" Vector__XXX
 SG_ RCM2_a285_imuLongAOffCompNegFLDC_s m285 : 16|1@1+ (1,0) [0|0] "" Vector__XXX
 SG_ RCM2_a286_imuLongAOffCompPosSLDC_s m286 : 16|1@1+ (1,0) [0|0] "" Vector__XXX
 SG_ RCM2_a287_imuLongAOffCompNegSLDC_s m287 : 16|1@1+ (1,0) [0|0] "" Vector__XXX
 SG_ RCM2_a288_imuLatAcOffCompPosLife_s m288 : 16|1@1+ (1,0) [0|0] "" Vector__XXX
 SG_ RCM2_a289_imuLatAcOffCompNegLife_s m289 : 16|1@1+ (1,0) [0|0] "" Vector__XXX
 SG_ RCM2_a290_imuLatAcOffCompPosFLDC_s m290 : 16|1@1+ (1,0) [0|0] "" Vector__XXX
 SG_ RCM2_a291_imuLatAcOffCompNegFLDC_s m291 : 16|1@1+ (1,0) [0|0] "" Vector__XXX
 SG_ RCM2_a292_imuLatAcOffCompPosSLDC_s m292 : 16|1@1+ (1,0) [0|0] "" Vector__XXX
 SG_ RCM2_a293_imuLatAcOffCompNegSLDC_s m293 : 16|1@1+ (1,0) [0|0] "" Vector__XXX
 SG_ RCM2_a294_imuVertAOffCompPosLife_s m294 : 16|1@1+ (1,0) [0|0] "" Vector__XXX
 SG_ RCM2_a295_imuVertAOffCompNegLife_s m295 : 16|1@1+ (1,0) [0|0] "" Vector__XXX
 SG_ RCM2_a296_imuVertAOffCompPosFLDC_s m296 : 16|1@1+ (1,0) [0|0] "" Vector__XXX
 SG_ RCM2_a297_imuVertAOffCompNegFLDC_s m297 : 16|1@1+ (1,0) [0|0] "" Vector__XXX
 SG_ RCM2_a298_imuVertAOffCompPosSLDC_s m298 : 16|1@1+ (1,0) [0|0] "" Vector__XXX
 SG_ RCM2_a299_imuVertAOffCompNegSLDC_s m299 : 16|1@1+ (1,0) [0|0] "" Vector__XXX
 SG_ RCM2_a300_imuAccXHgMonChlPerm_s m300 : 16|1@1+ (1,0) [0|0] "" Vector__XXX
 SG_ RCM2_a301_imuAccXHgMonChlTemp_s m301 : 16|1@1+ (1,0) [0|0] "" Vector__XXX
 SG_ RCM2_a302_imuAccYHgMonChlPerm_s m302 : 16|1@1+ (1,0) [0|0] "" Vector__XXX
 SG_ RCM2_a303_imuAccYHgMonChlTemp_s m303 : 16|1@1+ (1,0) [0|0] "" Vector__XXX
 SG_ RCM2_a304_imuYawR8SnsrPermBG_s m304 : 16|1@1+ (1,0) [0|0] "" Vector__XXX
 SG_ RCM2_a305_imuYawR8SnsrPermInit_s m305 : 16|1@1+ (1,0) [0|0] "" Vector__XXX
 SG_ RCM2_a306_imuYawR8SnsrPermLF_s m306 : 16|1@1+ (1,0) [0|0] "" Vector__XXX
 SG_ RCM2_a307_imuYawR8ChnlMonTmpLF_s m307 : 16|1@1+ (1,0) [0|0] "" Vector__XXX
 SG_ RCM2_a308_imuPitchR8SnsrPermBG_s m308 : 16|1@1+ (1,0) [0|0] "" Vector__XXX
 SG_ RCM2_a309_imuPitchR8SnsrPermInit_s m309 : 16|1@1+ (1,0) [0|0] "" Vector__XXX
 SG_ RCM2_a310_imuPitchR8SnsrPermLF_s m310 : 16|1@1+ (1,0) [0|0] "" Vector__XXX
 SG_ RCM2_a311_imuPitchR8ChnlMonTmpLF_s m311 : 16|1@1+ (1,0) [0|0] "" Vector__XXX
 SG_ RCM2_a312_imuRollR8SnsrPermBG_s m312 : 16|1@1+ (1,0) [0|0] "" Vector__XXX
 SG_ RCM2_a313_imuRollR8SnsrPermInit_s m313 : 16|1@1+ (1,0) [0|0] "" Vector__XXX
 SG_ RCM2_a314_imuRollR8SnsrPermLF_s m314 : 16|1@1+ (1,0) [0|0] "" Vector__XXX
 SG_ RCM2_a315_imuRollR8ChnlMonTmpLF_s m315 : 16|1@1+ (1,0) [0|0] "" Vector__XXX
 SG_ RCM2_a316_imuAccXLgMonChlPerm_s m316 : 16|1@1+ (1,0) [0|0] "" Vector__XXX
 SG_ RCM2_a317_imuAccXLgMonChlTemp_s m317 : 16|1@1+ (1,0) [0|0] "" Vector__XXX
 SG_ RCM2_a318_imuAccYLgMonChlPerm_s m318 : 16|1@1+ (1,0) [0|0] "" Vector__XXX
 SG_ RCM2_a319_imuAccYLgMonChlTemp_s m319 : 16|1@1+ (1,0) [0|0] "" Vector__XXX
 SG_ RCM2_a320_imuAccZLgMonChlPerm_s m320 : 16|1@1+ (1,0) [0|0] "" Vector__XXX
 SG_ RCM2_a321_imuAccZLgMonChlTemp_s m321 : 16|1@1+ (1,0) [0|0] "" Vector__XXX
 SG_ RCM2_a322_imuCalibrationFailed_s m322 : 16|1@1+ (1,0) [0|0] "" Vector__XXX
 SG_ RCM2_a323_imuCalibrationNotDone_s m323 : 16|1@1+ (1,0) [0|0] "" Vector__XXX
 SG_ RCM2_a350_upFrntSnsrLSht2Gnd_s m350 : 16|1@1+ (1,0) [0|0] "" Vector__XXX
 SG_ RCM2_a351_upFrntSnsrLSht2Bat_s m351 : 16|1@1+ (1,0) [0|0] "" Vector__XXX
 SG_ RCM2_a352_upFrntSnsrLOpen_s m352 : 16|1@1+ (1,0) [0|0] "" Vector__XXX
 SG_ RCM2_a353_upFrntSnsrLCrssCoup_s m353 : 16|1@1+ (1,0) [0|0] "" Vector__XXX
 SG_ RCM2_a354_upFrntSnsrLCommErr_s m354 : 16|1@1+ (1,0) [0|0] "" Vector__XXX
 SG_ RCM2_a355_upFrntSnsrLInitTyp_s m355 : 16|1@1+ (1,0) [0|0] "" Vector__XXX
 SG_ RCM2_a356_upFrntSnsrLConfig_s m356 : 16|1@1+ (1,0) [0|0] "" Vector__XXX
 SG_ RCM2_a357_upFrntSnsrLDefect_s m357 : 16|1@1+ (1,0) [0|0] "" Vector__XXX
 SG_ RCM2_a358_upFrntSnsrLSigMon_s m358 : 16|1@1+ (1,0) [0|0] "" Vector__XXX
 SG_ RCM2_a360_upFrntSnsrRSht2Gnd_s m360 : 16|1@1+ (1,0) [0|0] "" Vector__XXX
 SG_ RCM2_a361_upFrntSnsrRSht2Bat_s m361 : 16|1@1+ (1,0) [0|0] "" Vector__XXX
 SG_ RCM2_a362_upFrntSnsrROpen_s m362 : 16|1@1+ (1,0) [0|0] "" Vector__XXX
 SG_ RCM2_a363_upFrntSnsrRCrssCoup_s m363 : 16|1@1+ (1,0) [0|0] "" Vector__XXX
 SG_ RCM2_a364_upFrntSnsrRCommErr_s m364 : 16|1@1+ (1,0) [0|0] "" Vector__XXX
 SG_ RCM2_a365_upFrntSnsrRInitTyp_s m365 : 16|1@1+ (1,0) [0|0] "" Vector__XXX
 SG_ RCM2_a366_upFrntSnsrRConfig_s m366 : 16|1@1+ (1,0) [0|0] "" Vector__XXX
 SG_ RCM2_a367_upFrntSnsrRDefect_s m367 : 16|1@1+ (1,0) [0|0] "" Vector__XXX
 SG_ RCM2_a368_upFrntSnsrRSigMon_s m368 : 16|1@1+ (1,0) [0|0] "" Vector__XXX
 SG_ RCM2_a370_upFrntSnsrMidLSht2Gnd_s m370 : 16|1@1+ (1,0) [0|0] "" Vector__XXX
 SG_ RCM2_a371_upFrntSnsrMidLSht2Bat_s m371 : 16|1@1+ (1,0) [0|0] "" Vector__XXX
 SG_ RCM2_a372_upFrntSnsrMidLOpen_s m372 : 16|1@1+ (1,0) [0|0] "" Vector__XXX
 SG_ RCM2_a373_upFrntSnsrMidLCrssCoup_s m373 : 16|1@1+ (1,0) [0|0] "" Vector__XXX
 SG_ RCM2_a374_upFrntSnsrMidLCommErr_s m374 : 16|1@1+ (1,0) [0|0] "" Vector__XXX
 SG_ RCM2_a375_upFrntSnsrMidLInitTyp_s m375 : 16|1@1+ (1,0) [0|0] "" Vector__XXX
 SG_ RCM2_a376_upFrntSnsrMidLConfig_s m376 : 16|1@1+ (1,0) [0|0] "" Vector__XXX
 SG_ RCM2_a377_upFrntSnsrMidLDefect_s m377 : 16|1@1+ (1,0) [0|0] "" Vector__XXX
 SG_ RCM2_a378_upFrntSnsrMidLSigMon_s m378 : 16|1@1+ (1,0) [0|0] "" Vector__XXX
 SG_ RCM2_a380_upFrntSnsrMidRSht2Gnd_s m380 : 16|1@1+ (1,0) [0|0] "" Vector__XXX
 SG_ RCM2_a381_upFrntSnsrMidRSht2Bat_s m381 : 16|1@1+ (1,0) [0|0] "" Vector__XXX
 SG_ RCM2_a382_upFrntSnsrMidROpen_s m382 : 16|1@1+ (1,0) [0|0] "" Vector__XXX
 SG_ RCM2_a383_upFrntSnsrMidRCrssCoup_s m383 : 16|1@1+ (1,0) [0|0] "" Vector__XXX
 SG_ RCM2_a384_upFrntSnsrMidRCommErr_s m384 : 16|1@1+ (1,0) [0|0] "" Vector__XXX
 SG_ RCM2_a385_upFrntSnsrMidRInitTyp_s m385 : 16|1@1+ (1,0) [0|0] "" Vector__XXX
 SG_ RCM2_a386_upFrntSnsrMidRConfig_s m386 : 16|1@1+ (1,0) [0|0] "" Vector__XXX
 SG_ RCM2_a387_upFrntSnsrMidRDefect_s m387 : 16|1@1+ (1,0) [0|0] "" Vector__XXX
 SG_ RCM2_a388_upFrntSnsrMidRSigMon_s m388 : 16|1@1+ (1,0) [0|0] "" Vector__XXX
 SG_ RCM2_a390_sideAccelBPilLSht2Gnd_s m390 : 16|1@1+ (1,0) [0|0] "" Vector__XXX
 SG_ RCM2_a391_sideAccelBPilLSht2Bat_s m391 : 16|1@1+ (1,0) [0|0] "" Vector__XXX
 SG_ RCM2_a392_sideAccelBPilLOpen_s m392 : 16|1@1+ (1,0) [0|0] "" Vector__XXX
 SG_ RCM2_a393_sideAccelBPilLCLosCoup_s m393 : 16|1@1+ (1,0) [0|0] "" Vector__XXX
 SG_ RCM2_a394_sideAccelBPilLCommErr_s m394 : 16|1@1+ (1,0) [0|0] "" Vector__XXX
 SG_ RCM2_a395_sideAccelBPilLInitTyp_s m395 : 16|1@1+ (1,0) [0|0] "" Vector__XXX
 SG_ RCM2_a396_sideAccelBPilLConfig_s m396 : 16|1@1+ (1,0) [0|0] "" Vector__XXX
 SG_ RCM2_a397_sideAccelBPilLDefect_s m397 : 16|1@1+ (1,0) [0|0] "" Vector__XXX
 SG_ RCM2_a398_sideAccelBPilLSigMon_s m398 : 16|1@1+ (1,0) [0|0] "" Vector__XXX
 SG_ RCM2_a400_sideAccelBPilRSht2Gnd_s m400 : 16|1@1+ (1,0) [0|0] "" Vector__XXX
 SG_ RCM2_a401_sideAccelBPilRSht2Bat_s m401 : 16|1@1+ (1,0) [0|0] "" Vector__XXX
 SG_ RCM2_a402_sideAccelBPilROpen_s m402 : 16|1@1+ (1,0) [0|0] "" Vector__XXX
 SG_ RCM2_a403_sideAccelBPilRCrssCoup_s m403 : 16|1@1+ (1,0) [0|0] "" Vector__XXX
 SG_ RCM2_a404_sideAccelBPilRCommErr_s m404 : 16|1@1+ (1,0) [0|0] "" Vector__XXX
 SG_ RCM2_a405_sideAccelBPilRInitTyp_s m405 : 16|1@1+ (1,0) [0|0] "" Vector__XXX
 SG_ RCM2_a406_sideAccelBPilRConfig_s m406 : 16|1@1+ (1,0) [0|0] "" Vector__XXX
 SG_ RCM2_a407_sideAccelBPilRDefect_s m407 : 16|1@1+ (1,0) [0|0] "" Vector__XXX
 SG_ RCM2_a408_sideAccelBPilRSigMon_s m408 : 16|1@1+ (1,0) [0|0] "" Vector__XXX
 SG_ RCM2_a410_sideAccelCPilLSht2Gnd_s m410 : 16|1@1+ (1,0) [0|0] "" Vector__XXX
 SG_ RCM2_a411_sideAccelCPilLSht2Bat_s m411 : 16|1@1+ (1,0) [0|0] "" Vector__XXX
 SG_ RCM2_a412_sideAccelCPilLOpen_s m412 : 16|1@1+ (1,0) [0|0] "" Vector__XXX
 SG_ RCM2_a413_sideAccelCPilLCrssCoup_s m413 : 16|1@1+ (1,0) [0|0] "" Vector__XXX
 SG_ RCM2_a414_sideAccelCPilLCommErr_s m414 : 16|1@1+ (1,0) [0|0] "" Vector__XXX
 SG_ RCM2_a415_sideAccelCPilLInitTyp_s m415 : 16|1@1+ (1,0) [0|0] "" Vector__XXX
 SG_ RCM2_a416_sideAccelCPilLConfig_s m416 : 16|1@1+ (1,0) [0|0] "" Vector__XXX
 SG_ RCM2_a417_sideAccelCPilLDefect_s m417 : 16|1@1+ (1,0) [0|0] "" Vector__XXX
 SG_ RCM2_a418_sideAccelCPilLSigMon_s m418 : 16|1@1+ (1,0) [0|0] "" Vector__XXX
 SG_ RCM2_a420_sideAccelCPilRSht2Gnd_s m420 : 16|1@1+ (1,0) [0|0] "" Vector__XXX
 SG_ RCM2_a421_sideAccelCPilRSht2Bat_s m421 : 16|1@1+ (1,0) [0|0] "" Vector__XXX
 SG_ RCM2_a422_sideAccelCPilROpen_s m422 : 16|1@1+ (1,0) [0|0] "" Vector__XXX
 SG_ RCM2_a423_sideAccelCPilRCrssCoup_s m423 : 16|1@1+ (1,0) [0|0] "" Vector__XXX
 SG_ RCM2_a424_sideAccelCPilRCommErr_s m424 : 16|1@1+ (1,0) [0|0] "" Vector__XXX
 SG_ RCM2_a425_sideAccelCPilRInitTyp_s m425 : 16|1@1+ (1,0) [0|0] "" Vector__XXX
 SG_ RCM2_a426_sideAccelCPilRConfig_s m426 : 16|1@1+ (1,0) [0|0] "" Vector__XXX
 SG_ RCM2_a427_sideAccelCPilRDefect_s m427 : 16|1@1+ (1,0) [0|0] "" Vector__XXX
 SG_ RCM2_a428_sideAccelCPilRSigMon_s m428 : 16|1@1+ (1,0) [0|0] "" Vector__XXX
 SG_ RCM2_a430_presFrntLDoorSht2Gnd_s m430 : 16|1@1+ (1,0) [0|0] "" Vector__XXX
 SG_ RCM2_a431_presFrntLDoorSht2Bat_s m431 : 16|1@1+ (1,0) [0|0] "" Vector__XXX
 SG_ RCM2_a432_presFrntLDoorOpen_s m432 : 16|1@1+ (1,0) [0|0] "" Vector__XXX
 SG_ RCM2_a433_presFrntLDoorCrssCoup_s m433 : 16|1@1+ (1,0) [0|0] "" Vector__XXX
 SG_ RCM2_a434_presFrntLDoorCommErr_s m434 : 16|1@1+ (1,0) [0|0] "" Vector__XXX
 SG_ RCM2_a435_presFrntLDoorInitTyp_s m435 : 16|1@1+ (1,0) [0|0] "" Vector__XXX
 SG_ RCM2_a436_presFrntLDoorConfig_s m436 : 16|1@1+ (1,0) [0|0] "" Vector__XXX
 SG_ RCM2_a437_presFrntLDoorDefect_s m437 : 16|1@1+ (1,0) [0|0] "" Vector__XXX
 SG_ RCM2_a438_presFrntLDoorSigMon_s m438 : 16|1@1+ (1,0) [0|0] "" Vector__XXX
 SG_ RCM2_a439_presDoorAbsolute1_s m439 : 16|1@1+ (1,0) [0|0] "" Vector__XXX
 SG_ RCM2_a440_presFrntRDoorSht2Gnd_s m440 : 16|1@1+ (1,0) [0|0] "" Vector__XXX
 SG_ RCM2_a441_presFrntRDoorSht2Bat_s m441 : 16|1@1+ (1,0) [0|0] "" Vector__XXX
 SG_ RCM2_a442_presFrntRDoorOpen_s m442 : 16|1@1+ (1,0) [0|0] "" Vector__XXX
 SG_ RCM2_a443_presFrntRDoorCrssCoup_s m443 : 16|1@1+ (1,0) [0|0] "" Vector__XXX
 SG_ RCM2_a444_presFrntRDoorCommErr_s m444 : 16|1@1+ (1,0) [0|0] "" Vector__XXX
 SG_ RCM2_a445_presFrntRDoorInitTyp_s m445 : 16|1@1+ (1,0) [0|0] "" Vector__XXX
 SG_ RCM2_a446_presFrntRDoorConfig_s m446 : 16|1@1+ (1,0) [0|0] "" Vector__XXX
 SG_ RCM2_a447_presFrntRDoorDefect_s m447 : 16|1@1+ (1,0) [0|0] "" Vector__XXX
 SG_ RCM2_a448_presFrntRDoorSigMon_s m448 : 16|1@1+ (1,0) [0|0] "" Vector__XXX
 SG_ RCM2_a449_presDoorAbsolute2_s m449 : 16|1@1+ (1,0) [0|0] "" Vector__XXX
 SG_ RCM2_a450_presPedProLSht2Gnd_s m450 : 16|1@1+ (1,0) [0|0] "" Vector__XXX
 SG_ RCM2_a451_presPedProLSht2Bat_s m451 : 16|1@1+ (1,0) [0|0] "" Vector__XXX
 SG_ RCM2_a452_presPedProLOpen_s m452 : 16|1@1+ (1,0) [0|0] "" Vector__XXX
 SG_ RCM2_a453_presPedProLCrssCoup_s m453 : 16|1@1+ (1,0) [0|0] "" Vector__XXX
 SG_ RCM2_a454_presPedProLCommErr_s m454 : 16|1@1+ (1,0) [0|0] "" Vector__XXX
 SG_ RCM2_a455_presPedProLInitTyp_s m455 : 16|1@1+ (1,0) [0|0] "" Vector__XXX
 SG_ RCM2_a456_presPedProLConfig_s m456 : 16|1@1+ (1,0) [0|0] "" Vector__XXX
 SG_ RCM2_a457_presPedProLDefect_s m457 : 16|1@1+ (1,0) [0|0] "" Vector__XXX
 SG_ RCM2_a458_presPedProLSigMon_s m458 : 16|1@1+ (1,0) [0|0] "" Vector__XXX
 SG_ RCM2_a460_presPedProRSht2Gnd_s m460 : 16|1@1+ (1,0) [0|0] "" Vector__XXX
 SG_ RCM2_a461_presPedProRSht2Bat_s m461 : 16|1@1+ (1,0) [0|0] "" Vector__XXX
 SG_ RCM2_a462_presPedProROpen_s m462 : 16|1@1+ (1,0) [0|0] "" Vector__XXX
 SG_ RCM2_a463_presPedProRCrssCoup_s m463 : 16|1@1+ (1,0) [0|0] "" Vector__XXX
 SG_ RCM2_a464_presPedProRCommErr_s m464 : 16|1@1+ (1,0) [0|0] "" Vector__XXX
 SG_ RCM2_a465_presPedProRInitTyp_s m465 : 16|1@1+ (1,0) [0|0] "" Vector__XXX
 SG_ RCM2_a466_presPedProRConfig_s m466 : 16|1@1+ (1,0) [0|0] "" Vector__XXX
 SG_ RCM2_a467_presPedProRDefect_s m467 : 16|1@1+ (1,0) [0|0] "" Vector__XXX
 SG_ RCM2_a468_presPedProRSigMon_s m468 : 16|1@1+ (1,0) [0|0] "" Vector__XXX
 SG_ RCM2_a469_presPedProAbsolute_s m469 : 16|1@1+ (1,0) [0|0] "" Vector__XXX
 SG_ RCM2_a470_upFrntPedProLSht2Gnd_s m470 : 16|1@1+ (1,0) [0|0] "" Vector__XXX
 SG_ RCM2_a471_upFrntPedProLSht2Bat_s m471 : 16|1@1+ (1,0) [0|0] "" Vector__XXX
 SG_ RCM2_a472_upFrntPedProLOpen_s m472 : 16|1@1+ (1,0) [0|0] "" Vector__XXX
 SG_ RCM2_a473_upFrntPedProLCrssCoup_s m473 : 16|1@1+ (1,0) [0|0] "" Vector__XXX
 SG_ RCM2_a474_upFrntPedProLCommErr_s m474 : 16|1@1+ (1,0) [0|0] "" Vector__XXX
 SG_ RCM2_a475_upFrntPedProLIntTyp_s m475 : 16|1@1+ (1,0) [0|0] "" Vector__XXX
 SG_ RCM2_a476_upFrntPedProLConfig_s m476 : 16|1@1+ (1,0) [0|0] "" Vector__XXX
 SG_ RCM2_a477_upFrntPedProLDefect_s m477 : 16|1@1+ (1,0) [0|0] "" Vector__XXX
 SG_ RCM2_a478_upFrntPedProLSigMon_s m478 : 16|1@1+ (1,0) [0|0] "" Vector__XXX
 SG_ RCM2_a480_upFrntPedProRSht2Gnd_s m480 : 16|1@1+ (1,0) [0|0] "" Vector__XXX
 SG_ RCM2_a481_upFrntPedProRSht2Bat_s m481 : 16|1@1+ (1,0) [0|0] "" Vector__XXX
 SG_ RCM2_a482_upFrntPedProROpen_s m482 : 16|1@1+ (1,0) [0|0] "" Vector__XXX
 SG_ RCM2_a483_upFrntPedProRCrssCoup_s m483 : 16|1@1+ (1,0) [0|0] "" Vector__XXX
 SG_ RCM2_a484_upFrntPedProRCommErr_s m484 : 16|1@1+ (1,0) [0|0] "" Vector__XXX
 SG_ RCM2_a485_upFrntPedProRIntTyp_s m485 : 16|1@1+ (1,0) [0|0] "" Vector__XXX
 SG_ RCM2_a486_upFrntPedProRConfig_s m486 : 16|1@1+ (1,0) [0|0] "" Vector__XXX
 SG_ RCM2_a487_upFrntPedProRDefect_s m487 : 16|1@1+ (1,0) [0|0] "" Vector__XXX
 SG_ RCM2_a488_upFrntPedProRSigMon_s m488 : 16|1@1+ (1,0) [0|0] "" Vector__XXX
 SG_ RCM2_a490_presRearLDoorSht2Gnd_s m490 : 16|1@1+ (1,0) [0|0] "" Vector__XXX
 SG_ RCM2_a491_presRearLDoorSht2Bat_s m491 : 16|1@1+ (1,0) [0|0] "" Vector__XXX
 SG_ RCM2_a492_presRearLDoorOpen_s m492 : 16|1@1+ (1,0) [0|0] "" Vector__XXX
 SG_ RCM2_a493_presRearLDoorCrssCoup_s m493 : 16|1@1+ (1,0) [0|0] "" Vector__XXX
 SG_ RCM2_a494_presRearLDoorCommErr_s m494 : 16|1@1+ (1,0) [0|0] "" Vector__XXX
 SG_ RCM2_a495_presRearLDoorInitTyp_s m495 : 16|1@1+ (1,0) [0|0] "" Vector__XXX
 SG_ RCM2_a496_presRearLDoorConfig_s m496 : 16|1@1+ (1,0) [0|0] "" Vector__XXX
 SG_ RCM2_a497_presRearLDoorDefect_s m497 : 16|1@1+ (1,0) [0|0] "" Vector__XXX
 SG_ RCM2_a498_presRearLDoorSigMon_s m498 : 16|1@1+ (1,0) [0|0] "" Vector__XXX
 SG_ RCM2_a500_presRearRDoorSht2Gnd_s m500 : 16|1@1+ (1,0) [0|0] "" Vector__XXX
 SG_ RCM2_a501_presRearRDoorSht2Bat_s m501 : 16|1@1+ (1,0) [0|0] "" Vector__XXX
 SG_ RCM2_a502_presRearRDoorOpen_s m502 : 16|1@1+ (1,0) [0|0] "" Vector__XXX
 SG_ RCM2_a503_presRearRDoorCrssCoup_s m503 : 16|1@1+ (1,0) [0|0] "" Vector__XXX
 SG_ RCM2_a504_presRearRDoorCommErr_s m504 : 16|1@1+ (1,0) [0|0] "" Vector__XXX
 SG_ RCM2_a505_presRearRDoorInitTyp_s m505 : 16|1@1+ (1,0) [0|0] "" Vector__XXX
 SG_ RCM2_a506_presRearRDoorConfig_s m506 : 16|1@1+ (1,0) [0|0] "" Vector__XXX
 SG_ RCM2_a507_presRearRDoorDefect_s m507 : 16|1@1+ (1,0) [0|0] "" Vector__XXX
 SG_ RCM2_a508_presRearRDoorSigMon_s m508 : 16|1@1+ (1,0) [0|0] "" Vector__XXX
 SG_ RCM2_a509_sideAccelDPilLSht2Gnd_s m509 : 16|1@1+ (1,0) [0|0] "" Vector__XXX
 SG_ RCM2_a510_sideAccelDPilLSht2Bat_s m510 : 16|1@1+ (1,0) [0|0] "" Vector__XXX
 SG_ RCM2_a511_sideAccelDPilLOpen_s m511 : 16|1@1+ (1,0) [0|0] "" Vector__XXX
 SG_ RCM2_a512_sideAccelDPilLCrssCoup_s m512 : 16|1@1+ (1,0) [0|0] "" Vector__XXX
 SG_ RCM2_a513_sideAccelDPilLCommErr_s m513 : 16|1@1+ (1,0) [0|0] "" Vector__XXX
 SG_ RCM2_a514_sideAccelDPilLInitTyp_s m514 : 16|1@1+ (1,0) [0|0] "" Vector__XXX
 SG_ RCM2_a515_sideAccelDPilLConfig_s m515 : 16|1@1+ (1,0) [0|0] "" Vector__XXX
 SG_ RCM2_a516_sideAccelDPilLDefect_s m516 : 16|1@1+ (1,0) [0|0] "" Vector__XXX
 SG_ RCM2_a517_sideAccelDPilLSigMon_s m517 : 16|1@1+ (1,0) [0|0] "" Vector__XXX
 SG_ RCM2_a518_sideAccelDPilRSht2Gnd_s m518 : 16|1@1+ (1,0) [0|0] "" Vector__XXX
 SG_ RCM2_a519_sideAccelDPilRSht2Bat_s m519 : 16|1@1+ (1,0) [0|0] "" Vector__XXX
 SG_ RCM2_a520_sideAccelDPilROpen_s m520 : 16|1@1+ (1,0) [0|0] "" Vector__XXX
 SG_ RCM2_a521_sideAccelDPilRCrssCoup_s m521 : 16|1@1+ (1,0) [0|0] "" Vector__XXX
 SG_ RCM2_a522_sideAccelDPilRCommErr_s m522 : 16|1@1+ (1,0) [0|0] "" Vector__XXX
 SG_ RCM2_a523_sideAccelDPilRInitTyp_s m523 : 16|1@1+ (1,0) [0|0] "" Vector__XXX
 SG_ RCM2_a524_sideAccelDPilRConfig_s m524 : 16|1@1+ (1,0) [0|0] "" Vector__XXX
 SG_ RCM2_a525_sideAccelDPilRDefect_s m525 : 16|1@1+ (1,0) [0|0] "" Vector__XXX
 SG_ RCM2_a526_sideAccelDPilRSigMon_s m526 : 16|1@1+ (1,0) [0|0] "" Vector__XXX
 SG_ RCM2_a527_upFrntSnsrCSht2Gnd_s m527 : 16|1@1+ (1,0) [0|0] "" Vector__XXX
 SG_ RCM2_a528_upFrntSnsrCSht2Bat_s m528 : 16|1@1+ (1,0) [0|0] "" Vector__XXX
 SG_ RCM2_a529_upFrntSnsrCOpen_s m529 : 16|1@1+ (1,0) [0|0] "" Vector__XXX
 SG_ RCM2_a530_upFrntSnsrCCrssCoup_s m530 : 16|1@1+ (1,0) [0|0] "" Vector__XXX
 SG_ RCM2_a531_upFrntSnsrCCommErr_s m531 : 16|1@1+ (1,0) [0|0] "" Vector__XXX
 SG_ RCM2_a532_upFrntSnsrCInitTyp_s m532 : 16|1@1+ (1,0) [0|0] "" Vector__XXX
 SG_ RCM2_a533_upFrntSnsrCConfig_s m533 : 16|1@1+ (1,0) [0|0] "" Vector__XXX
 SG_ RCM2_a534_upFrntSnsrCDefect_s m534 : 16|1@1+ (1,0) [0|0] "" Vector__XXX
 SG_ RCM2_a535_upFrntSnsrCSigMon_s m535 : 16|1@1+ (1,0) [0|0] "" Vector__XXX
 SG_ RCM2_a550_bucklHallLeftSht2Gnd_s m550 : 16|1@1+ (1,0) [0|0] "" Vector__XXX
 SG_ RCM2_a551_bucklHallLeftSht2Bat_s m551 : 16|1@1+ (1,0) [0|0] "" Vector__XXX
 SG_ RCM2_a552_bucklHallLeftOpen_s m552 : 16|1@1+ (1,0) [0|0] "" Vector__XXX
 SG_ RCM2_a553_bucklHallLeftUndef_s m553 : 16|1@1+ (1,0) [0|0] "" Vector__XXX
 SG_ RCM2_a554_bucklHallLeftCrssCoup_s m554 : 16|1@1+ (1,0) [0|0] "" Vector__XXX
 SG_ RCM2_a555_bucklHallLeftConfig_s m555 : 16|1@1+ (1,0) [0|0] "" Vector__XXX
 SG_ RCM2_a556_bucklHallRightSht2Gnd_s m556 : 16|1@1+ (1,0) [0|0] "" Vector__XXX
 SG_ RCM2_a557_bucklHallRightSht2Bat_s m557 : 16|1@1+ (1,0) [0|0] "" Vector__XXX
 SG_ RCM2_a558_bucklHallRightOpen_s m558 : 16|1@1+ (1,0) [0|0] "" Vector__XXX
 SG_ RCM2_a559_bucklHallRightUndef_s m559 : 16|1@1+ (1,0) [0|0] "" Vector__XXX
 SG_ RCM2_a560_bucklHallRightCrssCoup_s m560 : 16|1@1+ (1,0) [0|0] "" Vector__XXX
 SG_ RCM2_a561_bucklHallRightConfig_s m561 : 16|1@1+ (1,0) [0|0] "" Vector__XXX
 SG_ RCM2_a562_seaTrkPosLeftSht2Gnd_s m562 : 16|1@1+ (1,0) [0|0] "" Vector__XXX
 SG_ RCM2_a563_seaTrkPosLeftShtBat_s m563 : 16|1@1+ (1,0) [0|0] "" Vector__XXX
 SG_ RCM2_a564_seaTrkPosLeftOpen_s m564 : 16|1@1+ (1,0) [0|0] "" Vector__XXX
 SG_ RCM2_a565_seaTrkPosLeftUndefined_s m565 : 16|1@1+ (1,0) [0|0] "" Vector__XXX
 SG_ RCM2_a566_seaTrkPosLeftCrssCoup_s m566 : 16|1@1+ (1,0) [0|0] "" Vector__XXX
 SG_ RCM2_a567_seaTrkPosLeftConfig_s m567 : 16|1@1+ (1,0) [0|0] "" Vector__XXX
 SG_ RCM2_a568_occPROSSht2Gnd_s m568 : 16|1@1+ (1,0) [0|0] "" Vector__XXX
 SG_ RCM2_a569_occPROSSht2Bat_s m569 : 16|1@1+ (1,0) [0|0] "" Vector__XXX
 SG_ RCM2_a570_occPROSOpen_s m570 : 16|1@1+ (1,0) [0|0] "" Vector__XXX
 SG_ RCM2_a571_occPROSUndef_s m571 : 16|1@1+ (1,0) [0|0] "" Vector__XXX
 SG_ RCM2_a572_occPROSCrssCoup_s m572 : 16|1@1+ (1,0) [0|0] "" Vector__XXX
 SG_ RCM2_a573_occPROSConfig_s m573 : 16|1@1+ (1,0) [0|0] "" Vector__XXX
 SG_ RCM2_a587_sbrRearNetworkSht2Gnd_s m587 : 16|1@1+ (1,0) [0|0] "" Vector__XXX
 SG_ RCM2_a588_sbrRearNetworkSht2Bat_s m588 : 16|1@1+ (1,0) [0|0] "" Vector__XXX
 SG_ RCM2_a589_sbrRearNetworkOpen_s m589 : 16|1@1+ (1,0) [0|0] "" Vector__XXX
 SG_ RCM2_a590_sbrRearNetworkUndefined_s m590 : 16|1@1+ (1,0) [0|0] "" Vector__XXX
 SG_ RCM2_a591_sbrRearNetworkCrssCoup_s m591 : 16|1@1+ (1,0) [0|0] "" Vector__XXX
 SG_ RCM2_a592_sbrRearNetworkConfig_s m592 : 16|1@1+ (1,0) [0|0] "" Vector__XXX
 SG_ RCM2_a593_driveOrientationSht2Gnd_s m593 : 16|1@1+ (1,0) [0|0] "" Vector__XXX
 SG_ RCM2_a594_driveOrientationSht2Bat_s m594 : 16|1@1+ (1,0) [0|0] "" Vector__XXX
 SG_ RCM2_a595_driveOrientationOpen_s m595 : 16|1@1+ (1,0) [0|0] "" Vector__XXX
 SG_ RCM2_a596_driveOrientationUndefined_s m596 : 16|1@1+ (1,0) [0|0] "" Vector__XXX
 SG_ RCM2_a597_driveOrientationCrssCoup_s m597 : 16|1@1+ (1,0) [0|0] "" Vector__XXX
 SG_ RCM2_a598_driveOrientationConfig_s m598 : 16|1@1+ (1,0) [0|0] "" Vector__XXX
 SG_ RCM2_a600_comCANinternalTimeout_s m600 : 16|1@1+ (1,0) [0|0] "" Vector__XXX
 SG_ RCM2_a601_comChassisCANSilent_s m601 : 16|1@1+ (1,0) [0|0] "" Vector__XXX
 SG_ RCM2_a602_comChassisCANBusOff_s m602 : 16|1@1+ (1,0) [0|0] "" Vector__XXX
 SG_ RCM2_a603_comPARTYCANSilent_s m603 : 16|1@1+ (1,0) [0|0] "" Vector__XXX
 SG_ RCM2_a604_comPARTYCANBusOff_s m604 : 16|1@1+ (1,0) [0|0] "" Vector__XXX
 SG_ RCM2_a605_comStwAngStatMIA_s m605 : 16|1@1+ (1,0) [0|0] "" Vector__XXX
 SG_ RCM2_a606_comStwAngStatChkSm_s m606 : 16|1@1+ (1,0) [0|0] "" Vector__XXX
 SG_ RCM2_a607_comStwAngStatCntr_s m607 : 16|1@1+ (1,0) [0|0] "" Vector__XXX
 SG_ RCM2_a608_comDItorque1MIA_s m608 : 16|1@1+ (1,0) [0|0] "" Vector__XXX
 SG_ RCM2_a609_comDItorque1ChkSm_s m609 : 16|1@1+ (1,0) [0|0] "" Vector__XXX
 SG_ RCM2_a610_comDItorque1Cntr_s m610 : 16|1@1+ (1,0) [0|0] "" Vector__XXX
 SG_ RCM2_a611_comDItorque2MIA_s m611 : 16|1@1+ (1,0) [0|0] "" Vector__XXX
 SG_ RCM2_a612_comDItorque2ChkSm_s m612 : 16|1@1+ (1,0) [0|0] "" Vector__XXX
 SG_ RCM2_a613_comDItorque2Cntr_s m613 : 16|1@1+ (1,0) [0|0] "" Vector__XXX
 SG_ RCM2_a614_comESP135MIA_s m614 : 16|1@1+ (1,0) [0|0] "" Vector__XXX
 SG_ RCM2_a615_comESP135ChkSm_s m615 : 16|1@1+ (1,0) [0|0] "" Vector__XXX
 SG_ RCM2_a616_comESP135Cntr_s m616 : 16|1@1+ (1,0) [0|0] "" Vector__XXX
 SG_ RCM2_a617_comESP145MIA_s m617 : 16|1@1+ (1,0) [0|0] "" Vector__XXX
 SG_ RCM2_a618_comESP145ChkSm_s m618 : 16|1@1+ (1,0) [0|0] "" Vector__XXX
 SG_ RCM2_a619_comESP145Cntr_s m619 : 16|1@1+ (1,0) [0|0] "" Vector__XXX
 SG_ RCM2_a620_comInvalidVehicleSpeed_s m620 : 16|1@1+ (1,0) [0|0] "" Vector__XXX
 SG_ RCM2_a621_comESPBMIA_s m621 : 16|1@1+ (1,0) [0|0] "" Vector__XXX
 SG_ RCM2_a622_comESPBChkSm_s m622 : 16|1@1+ (1,0) [0|0] "" Vector__XXX
 SG_ RCM2_a623_comESPBCntr_s m623 : 16|1@1+ (1,0) [0|0] "" Vector__XXX
 SG_ RCM2_a624_comESPCMIA_s m624 : 16|1@1+ (1,0) [0|0] "" Vector__XXX
 SG_ RCM2_a625_comESPCChkSm_s m625 : 16|1@1+ (1,0) [0|0] "" Vector__XXX
 SG_ RCM2_a626_comESPCCntr_s m626 : 16|1@1+ (1,0) [0|0] "" Vector__XXX
 SG_ RCM2_a627_comEPBStatusMIA_s m627 : 16|1@1+ (1,0) [0|0] "" Vector__XXX
 SG_ RCM2_a628_comEPBStatusChkSm_s m628 : 16|1@1+ (1,0) [0|0] "" Vector__XXX
 SG_ RCM2_a629_comEPBStatusCntr_s m629 : 16|1@1+ (1,0) [0|0] "" Vector__XXX
 SG_ RCM2_a630_comGTWACSMIA_s m630 : 16|1@1+ (1,0) [0|0] "" Vector__XXX
 SG_ RCM2_a631_comGTWACSChkSm_s m631 : 16|1@1+ (1,0) [0|0] "" Vector__XXX
 SG_ RCM2_a632_comGTWACSCntr_s m632 : 16|1@1+ (1,0) [0|0] "" Vector__XXX
 SG_ RCM2_a633_comOCS1PMIA_s m633 : 16|1@1+ (1,0) [0|0] "" Vector__XXX
 SG_ RCM2_a634_comOCS1PChkSm_s m634 : 16|1@1+ (1,0) [0|0] "" Vector__XXX
 SG_ RCM2_a635_comOCS1PCntr_s m635 : 16|1@1+ (1,0) [0|0] "" Vector__XXX
 SG_ RCM2_a636_ocsFaulted_s m636 : 16|1@1+ (1,0) [0|0] "" Vector__XXX
 SG_ RCM2_a637_ocsUnknown_s m637 : 16|1@1+ (1,0) [0|0] "" Vector__XXX
 SG_ RCM2_a638_comGTWodoMIA_s m638 : 16|1@1+ (1,0) [0|0] "" Vector__XXX
 SG_ RCM2_a639_comGTWCarStateMIA_s m639 : 16|1@1+ (1,0) [0|0] "" Vector__XXX
 SG_ RCM2_a640_comTPMSStatusCMIA_s m640 : 16|1@1+ (1,0) [0|0] "" Vector__XXX
 SG_ RCM2_a641_comGTWCarConfigMIA_s m641 : 16|1@1+ (1,0) [0|0] "" Vector__XXX
 SG_ RCM2_a642_comVINmessageMIA_s m642 : 16|1@1+ (1,0) [0|0] "" Vector__XXX
 SG_ RCM2_a643_comDASSafetyFrntMIA_s m643 : 16|1@1+ (1,0) [0|0] "" Vector__XXX
 SG_ RCM2_a644_comDASSafetyFrntChkSm_s m644 : 16|1@1+ (1,0) [0|0] "" Vector__XXX
 SG_ RCM2_a645_comDASSafetyFrntCntr_s m645 : 16|1@1+ (1,0) [0|0] "" Vector__XXX
 SG_ RCM2_a646_comDIstateMIA_s m646 : 16|1@1+ (1,0) [0|0] "" Vector__XXX
 SG_ RCM2_a647_comDIstateChkSm_s m647 : 16|1@1+ (1,0) [0|0] "" Vector__XXX
 SG_ RCM2_a648_comDIstateCntr_s m648 : 16|1@1+ (1,0) [0|0] "" Vector__XXX
 SG_ RCM2_a649_comDIstate2MIA_s m649 : 16|1@1+ (1,0) [0|0] "" Vector__XXX
 SG_ RCM2_a650_comDIstate2ChkSm_s m650 : 16|1@1+ (1,0) [0|0] "" Vector__XXX
 SG_ RCM2_a651_comDIstate2Cntr_s m651 : 16|1@1+ (1,0) [0|0] "" Vector__XXX
 SG_ RCM2_a652_ambientTempFaulted_s m652 : 16|1@1+ (1,0) [0|0] "" Vector__XXX
 SG_ RCM2_a653_comGTWESP1MIA_s m653 : 16|1@1+ (1,0) [0|0] "" Vector__XXX
 SG_ RCM2_a654_comGTWESP1ChkSm_s m654 : 16|1@1+ (1,0) [0|0] "" Vector__XXX
 SG_ RCM2_a655_comGTWESP1Cntr_s m655 : 16|1@1+ (1,0) [0|0] "" Vector__XXX
 SG_ RCM2_a656_comVCSEATPrestMIA_s m656 : 16|1@1+ (1,0) [0|0] "" Vector__XXX
 SG_ RCM2_a657_comVCSEATPrestChkSm_s m657 : 16|1@1+ (1,0) [0|0] "" Vector__XXX
 SG_ RCM2_a658_comVCSEATPrestCntr_s m658 : 16|1@1+ (1,0) [0|0] "" Vector__XXX
 SG_ RCM2_a659_comVCSEATPbuckle_s m659 : 16|1@1+ (1,0) [0|0] "" Vector__XXX
 SG_ RCM2_a660_comVCSEATPOccpy_s m660 : 16|1@1+ (1,0) [0|0] "" Vector__XXX
 SG_ RCM2_a661_comVCSEATPocs_s m661 : 16|1@1+ (1,0) [0|0] "" Vector__XXX
 SG_ RCM2_a662_comVCSEATPstps_s m662 : 16|1@1+ (1,0) [0|0] "" Vector__XXX
 SG_ RCM2_a663_comVCSEATDrestMIA_s m663 : 16|1@1+ (1,0) [0|0] "" Vector__XXX
 SG_ RCM2_a664_comVCSEATDrestChkSm_s m664 : 16|1@1+ (1,0) [0|0] "" Vector__XXX
 SG_ RCM2_a665_comVCSEATDrestCntr_s m665 : 16|1@1+ (1,0) [0|0] "" Vector__XXX
 SG_ RCM2_a666_comVCSEATDbuckle_s m666 : 16|1@1+ (1,0) [0|0] "" Vector__XXX
 SG_ RCM2_a667_comVCSEATDOccpy_s m667 : 16|1@1+ (1,0) [0|0] "" Vector__XXX
 SG_ RCM2_a668_comVCSEATDstps_s m668 : 16|1@1+ (1,0) [0|0] "" Vector__XXX
 SG_ RCM2_a669_comEPBLstatusMIA_s m669 : 16|1@1+ (1,0) [0|0] "" Vector__XXX
 SG_ RCM2_a670_comEPBLstatusChkSm_s m670 : 16|1@1+ (1,0) [0|0] "" Vector__XXX
 SG_ RCM2_a671_comEPBLstatusCntr_s m671 : 16|1@1+ (1,0) [0|0] "" Vector__XXX
 SG_ RCM2_a672_comEPBRstatusMIA_s m672 : 16|1@1+ (1,0) [0|0] "" Vector__XXX
 SG_ RCM2_a673_comEPBRstatusChkSm_s m673 : 16|1@1+ (1,0) [0|0] "" Vector__XXX
 SG_ RCM2_a674_comEPBRstatusCntr_s m674 : 16|1@1+ (1,0) [0|0] "" Vector__XXX
 SG_ RCM2_a675_comUIodoMIA_s m675 : 16|1@1+ (1,0) [0|0] "" Vector__XXX
 SG_ RCM2_a676_comEPAS3PsysMIA_s m676 : 16|1@1+ (1,0) [0|0] "" Vector__XXX
 SG_ RCM2_a677_comEPAS3PsysChkSm_s m677 : 16|1@1+ (1,0) [0|0] "" Vector__XXX
 SG_ RCM2_a678_comEPAS3PsysCntr_s m678 : 16|1@1+ (1,0) [0|0] "" Vector__XXX
 SG_ RCM2_a679_comESPwheelSpeedsMIA_s m679 : 16|1@1+ (1,0) [0|0] "" Vector__XXX
 SG_ RCM2_a680_comESPwheelSpeedsChkSm_s m680 : 16|1@1+ (1,0) [0|0] "" Vector__XXX
 SG_ RCM2_a681_comESPwheelSpeedsCntr_s m681 : 16|1@1+ (1,0) [0|0] "" Vector__XXX
 SG_ RCM2_a682_comDIspeedMIA_s m682 : 16|1@1+ (1,0) [0|0] "" Vector__XXX
 SG_ RCM2_a683_comDIspeedChkSm_s m683 : 16|1@1+ (1,0) [0|0] "" Vector__XXX
 SG_ RCM2_a684_comDIspeedCntr_s m684 : 16|1@1+ (1,0) [0|0] "" Vector__XXX
 SG_ RCM2_a685_comDIchassControlMIA_s m685 : 16|1@1+ (1,0) [0|0] "" Vector__XXX
 SG_ RCM2_a686_comDIchassControlChkSm_s m686 : 16|1@1+ (1,0) [0|0] "" Vector__XXX
 SG_ RCM2_a687_comDIchassControlCntr_s m687 : 16|1@1+ (1,0) [0|0] "" Vector__XXX
 SG_ RCM2_a688_comVCLEFTrestMIA_s m688 : 16|1@1+ (1,0) [0|0] "" Vector__XXX
 SG_ RCM2_a689_comVCLEFTrestChkSm_s m689 : 16|1@1+ (1,0) [0|0] "" Vector__XXX
 SG_ RCM2_a690_comVCLEFTrestCntr_s m690 : 16|1@1+ (1,0) [0|0] "" Vector__XXX
 SG_ RCM2_a691_comVCLEFT1rLBuckle_s m691 : 16|1@1+ (1,0) [0|0] "" Vector__XXX
 SG_ RCM2_a692_comVCLEFT2rLBuckle_s m692 : 16|1@1+ (1,0) [0|0] "" Vector__XXX
 SG_ RCM2_a693_comVCLEFT1rLSTPS_s m693 : 16|1@1+ (1,0) [0|0] "" Vector__XXX
 SG_ RCM2_a694_comVCRIGHTrestMIA_s m694 : 16|1@1+ (1,0) [0|0] "" Vector__XXX
 SG_ RCM2_a695_comVCRIGHTrestChkSm_s m695 : 16|1@1+ (1,0) [0|0] "" Vector__XXX
 SG_ RCM2_a696_comVCRIGHTrestCntr_s m696 : 16|1@1+ (1,0) [0|0] "" Vector__XXX
 SG_ RCM2_a697_comVCRIGHT1rRBuckle_s m697 : 16|1@1+ (1,0) [0|0] "" Vector__XXX
 SG_ RCM2_a698_comVCRIGHT2rRBuckle_s m698 : 16|1@1+ (1,0) [0|0] "" Vector__XXX
 SG_ RCM2_a699_comVCRIGHTocs_s m699 : 16|1@1+ (1,0) [0|0] "" Vector__XXX
 SG_ RCM2_a700_comVCRIGHT1rRSTPS_s m700 : 16|1@1+ (1,0) [0|0] "" Vector__XXX
 SG_ RCM2_a701_comVCSECtpmsStatusMIA_s m701 : 16|1@1+ (1,0) [0|0] "" Vector__XXX
 SG_ RCM2_a750_linInternalTimeout_s m750 : 16|1@1+ (1,0) [0|0] "" Vector__XXX
 SG_ RCM2_a799_internalFault_s m799 : 16|1@1+ (1,0) [0|0] "" Vector__XXX
 SG_ RCM2_a800_crcFault_s m800 : 16|1@1+ (1,0) [0|0] "" Vector__XXX
 SG_ RCM2_a801_parameterLayoutID_s m801 : 16|1@1+ (1,0) [0|0] "" Vector__XXX
 SG_ RCM2_a802_parameterTransferID_s m802 : 16|1@1+ (1,0) [0|0] "" Vector__XXX
 SG_ RCM2_a803_algoVerifySensorID_s m803 : 16|1@1+ (1,0) [0|0] "" Vector__XXX
 SG_ RCM2_a804_configDataInconsistent_s m804 : 16|1@1+ (1,0) [0|0] "" Vector__XXX
 SG_ RCM2_a805_swVersionWrong_s m805 : 16|1@1+ (1,0) [0|0] "" Vector__XXX
 SG_ RCM2_a806_configVINnotLearned_s m806 : 16|1@1+ (1,0) [0|0] "" Vector__XXX
 SG_ RCM2_a807_configVINmismatch_s m807 : 16|1@1+ (1,0) [0|0] "" Vector__XXX
 SG_ RCM2_a808_configDriveNotLearned_s m808 : 16|1@1+ (1,0) [0|0] "" Vector__XXX
 SG_ RCM2_a809_configDriveMismatch_s m809 : 16|1@1+ (1,0) [0|0] "" Vector__XXX
 SG_ RCM2_a810_bootUpActionFailure_s m810 : 16|1@1+ (1,0) [0|0] "" Vector__XXX
 SG_ RCM2_a811_comAxleSpeed_s m811 : 16|1@1+ (1,0) [0|0] "" Vector__XXX
 SG_ RCM2_a812_idfMisuseMonitoringErr_s m812 : 16|1@1+ (1,0) [0|0] "" Vector__XXX
 SG_ RCM2_a813_idfEnviMonitoringError_s m813 : 16|1@1+ (1,0) [0|0] "" Vector__XXX
 SG_ RCM2_a814_idfEnviMonitoringEvent_s m814 : 16|1@1+ (1,0) [0|0] "" Vector__XXX
 SG_ RCM2_a815_upFrntPedProMLSht2Gnd_s m815 : 16|1@1+ (1,0) [0|0] "" Vector__XXX
 SG_ RCM2_a816_upFrntPedProMLSht2Bat_s m816 : 16|1@1+ (1,0) [0|0] "" Vector__XXX
 SG_ RCM2_a817_upFrntPedProMLOpen_s m817 : 16|1@1+ (1,0) [0|0] "" Vector__XXX
 SG_ RCM2_a818_upFrntPedProMLCrssCoup_s m818 : 16|1@1+ (1,0) [0|0] "" Vector__XXX
 SG_ RCM2_a819_upFrntPedProMLCommErr_s m819 : 16|1@1+ (1,0) [0|0] "" Vector__XXX
 SG_ RCM2_a820_upFrntPedProMLIntTyp_s m820 : 16|1@1+ (1,0) [0|0] "" Vector__XXX
 SG_ RCM2_a821_upFrntPedProMLConfig_s m821 : 16|1@1+ (1,0) [0|0] "" Vector__XXX
 SG_ RCM2_a822_upFrntPedProMLDefect_s m822 : 16|1@1+ (1,0) [0|0] "" Vector__XXX
 SG_ RCM2_a823_upFrntPedProMLSigMon_s m823 : 16|1@1+ (1,0) [0|0] "" Vector__XXX
 SG_ RCM2_a824_upFrntPedProMRSht2Gnd_s m824 : 16|1@1+ (1,0) [0|0] "" Vector__XXX
 SG_ RCM2_a825_upFrntPedProMRSht2Bat_s m825 : 16|1@1+ (1,0) [0|0] "" Vector__XXX
 SG_ RCM2_a826_upFrntPedProMROpen_s m826 : 16|1@1+ (1,0) [0|0] "" Vector__XXX
 SG_ RCM2_a827_upFrntPedProMRCrssCoup_s m827 : 16|1@1+ (1,0) [0|0] "" Vector__XXX
 SG_ RCM2_a828_upFrntPedProMRCommErr_s m828 : 16|1@1+ (1,0) [0|0] "" Vector__XXX
 SG_ RCM2_a829_upFrntPedProMRIntTyp_s m829 : 16|1@1+ (1,0) [0|0] "" Vector__XXX
 SG_ RCM2_a830_upFrntPedProMRConfig_s m830 : 16|1@1+ (1,0) [0|0] "" Vector__XXX
 SG_ RCM2_a831_upFrntPedProMRDefect_s m831 : 16|1@1+ (1,0) [0|0] "" Vector__XXX
 SG_ RCM2_a832_upFrntPedProMRSigMon_s m832 : 16|1@1+ (1,0) [0|0] "" Vector__XXX
 SG_ RCM2_a833_pretenShldCSht2Gnd_s m833 : 16|1@1+ (1,0) [0|0] "" Vector__XXX
 SG_ RCM2_a834_pretenShldCSht2Bat_s m834 : 16|1@1+ (1,0) [0|0] "" Vector__XXX
 SG_ RCM2_a835_pretenShldCOpen_s m835 : 16|1@1+ (1,0) [0|0] "" Vector__XXX
 SG_ RCM2_a836_pretenShldCShort_s m836 : 16|1@1+ (1,0) [0|0] "" Vector__XXX
 SG_ RCM2_a837_pretenShldCCrossC_s m837 : 16|1@1+ (1,0) [0|0] "" Vector__XXX
 SG_ RCM2_a838_pretenShldCConfig_s m838 : 16|1@1+ (1,0) [0|0] "" Vector__XXX
 SG_ RCM2_a839_preten2ndRowCSht2Gnd_s m839 : 16|1@1+ (1,0) [0|0] "" Vector__XXX
 SG_ RCM2_a840_preten2ndRowCSht2Bat_s m840 : 16|1@1+ (1,0) [0|0] "" Vector__XXX
 SG_ RCM2_a841_preten2ndRowCOpen_s m841 : 16|1@1+ (1,0) [0|0] "" Vector__XXX
 SG_ RCM2_a842_preten2ndRowCShort_s m842 : 16|1@1+ (1,0) [0|0] "" Vector__XXX
 SG_ RCM2_a843_preten2ndRowCCrssCoup_s m843 : 16|1@1+ (1,0) [0|0] "" Vector__XXX
 SG_ RCM2_a844_preten2ndRowCConfig_s m844 : 16|1@1+ (1,0) [0|0] "" Vector__XXX
 SG_ RCM2_a845_comUIchassisControlMIA_s m845 : 16|1@1+ (1,0) [0|0] "" Vector__XXX
 SG_ RCM2_a846_comSCCMstrAnglSnsMIA_s m846 : 16|1@1+ (1,0) [0|0] "" Vector__XXX
 SG_ RCM2_a847_comDASctrlMIA_s m847 : 16|1@1+ (1,0) [0|0] "" Vector__XXX
 SG_ RCM2_a848_comDIlocStatMIA_s m848 : 16|1@1+ (1,0) [0|0] "" Vector__XXX
 SG_ RCM2_a849_comIBSTparty1MIA_s m849 : 16|1@1+ (1,0) [0|0] "" Vector__XXX
 SG_ RCM2_a850_comVCFRONTlightingMIA_s m850 : 16|1@1+ (1,0) [0|0] "" Vector__XXX
 SG_ RCM2_a851_internalFaultTemp_s m851 : 16|1@1+ (1,0) [0|0] "" Vector__XXX
 SG_ RCM2_a852_autarkyEvent_s m852 : 16|1@1+ (1,0) [0|0] "" Vector__XXX
 SG_ RCM2_a853_ConfigParametersInconsistent_s m853 : 16|1@1+ (1,0) [0|0] "" Vector__XXX
 SG_ RCM2_a854_ConfigParametersNotLearned_s m854 : 16|1@1+ (1,0) [0|0] "" Vector__XXX
 SG_ RCM2_a857_comVCLEFT2rCBuckle_s m857 : 16|1@1+ (1,0) [0|0] "" Vector__XXX
 SG_ RCM2_a858_comVCxLVPowerStateMIA_s m858 : 16|1@1+ (1,0) [0|0] "" Vector__XXX
 SG_ RCM2_a859_comVCxLVPowerStateChkSm_s m859 : 16|1@1+ (1,0) [0|0] "" Vector__XXX
 SG_ RCM2_a860_comVCxLVPowerStateCntr_s m860 : 16|1@1+ (1,0) [0|0] "" Vector__XXX
 SG_ RCM2_a861_typeApprovalStringNotLearned_s m861 : 16|1@1+ (1,0) [0|0] "" Vector__XXX
 SG_ RCM2_a862_comPCSalertMatrixMIA_s m862 : 16|1@1+ (1,0) [0|0] "" Vector__XXX
 SG_ RCM2_a863_comVCFRONTalertMatrixMIA_s m863 : 16|1@1+ (1,0) [0|0] "" Vector__XXX
 SG_ RCM2_a864_comGTWepochTimeMIA_s m864 : 16|1@1+ (1,0) [0|0] "" Vector__XXX
 SG_ RCM2_a865_comVCLVBMSstatusHighMIA_s m865 : 16|1@1+ (1,0) [0|0] "" Vector__XXX
 SG_ RCM2_a866_comDASstatusMIA_s m866 : 16|1@1+ (1,0) [0|0] "" Vector__XXX
 SG_ RCM2_a868_headAB3rdRowRSht2Gnd_s m868 : 16|1@1+ (1,0) [0|0] "" Vector__XXX
 SG_ RCM2_a869_headAB3rdRowRSht2Bat_s m869 : 16|1@1+ (1,0) [0|0] "" Vector__XXX
 SG_ RCM2_a870_headAB3rdRowROpen_s m870 : 16|1@1+ (1,0) [0|0] "" Vector__XXX
 SG_ RCM2_a871_headAB3rdRowRShort_s m871 : 16|1@1+ (1,0) [0|0] "" Vector__XXX
 SG_ RCM2_a872_headAB3rdRowRCrossC_s m872 : 16|1@1+ (1,0) [0|0] "" Vector__XXX
 SG_ RCM2_a873_headAB3rdRowRConfig_s m873 : 16|1@1+ (1,0) [0|0] "" Vector__XXX
 SG_ RCM2_a874_headAB3rdRowLSht2Gnd_s m874 : 16|1@1+ (1,0) [0|0] "" Vector__XXX
 SG_ RCM2_a875_headAB3rdRowLSht2Bat_s m875 : 16|1@1+ (1,0) [0|0] "" Vector__XXX
 SG_ RCM2_a876_headAB3rdRowLOpen_s m876 : 16|1@1+ (1,0) [0|0] "" Vector__XXX
 SG_ RCM2_a877_headAB3rdRowLShort_s m877 : 16|1@1+ (1,0) [0|0] "" Vector__XXX
 SG_ RCM2_a878_headAB3rdRowLCrossC_s m878 : 16|1@1+ (1,0) [0|0] "" Vector__XXX
 SG_ RCM2_a879_headAB3rdRowLConfig_s m879 : 16|1@1+ (1,0) [0|0] "" Vector__XXX
 SG_ RCM2_a880_comVCLEFT3rLBuckle_s m880 : 16|1@1+ (1,0) [0|0] "" Vector__XXX
 SG_ RCM2_a881_comVCRIGHT3rRBuckle_s m881 : 16|1@1+ (1,0) [0|0] "" Vector__XXX
 SG_ RCM2_a000_crashDetectedRear m0 : 17|1@1+ (1,0) [0|0] "" Vector__XXX
 SG_ RCM2_a001_nearDeployRear m1 : 17|1@1+ (1,0) [0|0] "" Vector__XXX
 SG_ RCM2_a004_crashAlgoWakeupFront m4 : 17|1@1+ (1,0) [0|0] "" Vector__XXX
 SG_ RCM2_a017_ecuLogReason m17 : 17|6@1+ (1,0) [0|0] "" Vector__XXX
 SG_ RCM2_a000_crashDetectedLeft m0 : 18|1@1+ (1,0) [0|0] "" Vector__XXX
 SG_ RCM2_a001_nearDeployLeft m1 : 18|1@1+ (1,0) [0|0] "" Vector__XXX
 SG_ RCM2_a004_crashAlgoWakeupSide m4 : 18|1@1+ (1,0) [0|0] "" Vector__XXX
 SG_ RCM2_a000_crashDetectedRight m0 : 19|1@1+ (1,0) [0|0] "" Vector__XXX
 SG_ RCM2_a001_nearDeployRight m1 : 19|1@1+ (1,0) [0|0] "" Vector__XXX
 SG_ RCM2_a004_crashAlgoWakeupRear m4 : 19|1@1+ (1,0) [0|0] "" Vector__XXX
 SG_ RCM2_a000_crashDetectedRoll m0 : 20|1@1+ (1,0) [0|0] "" Vector__XXX
 SG_ RCM2_a001_nearDeployRoll m1 : 20|1@1+ (1,0) [0|0] "" Vector__XXX
 SG_ RCM2_a004_crashAlgoWakeupRoll m4 : 20|1@1+ (1,0) [0|0] "" Vector__XXX
 SG_ RCM2_a000_crashDetectedPreten m0 : 21|1@1+ (1,0) [0|0] "" Vector__XXX
 SG_ RCM2_a004_crashAlgoWakeupPedPro m4 : 21|1@1+ (1,0) [0|0] "" Vector__XXX
 SG_ RCM2_a000_crashDetectedStage1 m0 : 22|1@1+ (1,0) [0|0] "" Vector__XXX
 SG_ RCM2_a004_crashAlgoWakeupOffZone m4 : 22|1@1+ (1,0) [0|0] "" Vector__XXX
 SG_ RCM2_a000_crashDetectedStage2 m0 : 23|1@1+ (1,0) [0|0] "" Vector__XXX
 SG_ RCM2_a000_crashDetectedHVpyro m0 : 24|1@1+ (1,0) [0|0] "" Vector__XXX
 SG_ RCM2_eventArmStatus : 25|1@1+ (1,0) [0|0] "" Vector__XXX
 SG_ RCM2_eventFactoryMode : 26|1@1+ (1,0) [0|0] "" Vector__XXX
 SG_ RCM2_a000_crashDetectedOffZone m0 : 27|1@1+ (1,0) [0|0] "" Vector__XXX
 SG_ RCM2_eventDriveOrientation : 28|1@1+ (1,0) [0|0] "" Vector__XXX
 SG_ RCM2_eventIDFsignal : 29|1@1+ (1,0) [0|0] "" Vector__XXX
 SG_ RCM2_eventFrontLeftSeatbelt : 30|1@1+ (1,0) [0|0] "" Vector__XXX
 SG_ RCM2_eventFrontRightSeatbelt : 31|1@1+ (1,0) [0|0] "" Vector__XXX
 SG_ RCM2_eventVehicleSpeed : 32|12@1+ (0.08,-40) [0|0] "" Vector__XXX
 SG_ RCM2_eventDriverBrakeApply : 44|2@1+ (1,0) [0|0] "" Vector__XXX
 SG_ RCM2_eventAccelPedalPos : 56|8@1+ (0.4,0) [0|0] "" Vector__XXX

BO_ 1252 RCM3_alertLog: 8 Vector__XXX
 SG_ RCM3_alertID M : 0|1@1+ (1,0) [0|0] "" Vector__XXX
 SG_ RCM3_a001_LVPowerLossEventIndex m1 : 1|4@1+ (1,0) [0|0] "" Vector__XXX
 SG_ RCM3_a001_lastVCFRONTAlertID m1 : 5|10@1+ (1,0) [0|0] "" Vector__XXX
 SG_ RCM3_alertState : 15|1@1+ (1,0) [0|0] "" Vector__XXX
 SG_ RCM3_a001_timeEpochms m1 : 16|41@1+ (1,0) [0|0] "" Vector__XXX
 SG_ RCM3_a001_lastPCSAlertID m1 : 57|7@1+ (1,0) [0|0] "" Vector__XXX
